VERSION ""

NS_ :

BS_:

BU_: PowertrainControlModule AtmosphericSensor SafetyRestraintSystem2 Aftertreatment_2_GasOutlet Aftertreatment_2_GasIntake DieselParticulateFilterControl Turbocharger SafetyRestraintSystem1 CabDisplay2 Aftertreatment_1_GasOutlet Aftertreatment_1_GasIntake OnBoardDataLogger OffBoardDiagnosticTool2 OffBoardDiagnosticTool1 FileServer ParkingBrakeController SeatController2 FanDriveController SteeringColumnUnit CommunicationUnitRadio CommunicationUnitSatellite CommunicationUnitCellular PropulsionBatteryCharger ChassisController2 ChassisController1 EngineValveControl AuxiliaryHeater2 AuxiliaryHeater1 ClutchUnit RampControl InformationSystem1 SuspensionSystemController2 OilSensor VehicleDynamicStability ExhaustEmissionController TransmissionDisplay2 TransmissionDisplay1 ClimateControl2 WaterPumpController RearAxleSteeringController LightingOperatorControl SeatController1 IgnitionController2 IgnitionController1 TirePressureController CabController2 CabController1 PneumaticSystemController SuspensionSystemController1 HydraulicPumpController EnduranceBrakingSystem RetarderExhaustEngine2 OnBoardDiagnosticUnit HeadwayController RetarderExhaustEngine1 CabDisplay1 ManagementComputer VirtualTerminal OffVehicleGateway PowerTakeOffFront HitchControl AuxiliaryValveControl BodyController TractorTrailerBridge1 StarterSystem ElectricalSystem VehicleSecurity VehicleNavigation AerodynamicControl ElectricalChargingSystem ClimateControl1 TripRecorder InstrumentCluster SuspensionDriveAxle2 SuspensionDriveAxle1 SuspensionSteerAxle SteeringController FuelSystem CruiseControl RetarderDriveline RetarderEngine BrakesDriveAxle2 BrakesDriveAxle1 BrakesSystemController BrakesSteerAxle AxleDrive2 AxleDrive1 AxleSteering PowerTakeOff ShiftConsoleSecondary ShiftConsolePrimary Transmission2 Transmission1 Engine2 Engine1
VAL_TABLE_ FMI 0 "Above normal (most severe)" 1 "Below normal (most severe)" 2 "Data erratic" 3 "Voltage above normal" 4 "Voltage below normal" 5 "Current below normal" 6 "Current above normal" 7 "Mechanical system not responding" 8 "Abnormal frequency" 9 "Abnormal update rate" 10 "Abnormal rate of change" 11 "Root cause not known" 12 "Bad intelligent device" 13 "Out of calibration" 14 "Special intstructions" 15 "Above normal (least severe)" 16 "Above normal (moderately severe)" 17 "Below normal (least severe)" 18 "Below normal (moderately severe)" 19 "Received network data in error" 31 "Not available" ;
VAL_TABLE_ TireLocation_MUX 51 "TirePress_33_MUX_51" 50 "TirePress_32_MUX_50" 49 "TirePress_31_MUX_49" 48 "TirePress_30_MUX_48" 35 "TirePress_23_MUX_35" 34 "TirePress_22_MUX_34" 33 "TirePress_21_MUX_33" 32 "TirePress_20_MUX_32" 19 "TirePress_13_MUX_19" 18 "TirePress_12_MUX_18" 17 "TirePress_11_MUX_17" 16 "TirePress_10_MUX_16" 1 "TirePress_01_MUX_1" 0 "TirePress_00_MUX_0" ;

BO_ 2147483936 The11BitCANIDMessage: 8 Vector__XXX
 SG_ ABSOffroadRequest : 0|2@1+ (1,0) [0|1] "" Vector__XXX

BO_ 2381315838 PropA2: 8 Vector__XXX
 SG_ ManufacturerSpecificInformation : 0|64@1+ (1,0) [0|0] "" Vector__XXX

BO_ 2365510142 DM09: 8 Vector__XXX

BO_ 2365475326 GBSD: 8 Vector__XXX
 SG_ GroundBasedDirection : 56|2@1+ (1,0) [0|0] "" Vector__XXX
 SG_ GroundBasedImplementDistance : 16|32@1+ (1,0) [0|0] "" Vector__XXX
 SG_ GroundBasedImplementSpeed : 0|16@1+ (1,0) [0|0] "" Vector__XXX

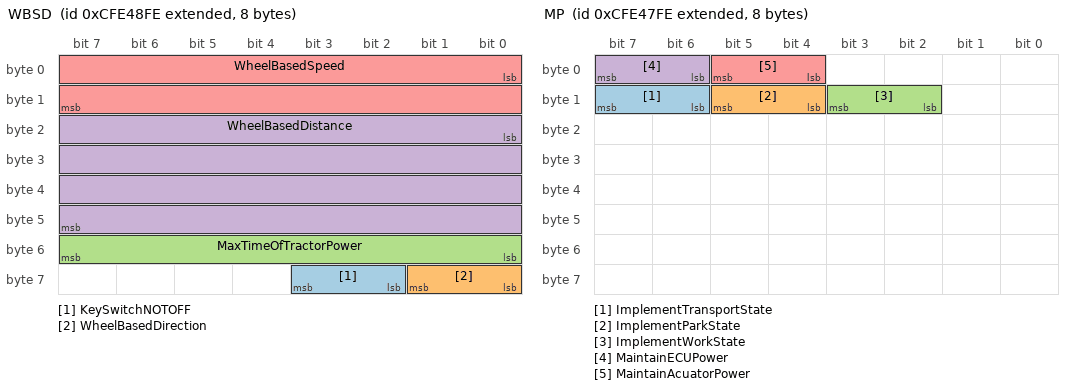
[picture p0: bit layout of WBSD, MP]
BO_ 2365475070 WBSD: 8 Vector__XXX
 SG_ KeySwitchNOTOFF : 58|2@1+ (1,0) [0|0] "" Vector__XXX
 SG_ WheelBasedDirection : 56|2@1+ (1,0) [0|0] "" Vector__XXX
 SG_ MaxTimeOfTractorPower : 48|8@1+ (1,0) [0|0] "" Vector__XXX
 SG_ WheelBasedDistance : 16|32@1+ (1,0) [0|0] "" Vector__XXX
 SG_ WheelBasedSpeed : 0|16@1+ (1,0) [0|0] "" Vector__XXX

BO_ 2365474814 MP: 8 Vector__XXX
 SG_ ImplementTransportState : 14|2@1+ (1,0) [0|0] "" Vector__XXX
 SG_ ImplementParkState : 12|2@1+ (1,0) [0|0] "" Vector__XXX
 SG_ ImplementWorkState : 10|2@1+ (1,0) [0|0] "" Vector__XXX
 SG_ MaintainECUPower : 6|2@1+ (1,0) [0|0] "" Vector__XXX
 SG_ MaintainAcuatorPower : 4|2@1+ (1,0) [0|0] "" Vector__XXX

BO_ 2365474558 FHS: 8 Vector__XXX
 SG_ FrontDraft : 24|16@1+ (1,0) [0|0] "" Vector__XXX
 SG_ FrontNominalLowerLinkForce : 16|8@1+ (1,0) [0|0] "" Vector__XXX
 SG_ FrontHitchInworkIndication : 14|2@1+ (1,0) [0|0] "" Vector__XXX
 SG_ FrontHitchPos : 0|8@1+ (1,0) [0|0] "" Vector__XXX

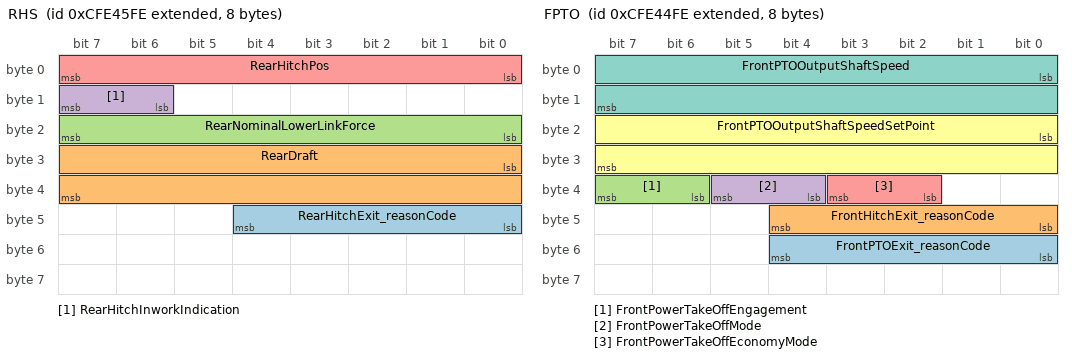
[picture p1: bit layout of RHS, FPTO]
BO_ 2365474302 RHS: 8 Vector__XXX
 SG_ RearHitchExit_reasonCode : 40|5@1+ (1,0) [0|0] "" Vector__XXX
 SG_ RearDraft : 24|16@1+ (1,0) [0|0] "" Vector__XXX
 SG_ RearNominalLowerLinkForce : 16|8@1+ (1,0) [0|0] "" Vector__XXX
 SG_ RearHitchInworkIndication : 14|2@1+ (1,0) [0|0] "" Vector__XXX
 SG_ RearHitchPos : 0|8@1+ (1,0) [0|0] "" Vector__XXX

BO_ 2365474046 FPTO: 8 Vector__XXX
 SG_ FrontPTOExit_reasonCode : 48|5@1+ (1,0) [0|0] "" Vector__XXX
 SG_ FrontHitchExit_reasonCode : 40|5@1+ (1,0) [0|0] "" Vector__XXX
 SG_ FrontPowerTakeOffEngagement : 38|2@1+ (1,0) [0|0] "" Vector__XXX
 SG_ FrontPowerTakeOffMode : 36|2@1+ (1,0) [0|0] "" Vector__XXX
 SG_ FrontPowerTakeOffEconomyMode : 34|2@1+ (1,0) [0|0] "" Vector__XXX
 SG_ FrontPTOOutputShaftSpeedSetPoint : 16|16@1+ (1,0) [0|0] "" Vector__XXX
 SG_ FrontPTOOutputShaftSpeed : 0|16@1+ (1,0) [0|0] "" Vector__XXX

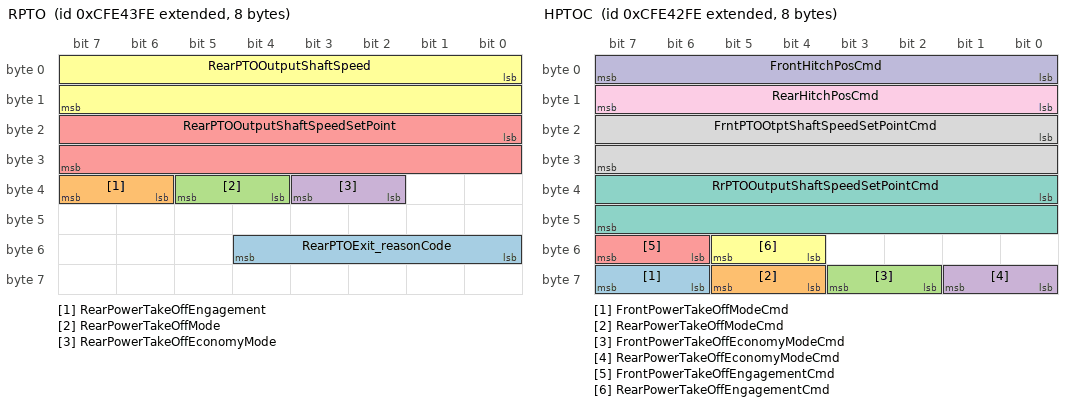
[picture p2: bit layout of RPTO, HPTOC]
BO_ 2365473790 RPTO: 8 Vector__XXX
 SG_ RearPTOExit_reasonCode : 48|5@1+ (1,0) [0|0] "" Vector__XXX
 SG_ RearPowerTakeOffEngagement : 38|2@1+ (1,0) [0|0] "" Vector__XXX
 SG_ RearPowerTakeOffMode : 36|2@1+ (1,0) [0|0] "" Vector__XXX
 SG_ RearPowerTakeOffEconomyMode : 34|2@1+ (1,0) [0|0] "" Vector__XXX
 SG_ RearPTOOutputShaftSpeedSetPoint : 16|16@1+ (1,0) [0|0] "" Vector__XXX
 SG_ RearPTOOutputShaftSpeed : 0|16@1+ (1,0) [0|0] "" Vector__XXX

BO_ 2365473534 HPTOC: 8 Vector__XXX
 SG_ FrontPowerTakeOffModeCmd : 62|2@1+ (1,0) [0|0] "" Vector__XXX
 SG_ RearPowerTakeOffModeCmd : 60|2@1+ (1,0) [0|0] "" Vector__XXX
 SG_ FrontPowerTakeOffEconomyModeCmd : 58|2@1+ (1,0) [0|0] "" Vector__XXX
 SG_ RearPowerTakeOffEconomyModeCmd : 56|2@1+ (1,0) [0|0] "" Vector__XXX
 SG_ FrontPowerTakeOffEngagementCmd : 54|2@1+ (1,0) [0|0] "" Vector__XXX
 SG_ RearPowerTakeOffEngagementCmd : 52|2@1+ (1,0) [0|0] "" Vector__XXX
 SG_ RrPTOOutputShaftSpeedSetPointCmd : 32|16@1+ (1,0) [0|0] "" Vector__XXX
 SG_ FrntPTOOtptShaftSpeedSetPointCmd : 16|16@1+ (1,0) [0|0] "" Vector__XXX
 SG_ RearHitchPosCmd : 8|8@1+ (1,0) [0|0] "" Vector__XXX
 SG_ FrontHitchPosCmd : 0|8@1+ (1,0) [0|0] "" Vector__XXX

BO_ 2365472766 AV15C: 8 Vector__XXX
 SG_ AuxValve15FailSafeModeCmd : 22|2@1+ (1,0) [0|0] "" Vector__XXX
 SG_ AuxValve15StateCmd : 16|4@1+ (1,0) [0|0] "" Vector__XXX
 SG_ AuxValve15PortFlowCmd : 0|8@1+ (1,0) [0|0] "" Vector__XXX

BO_ 2365472510 AV14C: 8 Vector__XXX
 SG_ AuxValve14FailSafeModeCmd : 22|2@1+ (1,0) [0|0] "" Vector__XXX
 SG_ AuxValve14StateCmd : 16|4@1+ (1,0) [0|0] "" Vector__XXX
 SG_ AuxValve14PortFlowCmd : 0|8@1+ (1,0) [0|0] "" Vector__XXX

BO_ 2365472254 AV13C: 8 Vector__XXX
 SG_ AuxValve13FailSafeModeCmd : 22|2@1+ (1,0) [0|0] "" Vector__XXX
 SG_ AuxValve13StateCmd : 16|4@1+ (1,0) [0|0] "" Vector__XXX
 SG_ AuxValve13PortFlowCmd : 0|8@1+ (1,0) [0|0] "" Vector__XXX

BO_ 2365471998 AV12C: 8 Vector__XXX
 SG_ AuxValve12FailSafeModeCmd : 22|2@1+ (1,0) [0|0] "" Vector__XXX
 SG_ AuxValve12StateCmd : 16|4@1+ (1,0) [0|0] "" Vector__XXX
 SG_ AuxValve12PortFlowCmd : 0|8@1+ (1,0) [0|0] "" Vector__XXX

BO_ 2365471742 AV11C: 8 Vector__XXX
 SG_ AuxValve11FailSafeModeCmd : 22|2@1+ (1,0) [0|0] "" Vector__XXX
 SG_ AuxValve11StateCmd : 16|4@1+ (1,0) [0|0] "" Vector__XXX
 SG_ AuxValve11PortFlowCmd : 0|8@1+ (1,0) [0|0] "" Vector__XXX

BO_ 2365471486 AV10C: 8 Vector__XXX
 SG_ AuxValve10FailSafeModeCmd : 22|2@1+ (1,0) [0|0] "" Vector__XXX
 SG_ AuxValve10StateCmd : 16|4@1+ (1,0) [0|0] "" Vector__XXX
 SG_ AuxValve10PortFlowCmd : 0|8@1+ (1,0) [0|0] "" Vector__XXX

BO_ 2365471230 AV09C: 8 Vector__XXX
 SG_ AuxValve9FailSafeModeCmd : 22|2@1+ (1,0) [0|0] "" Vector__XXX
 SG_ AuxValve9StateCmd : 16|4@1+ (1,0) [0|0] "" Vector__XXX
 SG_ AuxValve9PortFlowCmd : 0|8@1+ (1,0) [0|0] "" Vector__XXX

BO_ 2365470974 AV08C: 8 Vector__XXX
 SG_ AuxValve8FailSafeModeCmd : 22|2@1+ (1,0) [0|0] "" Vector__XXX
 SG_ AuxValve8StateCmd : 16|4@1+ (1,0) [0|0] "" Vector__XXX
 SG_ AuxValve8PortFlowCmd : 0|8@1+ (1,0) [0|0] "" Vector__XXX

BO_ 2365470718 AV07C: 8 Vector__XXX
 SG_ AuxValve7FailSafeModeCmd : 22|2@1+ (1,0) [0|0] "" Vector__XXX
 SG_ AuxValve7StateCmd : 16|4@1+ (1,0) [0|0] "" Vector__XXX
 SG_ AuxValve7PortFlowCmd : 0|8@1+ (1,0) [0|0] "" Vector__XXX

BO_ 2365470462 AV06C: 8 Vector__XXX
 SG_ AuxValve6FailSafeModeCmd : 22|2@1+ (1,0) [0|0] "" Vector__XXX
 SG_ AuxValve6StateCmd : 16|4@1+ (1,0) [0|0] "" Vector__XXX
 SG_ AuxValve6PortFlowCmd : 0|8@1+ (1,0) [0|0] "" Vector__XXX

BO_ 2365470206 AV05C: 8 Vector__XXX
 SG_ AuxValve5FailSafeModeCmd : 22|2@1+ (1,0) [0|0] "" Vector__XXX
 SG_ AuxValve5StateCmd : 16|4@1+ (1,0) [0|0] "" Vector__XXX
 SG_ AuxValve5PortFlowCmd : 0|8@1+ (1,0) [0|0] "" Vector__XXX

BO_ 2365469950 AV04C: 8 Vector__XXX
 SG_ AuxValve4FailSafeModeCmd : 22|2@1+ (1,0) [0|0] "" Vector__XXX
 SG_ AuxValve4StateCmd : 16|4@1+ (1,0) [0|0] "" Vector__XXX
 SG_ AuxValve4PortFlowCmd : 0|8@1+ (1,0) [0|0] "" Vector__XXX

BO_ 2365469694 AV03C: 8 Vector__XXX
 SG_ AuxValve3FailSafeModeCmd : 22|2@1+ (1,0) [0|0] "" Vector__XXX
 SG_ AuxValve3StateCmd : 16|4@1+ (1,0) [0|0] "" Vector__XXX
 SG_ AuxValve3PortFlowCmd : 0|8@1+ (1,0) [0|0] "" Vector__XXX

BO_ 2365469438 AV02C: 8 Vector__XXX
 SG_ AuxValve2FailSafeModeCmd : 22|2@1+ (1,0) [0|0] "" Vector__XXX
 SG_ AuxValve2StateCmd : 16|4@1+ (1,0) [0|0] "" Vector__XXX
 SG_ AuxValve2PortFlowCmd : 0|8@1+ (1,0) [0|0] "" Vector__XXX

BO_ 2365469182 AV01C: 8 Vector__XXX
 SG_ AuxValve1FailSafeModeCmd : 22|2@1+ (1,0) [0|0] "" Vector__XXX
 SG_ AuxValve1StateCmd : 16|4@1+ (1,0) [0|0] "" Vector__XXX
 SG_ AuxValve1PortFlowCmd : 0|8@1+ (1,0) [0|0] "" Vector__XXX

BO_ 2365468926 AV00C: 8 Vector__XXX
 SG_ AuxValve0FailSafeModeCmd : 22|2@1+ (1,0) [0|0] "" Vector__XXX
 SG_ AuxValve0StateCmd : 16|4@1+ (1,0) [0|0] "" Vector__XXX
 SG_ AuxValve0PortFlowCmd : 0|8@1+ (1,0) [0|0] "" Vector__XXX

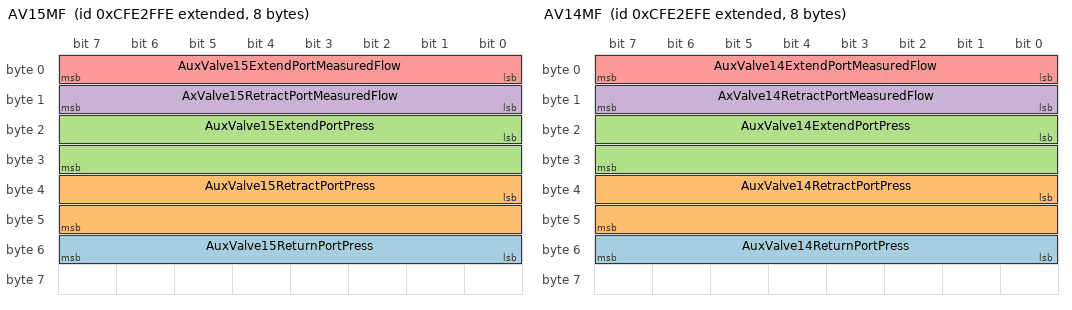
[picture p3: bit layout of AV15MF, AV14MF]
BO_ 2365468670 AV15MF: 8 Vector__XXX
 SG_ AuxValve15ReturnPortPress : 48|8@1+ (1,0) [0|0] "" Vector__XXX
 SG_ AuxValve15RetractPortPress : 32|16@1+ (1,0) [0|0] "" Vector__XXX
 SG_ AuxValve15ExtendPortPress : 16|16@1+ (1,0) [0|0] "" Vector__XXX
 SG_ AxValve15RetractPortMeasuredFlow : 8|8@1+ (1,0) [0|0] "" Vector__XXX
 SG_ AuxValve15ExtendPortMeasuredFlow : 0|8@1+ (1,0) [0|0] "" Vector__XXX

BO_ 2365468414 AV14MF: 8 Vector__XXX
 SG_ AuxValve14ReturnPortPress : 48|8@1+ (1,0) [0|0] "" Vector__XXX
 SG_ AuxValve14RetractPortPress : 32|16@1+ (1,0) [0|0] "" Vector__XXX
 SG_ AuxValve14ExtendPortPress : 16|16@1+ (1,0) [0|0] "" Vector__XXX
 SG_ AxValve14RetractPortMeasuredFlow : 8|8@1+ (1,0) [0|0] "" Vector__XXX
 SG_ AuxValve14ExtendPortMeasuredFlow : 0|8@1+ (1,0) [0|0] "" Vector__XXX

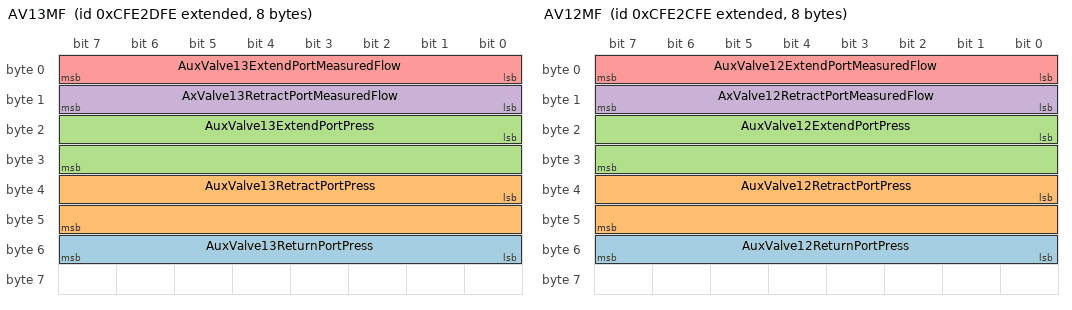
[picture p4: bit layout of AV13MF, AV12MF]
BO_ 2365468158 AV13MF: 8 Vector__XXX
 SG_ AuxValve13ReturnPortPress : 48|8@1+ (1,0) [0|0] "" Vector__XXX
 SG_ AuxValve13RetractPortPress : 32|16@1+ (1,0) [0|0] "" Vector__XXX
 SG_ AuxValve13ExtendPortPress : 16|16@1+ (1,0) [0|0] "" Vector__XXX
 SG_ AxValve13RetractPortMeasuredFlow : 8|8@1+ (1,0) [0|0] "" Vector__XXX
 SG_ AuxValve13ExtendPortMeasuredFlow : 0|8@1+ (1,0) [0|0] "" Vector__XXX

BO_ 2365467902 AV12MF: 8 Vector__XXX
 SG_ AuxValve12ReturnPortPress : 48|8@1+ (1,0) [0|0] "" Vector__XXX
 SG_ AuxValve12RetractPortPress : 32|16@1+ (1,0) [0|0] "" Vector__XXX
 SG_ AuxValve12ExtendPortPress : 16|16@1+ (1,0) [0|0] "" Vector__XXX
 SG_ AxValve12RetractPortMeasuredFlow : 8|8@1+ (1,0) [0|0] "" Vector__XXX
 SG_ AuxValve12ExtendPortMeasuredFlow : 0|8@1+ (1,0) [0|0] "" Vector__XXX

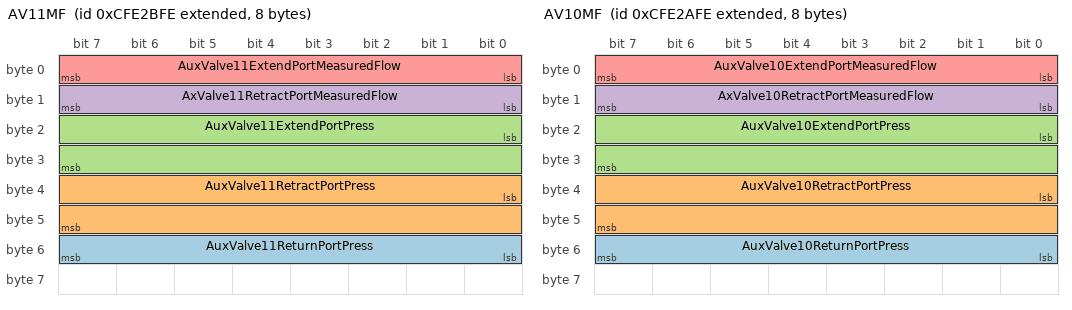
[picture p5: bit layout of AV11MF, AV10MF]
BO_ 2365467646 AV11MF: 8 Vector__XXX
 SG_ AuxValve11ReturnPortPress : 48|8@1+ (1,0) [0|0] "" Vector__XXX
 SG_ AuxValve11RetractPortPress : 32|16@1+ (1,0) [0|0] "" Vector__XXX
 SG_ AuxValve11ExtendPortPress : 16|16@1+ (1,0) [0|0] "" Vector__XXX
 SG_ AxValve11RetractPortMeasuredFlow : 8|8@1+ (1,0) [0|0] "" Vector__XXX
 SG_ AuxValve11ExtendPortMeasuredFlow : 0|8@1+ (1,0) [0|0] "" Vector__XXX

BO_ 2365467390 AV10MF: 8 Vector__XXX
 SG_ AuxValve10ReturnPortPress : 48|8@1+ (1,0) [0|0] "" Vector__XXX
 SG_ AuxValve10RetractPortPress : 32|16@1+ (1,0) [0|0] "" Vector__XXX
 SG_ AuxValve10ExtendPortPress : 16|16@1+ (1,0) [0|0] "" Vector__XXX
 SG_ AxValve10RetractPortMeasuredFlow : 8|8@1+ (1,0) [0|0] "" Vector__XXX
 SG_ AuxValve10ExtendPortMeasuredFlow : 0|8@1+ (1,0) [0|0] "" Vector__XXX

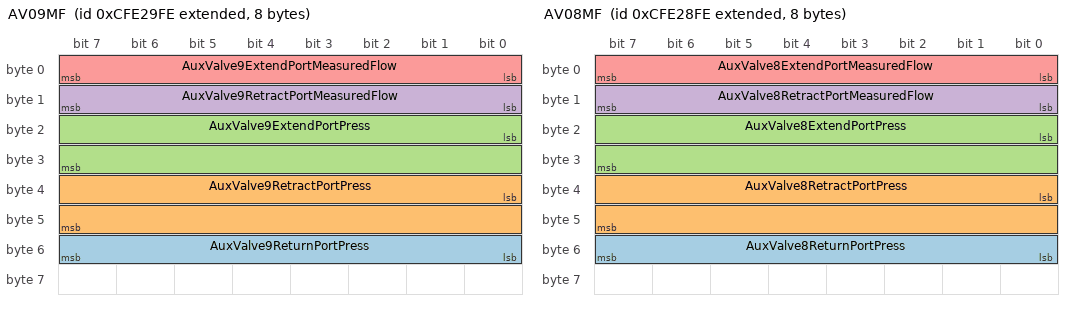
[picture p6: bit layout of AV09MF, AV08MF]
BO_ 2365467134 AV09MF: 8 Vector__XXX
 SG_ AuxValve9ReturnPortPress : 48|8@1+ (1,0) [0|0] "" Vector__XXX
 SG_ AuxValve9RetractPortPress : 32|16@1+ (1,0) [0|0] "" Vector__XXX
 SG_ AuxValve9ExtendPortPress : 16|16@1+ (1,0) [0|0] "" Vector__XXX
 SG_ AuxValve9RetractPortMeasuredFlow : 8|8@1+ (1,0) [0|0] "" Vector__XXX
 SG_ AuxValve9ExtendPortMeasuredFlow : 0|8@1+ (1,0) [0|0] "" Vector__XXX

BO_ 2365466878 AV08MF: 8 Vector__XXX
 SG_ AuxValve8ReturnPortPress : 48|8@1+ (1,0) [0|0] "" Vector__XXX
 SG_ AuxValve8RetractPortPress : 32|16@1+ (1,0) [0|0] "" Vector__XXX
 SG_ AuxValve8ExtendPortPress : 16|16@1+ (1,0) [0|0] "" Vector__XXX
 SG_ AuxValve8RetractPortMeasuredFlow : 8|8@1+ (1,0) [0|0] "" Vector__XXX
 SG_ AuxValve8ExtendPortMeasuredFlow : 0|8@1+ (1,0) [0|0] "" Vector__XXX

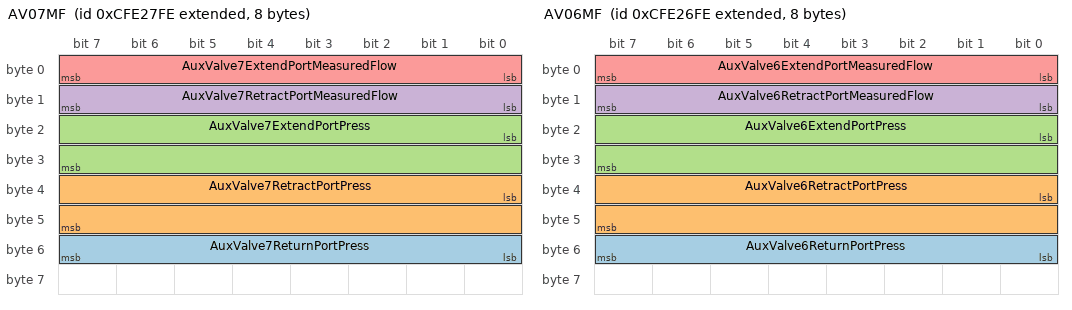
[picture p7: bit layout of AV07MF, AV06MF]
BO_ 2365466622 AV07MF: 8 Vector__XXX
 SG_ AuxValve7ReturnPortPress : 48|8@1+ (1,0) [0|0] "" Vector__XXX
 SG_ AuxValve7RetractPortPress : 32|16@1+ (1,0) [0|0] "" Vector__XXX
 SG_ AuxValve7ExtendPortPress : 16|16@1+ (1,0) [0|0] "" Vector__XXX
 SG_ AuxValve7RetractPortMeasuredFlow : 8|8@1+ (1,0) [0|0] "" Vector__XXX
 SG_ AuxValve7ExtendPortMeasuredFlow : 0|8@1+ (1,0) [0|0] "" Vector__XXX

BO_ 2365466366 AV06MF: 8 Vector__XXX
 SG_ AuxValve6ReturnPortPress : 48|8@1+ (1,0) [0|0] "" Vector__XXX
 SG_ AuxValve6RetractPortPress : 32|16@1+ (1,0) [0|0] "" Vector__XXX
 SG_ AuxValve6ExtendPortPress : 16|16@1+ (1,0) [0|0] "" Vector__XXX
 SG_ AuxValve6RetractPortMeasuredFlow : 8|8@1+ (1,0) [0|0] "" Vector__XXX
 SG_ AuxValve6ExtendPortMeasuredFlow : 0|8@1+ (1,0) [0|0] "" Vector__XXX

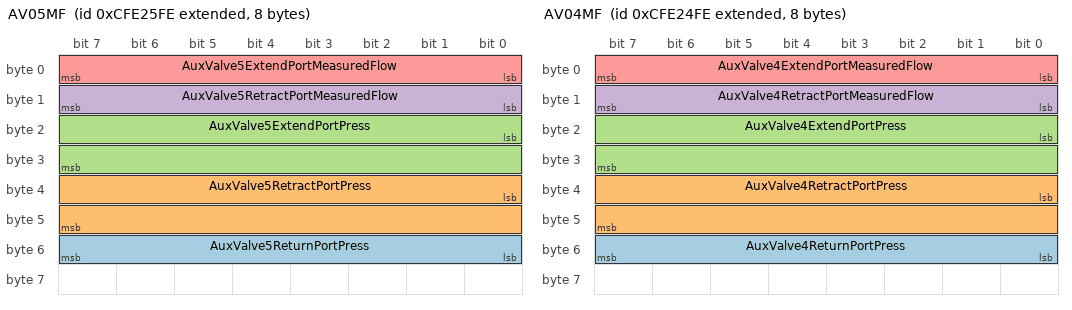
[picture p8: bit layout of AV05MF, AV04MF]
BO_ 2365466110 AV05MF: 8 Vector__XXX
 SG_ AuxValve5ReturnPortPress : 48|8@1+ (1,0) [0|0] "" Vector__XXX
 SG_ AuxValve5RetractPortPress : 32|16@1+ (1,0) [0|0] "" Vector__XXX
 SG_ AuxValve5ExtendPortPress : 16|16@1+ (1,0) [0|0] "" Vector__XXX
 SG_ AuxValve5RetractPortMeasuredFlow : 8|8@1+ (1,0) [0|0] "" Vector__XXX
 SG_ AuxValve5ExtendPortMeasuredFlow : 0|8@1+ (1,0) [0|0] "" Vector__XXX

BO_ 2365465854 AV04MF: 8 Vector__XXX
 SG_ AuxValve4ReturnPortPress : 48|8@1+ (1,0) [0|0] "" Vector__XXX
 SG_ AuxValve4RetractPortPress : 32|16@1+ (1,0) [0|0] "" Vector__XXX
 SG_ AuxValve4ExtendPortPress : 16|16@1+ (1,0) [0|0] "" Vector__XXX
 SG_ AuxValve4RetractPortMeasuredFlow : 8|8@1+ (1,0) [0|0] "" Vector__XXX
 SG_ AuxValve4ExtendPortMeasuredFlow : 0|8@1+ (1,0) [0|0] "" Vector__XXX

BO_ 2365465598 AV03MF: 8 Vector__XXX
 SG_ AuxValve3ReturnPortPress : 48|8@1+ (1,0) [0|0] "" Vector__XXX
 SG_ AuxValve3RetractPortPress : 32|16@1+ (1,0) [0|0] "" Vector__XXX
 SG_ AuxValve3ExtendPortPress : 16|16@1+ (1,0) [0|0] "" Vector__XXX
 SG_ AuxValve3RetractPortMeasuredFlow : 8|8@1+ (1,0) [0|0] "" Vector__XXX
 SG_ AuxValve3ExtendPortMeasuredFlow : 0|8@1+ (1,0) [0|0] "" Vector__XXX

BO_ 2365465342 AV02MF: 8 Vector__XXX
 SG_ AuxValve2ReturnPortPress : 48|8@1+ (1,0) [0|0] "" Vector__XXX
 SG_ AuxValve2RetractPortPress : 32|16@1+ (1,0) [0|0] "" Vector__XXX
 SG_ AuxValve2ExtendPortPress : 16|16@1+ (1,0) [0|0] "" Vector__XXX
 SG_ AuxValve2RetractPortMeasuredFlow : 8|8@1+ (1,0) [0|0] "" Vector__XXX
 SG_ AuxValve2ExtendPortMeasuredFlow : 0|8@1+ (1,0) [0|0] "" Vector__XXX

BO_ 2365465086 AV01MF: 8 Vector__XXX
 SG_ AuxValve1ReturnPortPress : 48|8@1+ (1,0) [0|0] "" Vector__XXX
 SG_ AuxValve1RetractPortPress : 32|16@1+ (1,0) [0|0] "" Vector__XXX
 SG_ AuxValve1ExtendPortPress : 16|16@1+ (1,0) [0|0] "" Vector__XXX
 SG_ AuxValve1RetractPortMeasuredFlow : 8|8@1+ (1,0) [0|0] "" Vector__XXX
 SG_ AuxValve1ExtendPortMeasuredFlow : 0|8@1+ (1,0) [0|0] "" Vector__XXX

BO_ 2365464830 AV00MF: 8 Vector__XXX
 SG_ AuxValve0ReturnPortPress : 48|8@1+ (1,0) [0|0] "" Vector__XXX
 SG_ AuxValve0RetractPortPress : 32|16@1+ (1,0) [0|0] "" Vector__XXX
 SG_ AuxValve0ExtendPortPress : 16|16@1+ (1,0) [0|0] "" Vector__XXX
 SG_ AuxValve0RetractPortMeasuredFlow : 8|8@1+ (1,0) [0|0] "" Vector__XXX
 SG_ AuxValve0ExtendPortMeasuredFlow : 0|8@1+ (1,0) [0|0] "" Vector__XXX

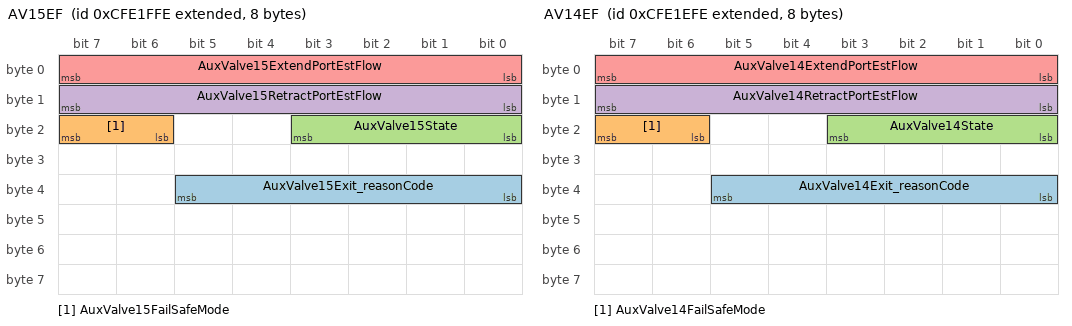
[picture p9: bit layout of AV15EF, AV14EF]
BO_ 2365464574 AV15EF: 8 Vector__XXX
 SG_ AuxValve15Exit_reasonCode : 32|6@1+ (1,0) [0|0] "" Vector__XXX
 SG_ AuxValve15FailSafeMode : 22|2@1+ (1,0) [0|0] "" Vector__XXX
 SG_ AuxValve15State : 16|4@1+ (1,0) [0|0] "" Vector__XXX
 SG_ AuxValve15RetractPortEstFlow : 8|8@1+ (1,0) [0|0] "" Vector__XXX
 SG_ AuxValve15ExtendPortEstFlow : 0|8@1+ (1,0) [0|0] "" Vector__XXX

BO_ 2365464318 AV14EF: 8 Vector__XXX
 SG_ AuxValve14Exit_reasonCode : 32|6@1+ (1,0) [0|0] "" Vector__XXX
 SG_ AuxValve14FailSafeMode : 22|2@1+ (1,0) [0|0] "" Vector__XXX
 SG_ AuxValve14State : 16|4@1+ (1,0) [0|0] "" Vector__XXX
 SG_ AuxValve14RetractPortEstFlow : 8|8@1+ (1,0) [0|0] "" Vector__XXX
 SG_ AuxValve14ExtendPortEstFlow : 0|8@1+ (1,0) [0|0] "" Vector__XXX

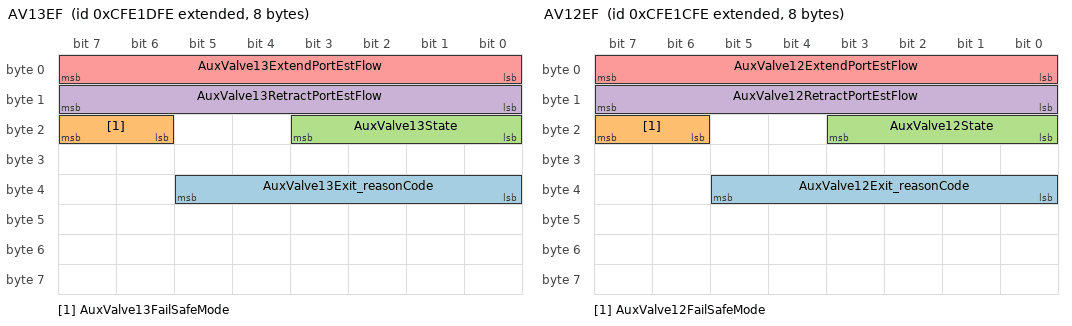
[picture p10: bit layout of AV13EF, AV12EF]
BO_ 2365464062 AV13EF: 8 Vector__XXX
 SG_ AuxValve13Exit_reasonCode : 32|6@1+ (1,0) [0|0] "" Vector__XXX
 SG_ AuxValve13FailSafeMode : 22|2@1+ (1,0) [0|0] "" Vector__XXX
 SG_ AuxValve13State : 16|4@1+ (1,0) [0|0] "" Vector__XXX
 SG_ AuxValve13RetractPortEstFlow : 8|8@1+ (1,0) [0|0] "" Vector__XXX
 SG_ AuxValve13ExtendPortEstFlow : 0|8@1+ (1,0) [0|0] "" Vector__XXX

BO_ 2365463806 AV12EF: 8 Vector__XXX
 SG_ AuxValve12Exit_reasonCode : 32|6@1+ (1,0) [0|0] "" Vector__XXX
 SG_ AuxValve12FailSafeMode : 22|2@1+ (1,0) [0|0] "" Vector__XXX
 SG_ AuxValve12State : 16|4@1+ (1,0) [0|0] "" Vector__XXX
 SG_ AuxValve12RetractPortEstFlow : 8|8@1+ (1,0) [0|0] "" Vector__XXX
 SG_ AuxValve12ExtendPortEstFlow : 0|8@1+ (1,0) [0|0] "" Vector__XXX

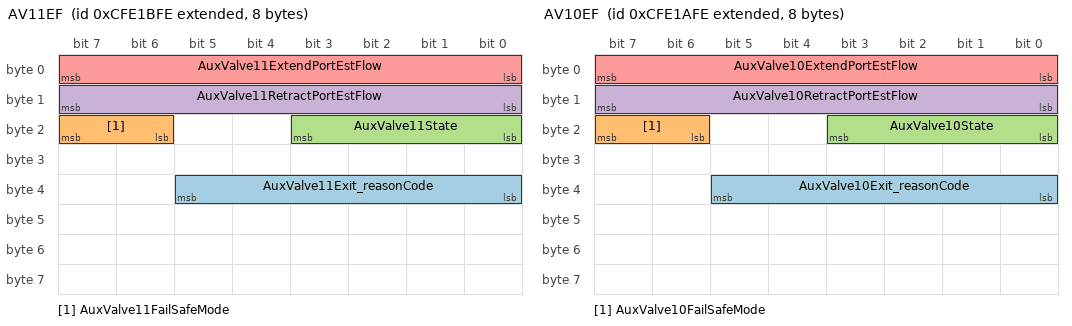
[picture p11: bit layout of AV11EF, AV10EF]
BO_ 2365463550 AV11EF: 8 Vector__XXX
 SG_ AuxValve11Exit_reasonCode : 32|6@1+ (1,0) [0|0] "" Vector__XXX
 SG_ AuxValve11FailSafeMode : 22|2@1+ (1,0) [0|0] "" Vector__XXX
 SG_ AuxValve11State : 16|4@1+ (1,0) [0|0] "" Vector__XXX
 SG_ AuxValve11RetractPortEstFlow : 8|8@1+ (1,0) [0|0] "" Vector__XXX
 SG_ AuxValve11ExtendPortEstFlow : 0|8@1+ (1,0) [0|0] "" Vector__XXX

BO_ 2365463294 AV10EF: 8 Vector__XXX
 SG_ AuxValve10Exit_reasonCode : 32|6@1+ (1,0) [0|0] "" Vector__XXX
 SG_ AuxValve10FailSafeMode : 22|2@1+ (1,0) [0|0] "" Vector__XXX
 SG_ AuxValve10State : 16|4@1+ (1,0) [0|0] "" Vector__XXX
 SG_ AuxValve10RetractPortEstFlow : 8|8@1+ (1,0) [0|0] "" Vector__XXX
 SG_ AuxValve10ExtendPortEstFlow : 0|8@1+ (1,0) [0|0] "" Vector__XXX

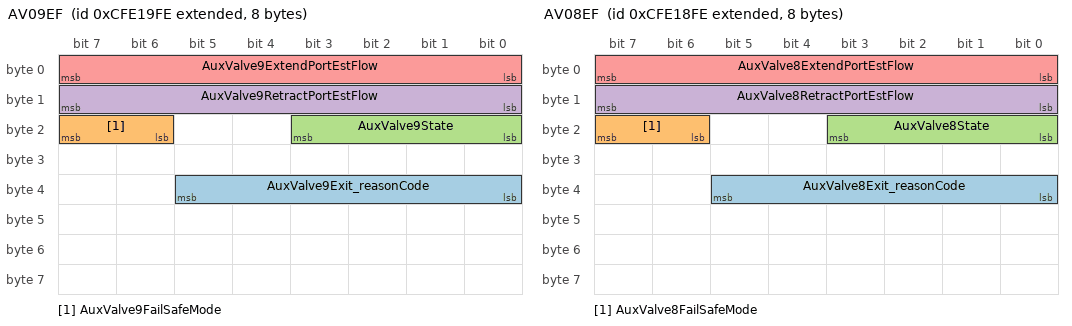
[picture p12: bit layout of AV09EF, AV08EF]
BO_ 2365463038 AV09EF: 8 Vector__XXX
 SG_ AuxValve9Exit_reasonCode : 32|6@1+ (1,0) [0|0] "" Vector__XXX
 SG_ AuxValve9FailSafeMode : 22|2@1+ (1,0) [0|0] "" Vector__XXX
 SG_ AuxValve9State : 16|4@1+ (1,0) [0|0] "" Vector__XXX
 SG_ AuxValve9RetractPortEstFlow : 8|8@1+ (1,0) [0|0] "" Vector__XXX
 SG_ AuxValve9ExtendPortEstFlow : 0|8@1+ (1,0) [0|0] "" Vector__XXX

BO_ 2365462782 AV08EF: 8 Vector__XXX
 SG_ AuxValve8Exit_reasonCode : 32|6@1+ (1,0) [0|0] "" Vector__XXX
 SG_ AuxValve8FailSafeMode : 22|2@1+ (1,0) [0|0] "" Vector__XXX
 SG_ AuxValve8State : 16|4@1+ (1,0) [0|0] "" Vector__XXX
 SG_ AuxValve8RetractPortEstFlow : 8|8@1+ (1,0) [0|0] "" Vector__XXX
 SG_ AuxValve8ExtendPortEstFlow : 0|8@1+ (1,0) [0|0] "" Vector__XXX

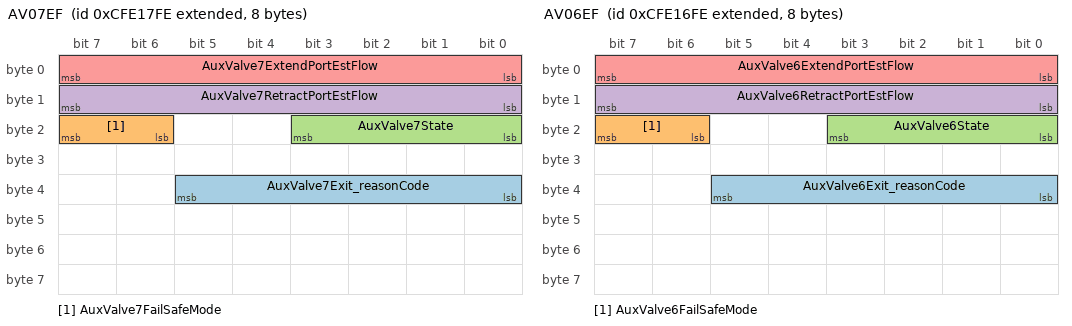
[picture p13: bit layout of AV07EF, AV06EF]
BO_ 2365462526 AV07EF: 8 Vector__XXX
 SG_ AuxValve7Exit_reasonCode : 32|6@1+ (1,0) [0|0] "" Vector__XXX
 SG_ AuxValve7FailSafeMode : 22|2@1+ (1,0) [0|0] "" Vector__XXX
 SG_ AuxValve7State : 16|4@1+ (1,0) [0|0] "" Vector__XXX
 SG_ AuxValve7RetractPortEstFlow : 8|8@1+ (1,0) [0|0] "" Vector__XXX
 SG_ AuxValve7ExtendPortEstFlow : 0|8@1+ (1,0) [0|0] "" Vector__XXX

BO_ 2365462270 AV06EF: 8 Vector__XXX
 SG_ AuxValve6Exit_reasonCode : 32|6@1+ (1,0) [0|0] "" Vector__XXX
 SG_ AuxValve6FailSafeMode : 22|2@1+ (1,0) [0|0] "" Vector__XXX
 SG_ AuxValve6State : 16|4@1+ (1,0) [0|0] "" Vector__XXX
 SG_ AuxValve6RetractPortEstFlow : 8|8@1+ (1,0) [0|0] "" Vector__XXX
 SG_ AuxValve6ExtendPortEstFlow : 0|8@1+ (1,0) [0|0] "" Vector__XXX

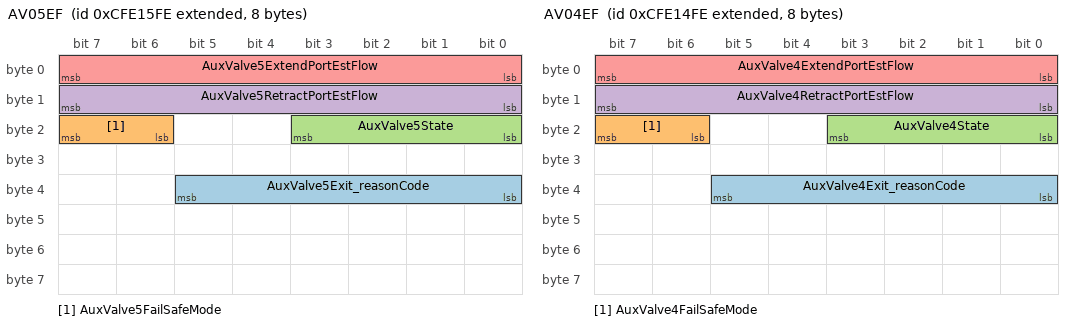
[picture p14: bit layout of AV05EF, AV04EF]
BO_ 2365462014 AV05EF: 8 Vector__XXX
 SG_ AuxValve5Exit_reasonCode : 32|6@1+ (1,0) [0|0] "" Vector__XXX
 SG_ AuxValve5FailSafeMode : 22|2@1+ (1,0) [0|0] "" Vector__XXX
 SG_ AuxValve5State : 16|4@1+ (1,0) [0|0] "" Vector__XXX
 SG_ AuxValve5RetractPortEstFlow : 8|8@1+ (1,0) [0|0] "" Vector__XXX
 SG_ AuxValve5ExtendPortEstFlow : 0|8@1+ (1,0) [0|0] "" Vector__XXX

BO_ 2365461758 AV04EF: 8 Vector__XXX
 SG_ AuxValve4Exit_reasonCode : 32|6@1+ (1,0) [0|0] "" Vector__XXX
 SG_ AuxValve4FailSafeMode : 22|2@1+ (1,0) [0|0] "" Vector__XXX
 SG_ AuxValve4State : 16|4@1+ (1,0) [0|0] "" Vector__XXX
 SG_ AuxValve4RetractPortEstFlow : 8|8@1+ (1,0) [0|0] "" Vector__XXX
 SG_ AuxValve4ExtendPortEstFlow : 0|8@1+ (1,0) [0|0] "" Vector__XXX

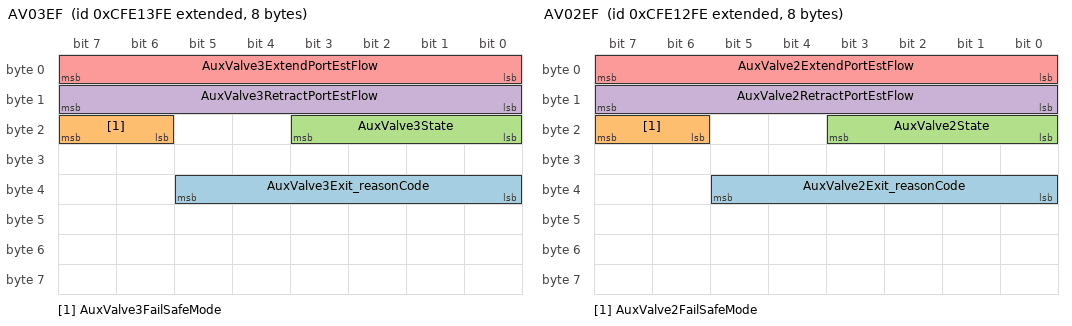
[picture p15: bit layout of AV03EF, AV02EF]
BO_ 2365461502 AV03EF: 8 Vector__XXX
 SG_ AuxValve3Exit_reasonCode : 32|6@1+ (1,0) [0|0] "" Vector__XXX
 SG_ AuxValve3FailSafeMode : 22|2@1+ (1,0) [0|0] "" Vector__XXX
 SG_ AuxValve3State : 16|4@1+ (1,0) [0|0] "" Vector__XXX
 SG_ AuxValve3RetractPortEstFlow : 8|8@1+ (1,0) [0|0] "" Vector__XXX
 SG_ AuxValve3ExtendPortEstFlow : 0|8@1+ (1,0) [0|0] "" Vector__XXX

BO_ 2365461246 AV02EF: 8 Vector__XXX
 SG_ AuxValve2Exit_reasonCode : 32|6@1+ (1,0) [0|0] "" Vector__XXX
 SG_ AuxValve2FailSafeMode : 22|2@1+ (1,0) [0|0] "" Vector__XXX
 SG_ AuxValve2State : 16|4@1+ (1,0) [0|0] "" Vector__XXX
 SG_ AuxValve2RetractPortEstFlow : 8|8@1+ (1,0) [0|0] "" Vector__XXX
 SG_ AuxValve2ExtendPortEstFlow : 0|8@1+ (1,0) [0|0] "" Vector__XXX

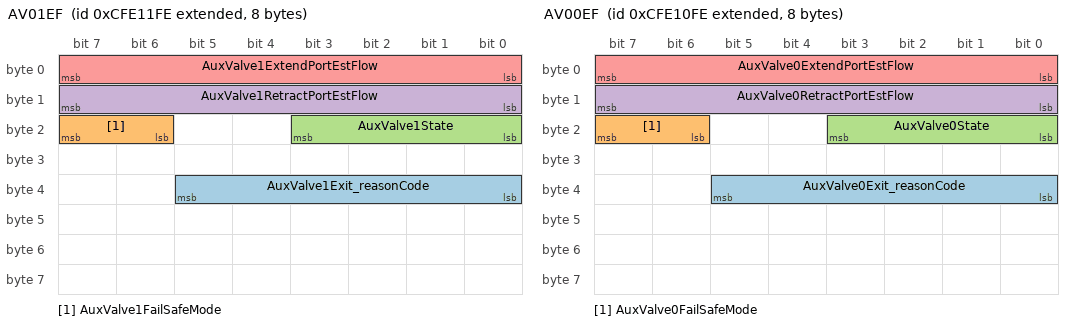
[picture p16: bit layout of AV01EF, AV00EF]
BO_ 2365460990 AV01EF: 8 Vector__XXX
 SG_ AuxValve1Exit_reasonCode : 32|6@1+ (1,0) [0|0] "" Vector__XXX
 SG_ AuxValve1FailSafeMode : 22|2@1+ (1,0) [0|0] "" Vector__XXX
 SG_ AuxValve1State : 16|4@1+ (1,0) [0|0] "" Vector__XXX
 SG_ AuxValve1RetractPortEstFlow : 8|8@1+ (1,0) [0|0] "" Vector__XXX
 SG_ AuxValve1ExtendPortEstFlow : 0|8@1+ (1,0) [0|0] "" Vector__XXX

BO_ 2365460734 AV00EF: 8 Vector__XXX
 SG_ AuxValve0Exit_reasonCode : 32|6@1+ (1,0) [0|0] "" Vector__XXX
 SG_ AuxValve0FailSafeMode : 22|2@1+ (1,0) [0|0] "" Vector__XXX
 SG_ AuxValve0State : 16|4@1+ (1,0) [0|0] "" Vector__XXX
 SG_ AuxValve0RetractPortEstFlow : 8|8@1+ (1,0) [0|0] "" Vector__XXX
 SG_ AuxValve0ExtendPortEstFlow : 0|8@1+ (1,0) [0|0] "" Vector__XXX

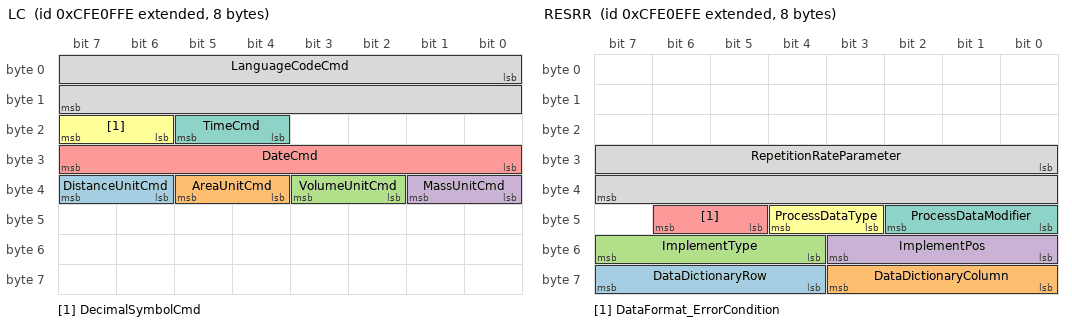
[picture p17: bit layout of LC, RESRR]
BO_ 2365460478 LC: 8 Vector__XXX
 SG_ DistanceUnitCmd : 38|2@1+ (1,0) [0|0] "" Vector__XXX
 SG_ AreaUnitCmd : 36|2@1+ (1,0) [0|0] "" Vector__XXX
 SG_ VolumeUnitCmd : 34|2@1+ (1,0) [0|0] "" Vector__XXX
 SG_ MassUnitCmd : 32|2@1+ (1,0) [0|0] "" Vector__XXX
 SG_ DateCmd : 24|8@1+ (1,0) [0|0] "" Vector__XXX
 SG_ DecimalSymbolCmd : 22|2@1+ (1,0) [0|0] "" Vector__XXX
 SG_ TimeCmd : 20|2@1+ (1,0) [0|0] "" Vector__XXX
 SG_ LanguageCodeCmd : 0|16@1+ (1,0) [0|0] "" Vector__XXX

BO_ 2365460222 RESRR: 8 Vector__XXX
 SG_ DataDictionaryRow : 60|4@1+ (1,0) [0|0] "" Vector__XXX
 SG_ DataDictionaryColumn : 56|4@1+ (1,0) [0|0] "" Vector__XXX
 SG_ ImplementType : 52|4@1+ (1,0) [0|0] "" Vector__XXX
 SG_ ImplementPos : 48|4@1+ (1,0) [0|0] "" Vector__XXX
 SG_ DataFormat_ErrorCondition : 45|2@1+ (1,0) [0|0] "" Vector__XXX
 SG_ ProcessDataType : 43|2@1+ (1,0) [0|0] "" Vector__XXX
 SG_ ProcessDataModifier : 40|3@1+ (1,0) [0|0] "" Vector__XXX
 SG_ RepetitionRateParameter : 24|16@1+ (1,0) [0|0] "" Vector__XXX

BO_ 2365459454 IRC: 8 Vector__XXX

BO_ 2365459198 IRCR: 8 Vector__XXX

BO_ 2365458942 TFR: 8 Vector__XXX

BO_ 2365458686 RTF: 8 Vector__XXX

BO_ 2365447934 MAM21: 8 Vector__XXX

BO_ 2365447678 MAM11: 8 Vector__XXX

BO_ 2365444094 WSM: 8 Vector__XXX
 SG_ NumberOfMembers : 0|8@1+ (1,0) [0|0] "" Vector__XXX

BO_ 2365443838 WSMM: 8 Vector__XXX
 SG_ NAMEOfWorkingSetMember : 0|64@1+ (1,0) [0|0] "" Vector__XXX

BO_ 2365434878 RCMS: 8 Vector__XXX
 SG_ PGNOfConfigurableMessageDesired : 8|24@1+ (1,0) [0|16777215] "" Vector__XXX
 SG_ MessageSelectionCtrl : 0|8@1+ (1,0) [0|250] "" Vector__XXX

BO_ 2566754814 ACS: 8 Vector__XXX
 SG_ AutomaticTransferSwitchStatus : 8|3@1+ (1,0) [0|7] "" Vector__XXX
 SG_ UtilityCircuitBreakerStatus : 3|3@1+ (1,0) [0|7] "" Vector__XXX
 SG_ GeneratorCircuitBreakerStatus : 0|3@1+ (1,0) [0|7] "" Vector__XXX

BO_ 2566754302 GTACPP: 8 Vector__XXX
 SG_ GeneratorTotalPercentKVAr : 32|16@1+ (0.0078125,-251) [-251|250.99] "%" Vector__XXX
 SG_ GeneratorTotalPercentKVA : 16|16@1+ (0.0078125,-251) [-251|250.99] "%" Vector__XXX
 SG_ GeneratorTotalPercentKW : 0|16@1+ (0.0078125,-251) [-251|250.99] "%" Vector__XXX

BO_ 2566754046 GTACER: 8 Vector__XXX
 SG_ GeneratorTotalKVArHoursImport : 32|32@1+ (1,0) [0|4211081215] "kVArh" Vector__XXX
 SG_ GeneratorTotalKVArHoursExport : 0|32@1+ (1,0) [0|4211081215] "kVArh" Vector__XXX

BO_ 2566753790 UTACER: 8 Vector__XXX
 SG_ UtilityTotalKVArHoursImport : 32|32@1+ (1,0) [0|4211081215] "kVArh" Vector__XXX
 SG_ UtilityTotalKVArHoursExport : 0|32@1+ (1,0) [0|4211081215] "kVArh" Vector__XXX

BO_ 2365411582 GPM19: 8 Vector__XXX

BO_ 2365411326 GPM26: 8 Vector__XXX

BO_ 2365411070 GPM27: 8 Vector__XXX

BO_ 2365410814 GPM28: 8 Vector__XXX

BO_ 2365410558 GPM29: 8 Vector__XXX

BO_ 2365410302 GPM210: 8 Vector__XXX

BO_ 2365410046 GPM211: 8 Vector__XXX

BO_ 2365408254 MSSC: 8 Vector__XXX
 SG_ MachineSelectedDirectionCmd : 56|2@1+ (1,0) [0|0] "" Vector__XXX
 SG_ MchnSelectedSpeedExit_reasonCode : 48|5@1+ (1,0) [0|0] "" Vector__XXX
 SG_ MchineSelectedSpeedSetpointLimit : 16|16@1+ (1,0) [0|0] "" Vector__XXX
 SG_ MachineSelectedSpeedSetpointCmd : 0|16@1+ (1,0) [0|0] "" Vector__XXX

BO_ 2365407998 ICC: 8 Vector__XXX
 SG_ ISOBUSCmplncCrtfctnRfrenceNumber : 48|16@1+ (1,0) [0|0] "" Vector__XXX
 SG_ ISOBUSCmplncCrtfctonTypeTaskCtrl : 39|1@1+ (1,0) [0|0] "" Vector__XXX
 SG_ ISOBUSCmplncCrtfctnTypTCWrkn4326 : 38|1@1+ (1,0) [0|0] "" Vector__XXX
 SG_ ISOBUSCmplncCrtfctnTypTCWrkngStM : 37|1@1+ (1,0) [0|0] "" Vector__XXX
 SG_ ISOBUSCmplncCrtfctnTypFileServer : 36|1@1+ (1,0) [0|0] "" Vector__XXX
 SG_ ISOBUSCmplncCrtfctnTypGPSRceiver : 35|1@1+ (1,0) [0|0] "" Vector__XXX
 SG_ ISOBUSCmplncCrtfcationTypeMinECU : 31|1@1+ (1,0) [0|0] "" Vector__XXX
 SG_ ISOBUSCmplncCrtfctnTypTECUClass1 : 30|1@1+ (1,0) [0|0] "" Vector__XXX
 SG_ ISOBUSCmplncCrtfctnTypTECUClass2 : 29|1@1+ (1,0) [0|0] "" Vector__XXX
 SG_ ISOBUSCmplncCrtfctnTypTECUClass3 : 28|1@1+ (1,0) [0|0] "" Vector__XXX
 SG_ ISOBUSCmplncCrtfctnTypeClass3ECU : 27|1@1+ (1,0) [0|0] "" Vector__XXX
 SG_ ISOBUSCmplncCrtfctnTypVrtlTrmnal : 26|1@1+ (1,0) [0|0] "" Vector__XXX
 SG_ ISOBUSCmplncCrtfctnTypVTWrkn4323 : 25|1@1+ (1,0) [0|0] "" Vector__XXX
 SG_ ISOBUSCmplncCrtfctnTypVTWrkngStM : 24|1@1+ (1,0) [0|0] "" Vector__XXX
 SG_ ISOBUSCmplncCrtfctonLaboratoryID : 13|11@1+ (1,0) [0|0] "" Vector__XXX
 SG_ ISOBUSCmplncCrtfctLaboratoryType : 9|3@1+ (1,0) [0|0] "" Vector__XXX
 SG_ ISOBUSCmplnceCertificateRevision : 6|3@1+ (1,0) [0|0] "" Vector__XXX
 SG_ ISOBUSCmplianceCertificationYear : 0|6@1+ (1,0) [0|0] "" Vector__XXX

BO_ 2365403902 TBD: 8 Vector__XXX

BO_ 2365391870 IOS: 8 Vector__XXX
 SG_ ImplementOperatingStateCmd : 56|2@1+ (1,0) [0|0] "" Vector__XXX

BO_ 2365391614 AISO: 8 Vector__XXX
 SG_ AllImplmntStpOprtngOprtnsSwtchSt : 56|2@1+ (1,0) [0|0] "" Vector__XXX

BO_ 2365379838 XCP_ID: 8 Vector__XXX

BO_ 2365378302 DSC: 8 Vector__XXX

BO_ 2365378046 DSS: 8 Vector__XXX

BO_ 2566701566 TRF3: 8 Vector__XXX
 SG_ TransOilTransCoolerOutletTemp : 8|8@1+ (1,-40) [-40|210] "°C" Vector__XXX
 SG_ TransClutch2Press : 0|8@1+ (16,0) [0|4000] "kPa" Vector__XXX

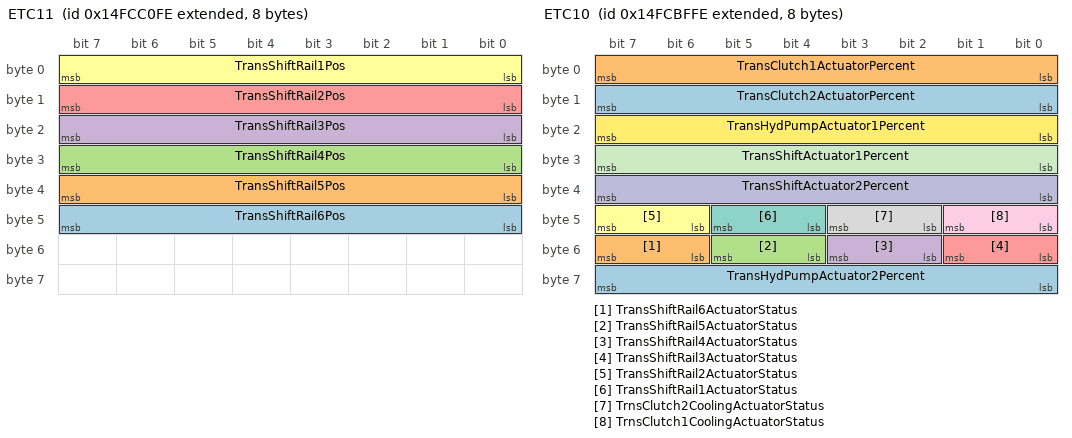
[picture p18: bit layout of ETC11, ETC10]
BO_ 2499592446 ETC11: 8 Vector__XXX
 SG_ TransShiftRail6Pos : 40|8@1+ (0.4,0) [0|100] "%" Vector__XXX
 SG_ TransShiftRail5Pos : 32|8@1+ (0.4,0) [0|100] "%" Vector__XXX
 SG_ TransShiftRail4Pos : 24|8@1+ (0.4,0) [0|100] "%" Vector__XXX
 SG_ TransShiftRail3Pos : 16|8@1+ (0.4,0) [0|100] "%" Vector__XXX
 SG_ TransShiftRail2Pos : 8|8@1+ (0.4,0) [0|100] "%" Vector__XXX
 SG_ TransShiftRail1Pos : 0|8@1+ (0.4,0) [0|100] "%" Vector__XXX

BO_ 2499592190 ETC10: 8 Vector__XXX
 SG_ TransHydPumpActuator2Percent : 56|8@1+ (0.4,0) [0|100] "%" Vector__XXX
 SG_ TransShiftRail6ActuatorStatus : 54|2@1+ (1,0) [0|3] "" Vector__XXX
 SG_ TransShiftRail5ActuatorStatus : 52|2@1+ (1,0) [0|3] "" Vector__XXX
 SG_ TransShiftRail4ActuatorStatus : 50|2@1+ (1,0) [0|3] "" Vector__XXX
 SG_ TransShiftRail3ActuatorStatus : 48|2@1+ (1,0) [0|3] "" Vector__XXX
 SG_ TransShiftRail2ActuatorStatus : 46|2@1+ (1,0) [0|3] "" Vector__XXX
 SG_ TransShiftRail1ActuatorStatus : 44|2@1+ (1,0) [0|3] "" Vector__XXX
 SG_ TrnsClutch2CoolingActuatorStatus : 42|2@1+ (1,0) [0|3] "" Vector__XXX
 SG_ TrnsClutch1CoolingActuatorStatus : 40|2@1+ (1,0) [0|3] "" Vector__XXX
 SG_ TransShiftActuator2Percent : 32|8@1+ (0.4,0) [0|100] "%" Vector__XXX
 SG_ TransShiftActuator1Percent : 24|8@1+ (0.4,0) [0|100] "%" Vector__XXX
 SG_ TransHydPumpActuator1Percent : 16|8@1+ (0.4,0) [0|100] "%" Vector__XXX
 SG_ TransClutch2ActuatorPercent : 8|8@1+ (0.4,0) [0|100] "%" Vector__XXX
 SG_ TransClutch1ActuatorPercent : 0|8@1+ (0.4,0) [0|100] "%" Vector__XXX

BO_ 2365374206 ETC9: 8 Vector__XXX
 SG_ DlCltchTrnsCrrntPreselectionGear : 40|8@1+ (1,-125) [-125|125] "" Vector__XXX
 SG_ DlCltchTrnsSlctdPreselectionGear : 32|8@1+ (1,-125) [-125|125] "" Vector__XXX
 SG_ DualClutchTransInputShaft2Speed : 16|16@1+ (0.125,0) [0|8031.875] "rpm" Vector__XXX
 SG_ DualClutchTransInputShaft1Speed : 0|16@1+ (0.125,0) [0|8031.875] "rpm" Vector__XXX

BO_ 2566700542 A1SCRSI2: 8 Vector__XXX
 SG_ AftrtrtmntTripDieselExhaustFluid : 32|32@1+ (0.05,0) [0|210554060.75] "L" Vector__XXX
 SG_ Aftrtrtmnt1TtlDslExhustFluidUsed : 0|32@1+ (0.5,0) [0|2105540607.5] "L" Vector__XXX

BO_ 2566700286 A2SCRSI2: 8 Vector__XXX
 SG_ Aftrtrtmnt2TtlDslExhustFluidUsed : 0|32@1+ (0.5,0) [0|2105540607.5] "L" Vector__XXX

BO_ 2566700030 A1ECMI: 8 Vector__XXX
 SG_ Aftrtrtmnt1DslExhstFldCtrlMd6309 : 4|2@1+ (1,0) [0|3] "" Vector__XXX
 SG_ Aftrtrtmnt1DslExhstFldCtrlMdlPwr : 2|2@1+ (1,0) [0|3] "" Vector__XXX
 SG_ Aftrtrtmnt1DslExhstFldCtrlMdlRly : 0|2@1+ (1,0) [0|3] "" Vector__XXX

BO_ 2566699774 A2ECMI: 8 Vector__XXX
 SG_ Aftrtrtmnt2DslExhstFldCtrlMd6310 : 4|2@1+ (1,0) [0|3] "" Vector__XXX
 SG_ Aftrtrtmnt2DslExhstFldCtrlMdlPwr : 2|2@1+ (1,0) [0|3] "" Vector__XXX
 SG_ Aftrtrtmnt2DslExhstFldCtrlMdlRly : 0|2@1+ (1,0) [0|3] "" Vector__XXX

BO_ 2566699518 AT1S2: 8 Vector__XXX
 SG_ Aftrtrtmnt1DslPrtcltFltrTmTNxtAc : 0|32@1+ (1,0) [0|4211081215] "s" Vector__XXX

BO_ 2566699262 AT2S2: 8 Vector__XXX
 SG_ Aftrtrtmnt2DslPrtcltFltrTmTNxtAc : 0|32@1+ (1,0) [0|4211081215] "s" Vector__XXX

BO_ 2566698750 VEP5: 8 Vector__XXX
 SG_ SLIBatteryPackHealth : 32|8@1+ (0.5,0) [0|100] "%" Vector__XXX
 SG_ SLIBatteryPackCapacity : 16|16@1+ (1,0) [0|64255] "Ah" Vector__XXX
 SG_ SLIBatteryPackStateOfCharge : 0|16@1+ (0.0025,0) [0|160.6375] "%" Vector__XXX

BO_ 2566698494 FPOS: 8 Vector__XXX
 SG_ FusedOutput29 : 62|2@1+ (1,0) [0|3] "" Vector__XXX
 SG_ FusedOutput30 : 60|2@1+ (1,0) [0|3] "" Vector__XXX
 SG_ FusedOutput31 : 58|2@1+ (1,0) [0|3] "" Vector__XXX
 SG_ FusedOutput32 : 56|2@1+ (1,0) [0|3] "" Vector__XXX
 SG_ FusedOutput25 : 54|2@1+ (1,0) [0|3] "" Vector__XXX
 SG_ FusedOutput26 : 52|2@1+ (1,0) [0|3] "" Vector__XXX
 SG_ FusedOutput27 : 50|2@1+ (1,0) [0|3] "" Vector__XXX
 SG_ FusedOutput28 : 48|2@1+ (1,0) [0|3] "" Vector__XXX
 SG_ FusedOutput21 : 46|2@1+ (1,0) [0|3] "" Vector__XXX
 SG_ FusedOutput22 : 44|2@1+ (1,0) [0|3] "" Vector__XXX
 SG_ FusedOutput23 : 42|2@1+ (1,0) [0|3] "" Vector__XXX
 SG_ FusedOutput24 : 40|2@1+ (1,0) [0|3] "" Vector__XXX
 SG_ FusedOutput17 : 38|2@1+ (1,0) [0|3] "" Vector__XXX
 SG_ FusedOutput18 : 36|2@1+ (1,0) [0|3] "" Vector__XXX
 SG_ FusedOutput19 : 34|2@1+ (1,0) [0|3] "" Vector__XXX
 SG_ FusedOutput20 : 32|2@1+ (1,0) [0|3] "" Vector__XXX
 SG_ FusedOutput13 : 30|2@1+ (1,0) [0|3] "" Vector__XXX
 SG_ FusedOutput14 : 27|2@1+ (1,0) [0|3] "" Vector__XXX
 SG_ FusedOutput15 : 26|2@1+ (1,0) [0|3] "" Vector__XXX
 SG_ FusedOutput16 : 24|2@1+ (1,0) [0|3] "" Vector__XXX
 SG_ FusedOutput9 : 22|2@1+ (1,0) [0|3] "" Vector__XXX
 SG_ FusedOutput10 : 20|2@1+ (1,0) [0|3] "" Vector__XXX
 SG_ FusedOutput11 : 18|2@1+ (1,0) [0|3] "" Vector__XXX
 SG_ FusedOutput12 : 16|2@1+ (1,0) [0|3] "" Vector__XXX
 SG_ FusedOutput5 : 14|2@1+ (1,0) [0|3] "" Vector__XXX
 SG_ FusedOutput6 : 12|2@1+ (1,0) [0|3] "" Vector__XXX
 SG_ FusedOutput7 : 10|2@1+ (1,0) [0|3] "" Vector__XXX
 SG_ FusedOutput8 : 8|2@1+ (1,0) [0|3] "" Vector__XXX
 SG_ FusedOutput1 : 6|2@1+ (1,0) [0|3] "" Vector__XXX
 SG_ FusedOutput2 : 4|2@1+ (1,0) [0|3] "" Vector__XXX
 SG_ FusedOutput3 : 2|2@1+ (1,0) [0|3] "" Vector__XXX
 SG_ FusedOutput4 : 0|2@1+ (1,0) [0|3] "" Vector__XXX

BO_ 2559115006 RBR: 8 Vector__XXX
 SG_ WirelessSignalStrength2 : 48|8@1+ (0.5,-125) [-125|0] "dBm" Vector__XXX
 SG_ TransmitterID2 : 24|24@1+ (1,0) [0|16449635] "" Vector__XXX
 SG_ RadioBeaconDirection : 22|2@1+ (1,0) [0|3] "" Vector__XXX
 SG_ UnqBeaconMessageIdentifierNumber : 0|16@1+ (1,0) [0|64255] "" Vector__XXX

BO_ 2566707454 AT1DPF2S3: 8 Vector__XXX
 SG_ Aftrtrtmnt1DslPrtcltFltr2StS5647 : 48|16@1+ (0.1,0) [0|6425.5] "MHz" Vector__XXX
 SG_ Aftrtrtmnt1DslPrtcltFltr2StS5646 : 32|16@1+ (0.1,0) [0|6425.5] "MHz" Vector__XXX
 SG_ Aftrtrtmnt1DslPrtcltFltr2StS5645 : 16|16@1+ (0.1,0) [0|6425.5] "MHz" Vector__XXX
 SG_ Aftrtrtmnt1DslPrtcltFltr2StSnsrA : 0|16@1+ (0.1,0) [0|6425.5] "MHz" Vector__XXX

BO_ 2566707198 AT1DPF2S4: 8 Vector__XXX
 SG_ Aftrtrtmnt1DslPrtcltFltr2StS5651 : 48|16@1+ (0.0025,0) [0|160.6375] "%" Vector__XXX
 SG_ Aftrtrtmnt1DslPrtcltFltr2StS5650 : 32|16@1+ (0.1,0) [0|6425.5] "MHz" Vector__XXX
 SG_ Aftrtrtmnt1DslPrtcltFltr2StSnsrF : 16|16@1+ (0.0025,0) [0|160.6375] "%" Vector__XXX
 SG_ Aftrtrtmnt1DslPrtcltFltr2StSnsrA : 0|16@1+ (0.1,0) [0|6425.5] "MHz" Vector__XXX

BO_ 2566706942 AT1DPF2S5: 8 Vector__XXX
 SG_ Aftrtrtmnt1DslPrtcltFltr2StS5655 : 48|16@1+ (0.0025,0) [0|160.6375] "%" Vector__XXX
 SG_ Aftrtrtmnt1DslPrtcltFltr2StS5654 : 32|16@1+ (0.1,0) [0|6425.5] "MHz" Vector__XXX
 SG_ Aftrtrtmnt1DslPrtcltFltr2StSnsrF : 16|16@1+ (0.0025,0) [0|160.6375] "%" Vector__XXX
 SG_ Aftrtrtmnt1DslPrtcltFltr2StSnsrA : 0|16@1+ (0.1,0) [0|6425.5] "MHz" Vector__XXX

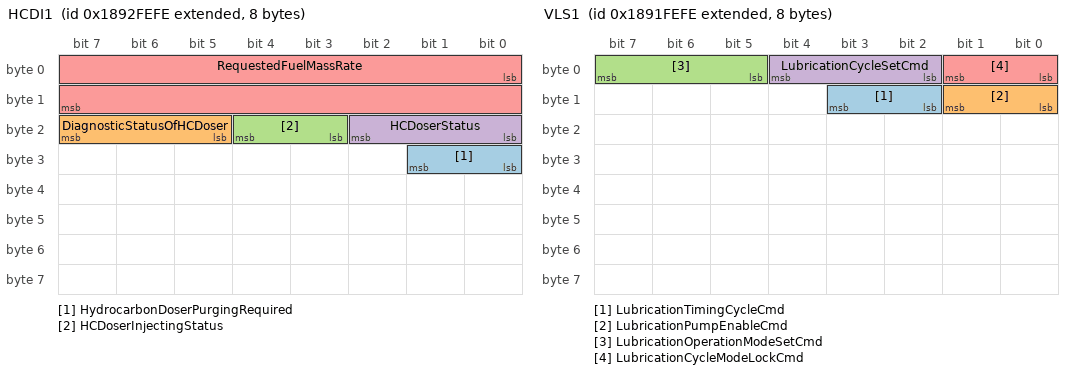
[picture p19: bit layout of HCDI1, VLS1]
BO_ 2559770366 HCDI1: 8 Vector__XXX
 SG_ HydrocarbonDoserPurgingRequired : 24|2@1+ (1,0) [0|3] "" Vector__XXX
 SG_ DiagnosticStatusOfHCDoser : 21|3@1+ (1,0) [0|7] "" Vector__XXX
 SG_ HCDoserInjectingStatus : 19|2@1+ (1,0) [0|3] "" Vector__XXX
 SG_ HCDoserStatus : 16|3@1+ (1,0) [0|7] "" Vector__XXX
 SG_ RequestedFuelMassRate : 0|16@1+ (0.05,0) [0|3212.75] "g/min" Vector__XXX

BO_ 2559704830 VLS1: 8 Vector__XXX
 SG_ LubricationTimingCycleCmd : 10|2@1+ (1,0) [0|3] "" Vector__XXX
 SG_ LubricationPumpEnableCmd : 8|2@1+ (1,0) [0|3] "" Vector__XXX
 SG_ LubricationOperationModeSetCmd : 5|3@1+ (1,0) [0|7] "" Vector__XXX
 SG_ LubricationCycleSetCmd : 2|3@1+ (1,0) [0|7] "" Vector__XXX
 SG_ LubricationCycleModeLockCmd : 0|2@1+ (1,0) [0|3] "" Vector__XXX

BO_ 2559639294 SFC: 8 Vector__XXX
 SG_ SupplementalFanPowerHold : 24|2@1+ (1,0) [0|3] "" Vector__XXX
 SG_ SupplementalFanSpeedCmd : 8|16@1+ (0.5,0) [0|32127.5] "rpm" Vector__XXX
 SG_ SupplementalFanDirectionCmd : 2|2@1+ (1,0) [0|3] "" Vector__XXX
 SG_ SupplementalFanEnableCmd : 0|2@1+ (1,0) [0|3] "" Vector__XXX

BO_ 2559573758 ECC: 8 Vector__XXX
 SG_ ClntLvlEngPrtctnShtdwnOvrrideCmd : 0|2@1+ (1,0) [0|3] "" Vector__XXX

BO_ 2349530878 CCVS2: 8 Vector__XXX
 SG_ CruiseCtrlPauseCmd : 4|2@1+ (1,0) [0|3] "" Vector__XXX
 SG_ CruiseCtrlResumeCmd : 2|2@1+ (1,0) [0|3] "" Vector__XXX
 SG_ CruiseCtrlDisableCmd : 0|2@1+ (1,0) [0|3] "" Vector__XXX

BO_ 2566698238 SPOS: 8 Vector__XXX
 SG_ SwitchedOutput29 : 62|2@1+ (1,0) [0|3] "" Vector__XXX
 SG_ SwitchedOutput30 : 60|2@1+ (1,0) [0|3] "" Vector__XXX
 SG_ SwitchedOutput31 : 58|2@1+ (1,0) [0|3] "" Vector__XXX
 SG_ SwitchedOutput32 : 56|2@1+ (1,0) [0|3] "" Vector__XXX
 SG_ SwitchedOutput25 : 54|2@1+ (1,0) [0|3] "" Vector__XXX
 SG_ SwitchedOutput26 : 52|2@1+ (1,0) [0|3] "" Vector__XXX
 SG_ SwitchedOutput27 : 50|2@1+ (1,0) [0|3] "" Vector__XXX
 SG_ SwitchedOutput28 : 48|2@1+ (1,0) [0|3] "" Vector__XXX
 SG_ SwitchedOutput21 : 46|2@1+ (1,0) [0|3] "" Vector__XXX
 SG_ SwitchedOutput22 : 44|2@1+ (1,0) [0|3] "" Vector__XXX
 SG_ SwitchedOutput23 : 42|2@1+ (1,0) [0|3] "" Vector__XXX
 SG_ SwitchedOutput24 : 40|2@1+ (1,0) [0|3] "" Vector__XXX
 SG_ SwitchedOutput17 : 38|2@1+ (1,0) [0|3] "" Vector__XXX
 SG_ SwitchedOutput18 : 36|2@1+ (1,0) [0|3] "" Vector__XXX
 SG_ SwitchedOutput19 : 34|2@1+ (1,0) [0|3] "" Vector__XXX
 SG_ SwitchedOutput20 : 32|2@1+ (1,0) [0|3] "" Vector__XXX
 SG_ SwitchedOutput13 : 30|2@1+ (1,0) [0|3] "" Vector__XXX
 SG_ SwitchedOutput14 : 27|2@1+ (1,0) [0|3] "" Vector__XXX
 SG_ SwitchedOutput15 : 26|2@1+ (1,0) [0|3] "" Vector__XXX
 SG_ SwitchedOutput16 : 24|2@1+ (1,0) [0|3] "" Vector__XXX
 SG_ SwitchedOutput9 : 22|2@1+ (1,0) [0|3] "" Vector__XXX
 SG_ SwitchedOutput10 : 20|2@1+ (1,0) [0|3] "" Vector__XXX
 SG_ SwitchedOutput11 : 18|2@1+ (1,0) [0|3] "" Vector__XXX
 SG_ SwitchedOutput12 : 16|2@1+ (1,0) [0|3] "" Vector__XXX
 SG_ SwitchedOutput5 : 14|2@1+ (1,0) [0|3] "" Vector__XXX
 SG_ SwitchedOutput6 : 12|2@1+ (1,0) [0|3] "" Vector__XXX
 SG_ SwitchedOutput7 : 10|2@1+ (1,0) [0|3] "" Vector__XXX
 SG_ SwitchedOutput8 : 8|2@1+ (1,0) [0|3] "" Vector__XXX
 SG_ SwitchedOutput1 : 6|2@1+ (1,0) [0|3] "" Vector__XXX
 SG_ SwitchedOutput2 : 4|2@1+ (1,0) [0|3] "" Vector__XXX
 SG_ SwitchedOutput3 : 2|2@1+ (1,0) [0|3] "" Vector__XXX
 SG_ SwitchedOutput4 : 0|2@1+ (1,0) [0|3] "" Vector__XXX

BO_ 2566697982 FPOC: 64 Vector__XXX
 SG_ FusedOutput32Current : 496|16@1+ (0.005,0) [0|321.275] "A" Vector__XXX
 SG_ FusedOutput31Current : 480|16@1+ (0.005,0) [0|321.275] "A" Vector__XXX
 SG_ FusedOutput30Current : 464|16@1+ (0.005,0) [0|321.275] "A" Vector__XXX
 SG_ FusedOutput29Current : 448|16@1+ (0.005,0) [0|321.275] "A" Vector__XXX
 SG_ FusedOutput28Current : 432|16@1+ (0.005,0) [0|321.275] "A" Vector__XXX
 SG_ FusedOutput27Current : 416|16@1+ (0.005,0) [0|321.275] "A" Vector__XXX
 SG_ FusedOutput26Current : 400|16@1+ (0.005,0) [0|321.275] "A" Vector__XXX
 SG_ FusedOutput25Current : 384|16@1+ (0.005,0) [0|321.275] "A" Vector__XXX
 SG_ FusedOutput24Current : 368|16@1+ (0.005,0) [0|321.275] "A" Vector__XXX
 SG_ FusedOutput23Current : 352|16@1+ (0.005,0) [0|321.275] "A" Vector__XXX
 SG_ FusedOutput22Current : 336|16@1+ (0.005,0) [0|321.275] "A" Vector__XXX
 SG_ FusedOutput21Current : 320|16@1+ (0.005,0) [0|321.275] "A" Vector__XXX
 SG_ FusedOutput20Current : 304|16@1+ (0.005,0) [0|321.275] "A" Vector__XXX
 SG_ FusedOutput19Current : 288|16@1+ (0.005,0) [0|321.275] "A" Vector__XXX
 SG_ FusedOutput18Current : 272|16@1+ (0.005,0) [0|321.275] "A" Vector__XXX
 SG_ FusedOutput17Current : 256|16@1+ (0.005,0) [0|321.275] "A" Vector__XXX
 SG_ FusedOutput16Current : 240|16@1+ (0.005,0) [0|321.275] "A" Vector__XXX
 SG_ FusedOutput15Current : 224|16@1+ (0.005,0) [0|321.275] "A" Vector__XXX
 SG_ FusedOutput14Current : 208|16@1+ (0.005,0) [0|321.275] "A" Vector__XXX
 SG_ FusedOutput13Current : 192|16@1+ (0.005,0) [0|321.275] "A" Vector__XXX
 SG_ FusedOutput12Current : 176|16@1+ (0.005,0) [0|321.275] "A" Vector__XXX
 SG_ FusedOutput11Current : 160|16@1+ (0.005,0) [0|321.275] "A" Vector__XXX
 SG_ FusedOutput10Current : 144|16@1+ (0.005,0) [0|321.275] "A" Vector__XXX
 SG_ FusedOutput9Current : 128|16@1+ (0.005,0) [0|321.275] "A" Vector__XXX
 SG_ FusedOutput8Current : 112|16@1+ (0.005,0) [0|321.275] "A" Vector__XXX
 SG_ FusedOutput7Current : 96|16@1+ (0.005,0) [0|321.275] "A" Vector__XXX
 SG_ FusedOutput6Current : 80|16@1+ (0.005,0) [0|321.275] "A" Vector__XXX
 SG_ FusedOutput5Current : 64|16@1+ (0.005,0) [0|321.275] "A" Vector__XXX
 SG_ FusedOutput4Current : 48|16@1+ (0.005,0) [0|321.275] "A" Vector__XXX
 SG_ FusedOutput3Current : 32|16@1+ (0.005,0) [0|321.275] "A" Vector__XXX
 SG_ FusedOutput2Current : 16|16@1+ (0.005,0) [0|321.275] "A" Vector__XXX
 SG_ FusedOutput1Current : 0|16@1+ (0.005,0) [0|321.275] "A" Vector__XXX

CM_ BU_ PowertrainControlModule "Electronic control module in charge of controlling and coordinating the operation of a hybrid propulsion system.";
CM_ BU_ HitchControl "Straight truck hitch (NOT Agricultural hitch – it is in IG 2) ";
CM_ SG_ 2147483936 ABSOffroadRequest "Request to activate the ABS off-road function. The switch signal is independent of an actual ABS control situation.";
CM_ BO_ 2381315838 "This proprietary PG uses the Destination Specific PDU Format allowing manufacturers to direct their proprietary communications to a specific destination node.";
CM_ BO_ 2365510142 "SAE J1939 will not specify an implementation for this DM.  Oxygen sensor test and results should be communicated using DM7 and DM8";
CM_ BO_ 2365475326 "This message is normally sent by the Tractor ECU on the implement bus on construction and agricultural implements and provides to connected systems, the current measured ground speed.";
CM_ SG_ 2365475326 GroundBasedDirection "A measured signal indicating either forward or reverse as the direction of travel.  When speed is zero, indicate the last travel direction until a different direction is detected.";
CM_ SG_ 2365475326 GroundBasedImplementDistance "Actual distance travelled by a machine based on measurements from a sensor such as RADAR";
CM_ SG_ 2365475326 GroundBasedImplementSpeed "Actual ground speed of a machine, measured by a sensor such as RADAR.";
CM_ BO_ 2365475070 "This message is sent by the Tractor ECU on the implement bus on construction and agricultural implements and provides to connected systems, the current measured wheel-based speed.";
CM_ SG_ 2365475070 KeySwitchNOTOFF "Indicates the Key Switch of the tractor or power unit is NOT in the Off position.";
CM_ SG_ 2365475070 WheelBasedDirection "A measured signal indicating either forward or reverse as the direction of travel.";
CM_ SG_ 2365475070 MaxTimeOfTractorPower "The maximum time of remaining tractor or power unit supplied electrical power at the current load.";
CM_ SG_ 2365475070 WheelBasedDistance "The distance travelled by a machine as calculated from wheel or tail shaft speed.";
CM_ SG_ 2365475070 WheelBasedSpeed "A value of the speed of a machine as calculated from the measured wheel or tail shaft speed.";
CM_ BO_ 2365474814 "This message is sent by any ECU connected to the implement bus requesting that the Tractor ECU not switch off the power for the next 2 seconds.";
CM_ SG_ 2365474814 ImplementTransportState "Indicates the transport state of an implement connected to a tractor or power unit.";
CM_ SG_ 2365474814 ImplementParkState "Indicates the state of an implement where it may be disconnected from a tractor or power unit.";
CM_ SG_ 2365474814 ImplementWorkState "Indicates that an implement is connected to a tractor or power unit and is ready for work";
CM_ SG_ 2365474814 MaintainECUPower "Request to the Tractor ECU to maintain ECU_PWR power for the next 2 seconds.";
CM_ SG_ 2365474814 MaintainAcuatorPower "Request to the Tractor ECU to maintain PWR power for the next 2 seconds.";
CM_ BO_ 2365474558 "This message provides the measurement of the current front hitch parameters.";
CM_ SG_ 2365474558 FrontDraft "The apparent horizontal force applied to the front hitch by an implement.";
CM_ SG_ 2365474558 FrontNominalLowerLinkForce "This measurement provides an indication of draft at the lower links of the front three point hitch.";
CM_ SG_ 2365474558 FrontHitchInworkIndication "A measured signal indicating that the front hitch is positioned below (in-work) or above (out-of-work) an adjustable switching threshold.";
CM_ SG_ 2365474558 FrontHitchPos "The measured position of the front three-point-hitch.";
CM_ BO_ 2365474302 "This message provides the measurement of the current rear hitch parameters.";
CM_ SG_ 2365474302 RearHitchExit_reasonCode "This parameter indicates why the Rear Hitch cannot accept remote commands or has most recently stopped accepting remote commands.";
CM_ SG_ 2365474302 RearDraft "The apparent horizontal force applied to the rear hitch by an implement.";
CM_ SG_ 2365474302 RearNominalLowerLinkForce "This measurement provides an indication of draft at the lower links of the front three point hitch.";
CM_ SG_ 2365474302 RearHitchInworkIndication "A measured signal indicating that the rear hitch is positioned below (in-work) or above (out-of-work) an adjustable switching threshold.";
CM_ SG_ 2365474302 RearHitchPos "The measured position of the rear three-point-hitch.";
CM_ BO_ 2365474046 "This message provides the measurement of the current secondary or front PTO output shaft parameters.";
CM_ SG_ 2365474046 FrontPTOExit_reasonCode "This parameter indicates why the Front PTO cannot accept remote commands or has most recently stopped accepting remote commands.";
CM_ SG_ 2365474046 FrontHitchExit_reasonCode "This parameter indicates why the Front Hitch cannot accept remote commands or has most recently stopped accepting remote commands.";
CM_ SG_ 2365474046 FrontPowerTakeOffEngagement "A measured signal indicating that the front power take off is engaged or disengage.";
CM_ SG_ 2365474046 FrontPowerTakeOffMode "A measured signal indicating that the front power take off mode is either 540 or 1000 rpm.";
CM_ SG_ 2365474046 FrontPowerTakeOffEconomyMode "A measured signal indicating that the front power take off economy mode is engaged or disengaged.";
CM_ SG_ 2365474046 FrontPTOOutputShaftSpeedSetPoint "The measured value of the set point of the rotational speed of the front power take off (PTO) output shaft.";
CM_ SG_ 2365474046 FrontPTOOutputShaftSpeed "The measured rotational speed of the front power take off (PTO) output shaft.";
CM_ BO_ 2365473790 "This message provides the measurement of the current primary or rear PTO output shaft parameters.";
CM_ SG_ 2365473790 RearPTOExit_reasonCode "This parameter indicates why the Rear PTO cannot accept remote commands or has most recently stopped accepting remote commands.";
CM_ SG_ 2365473790 RearPowerTakeOffEngagement "A measured signal indicating that the rear power take off is engaged or disengage.";
CM_ SG_ 2365473790 RearPowerTakeOffMode "A measured signal indicating that the rear power take off mode is either 540 or 1000 rpm.";
CM_ SG_ 2365473790 RearPowerTakeOffEconomyMode "A measured signal indicating that the rear power take off economy mode is engaged or disengaged.";
CM_ SG_ 2365473790 RearPTOOutputShaftSpeedSetPoint "The measured value of the set point of the rotational speed of the rear power take off (PTO) output shaft.";
CM_ SG_ 2365473790 RearPTOOutputShaftSpeed "The measured rotational speed of the rear power take off (PTO) output shaft.";
CM_ BO_ 2365473534 "This message provides control of the hitch position, PTO shaft set point speed and PTO engagement.";
CM_ SG_ 2365473534 FrontPowerTakeOffModeCmd "The command to select the mode of the front power take off .";
CM_ SG_ 2365473534 RearPowerTakeOffModeCmd "The command to select the mode of the rear power take off .";
CM_ SG_ 2365473534 FrontPowerTakeOffEconomyModeCmd "The command to engage or disengage the front power take off‘s economy mode.";
CM_ SG_ 2365473534 RearPowerTakeOffEconomyModeCmd "The command to engage or disengage the rear power take off‘s economy mode.";
CM_ SG_ 2365473534 FrontPowerTakeOffEngagementCmd "The command to engage or disengage the front power take off .";
CM_ SG_ 2365473534 RearPowerTakeOffEngagementCmd "The command to engage or disengage the rear power take off .";
CM_ SG_ 2365473534 RrPTOOutputShaftSpeedSetPointCmd "The command to set the rotational speed of the rear power take off (PTO) output shaft.";
CM_ SG_ 2365473534 FrntPTOOtptShaftSpeedSetPointCmd "The command to set the rotational speed of the front power take off (PTO) output shaft.";
CM_ SG_ 2365473534 RearHitchPosCmd "Command to allow the position of the rear three-point-hitch to be set.";
CM_ SG_ 2365473534 FrontHitchPosCmd "Command to allow the position of the front three-point-hitch to be set.";
CM_ BO_ 2365472766 "This message provides control of the flow through the auxiliary valves.";
CM_ SG_ 2365472766 AuxValve15FailSafeModeCmd "Command for setting the fail safe mode of an auxiliary valve.";
CM_ SG_ 2365472766 AuxValve15StateCmd "Command for setting the auxiliary valve state.";
CM_ SG_ 2365472766 AuxValve15PortFlowCmd "The command to set the flow through the  extend or retract port of an auxiliary valve of a tractor, expressed as a percentage of full flow.";
CM_ BO_ 2365472510 "This message provides control of the flow through the auxiliary valves.";
CM_ SG_ 2365472510 AuxValve14FailSafeModeCmd "Command for setting the fail safe mode of an auxiliary valve.";
CM_ SG_ 2365472510 AuxValve14StateCmd "Command for setting the auxiliary valve state.";
CM_ SG_ 2365472510 AuxValve14PortFlowCmd "The command to set the flow through the  extend or retract port of an auxiliary valve of a tractor, expressed as a percentage of full flow.";
CM_ BO_ 2365472254 "This message provides control of the flow through the auxiliary valves.";
CM_ SG_ 2365472254 AuxValve13FailSafeModeCmd "Command for setting the fail safe mode of an auxiliary valve.";
CM_ SG_ 2365472254 AuxValve13StateCmd "Command for setting the auxiliary valve state.";
CM_ SG_ 2365472254 AuxValve13PortFlowCmd "The command to set the flow through the  extend or retract port of an auxiliary valve of a tractor, expressed as a percentage of full flow.";
CM_ BO_ 2365471998 "This message provides control of the flow through the auxiliary valves.";
CM_ SG_ 2365471998 AuxValve12FailSafeModeCmd "Command for setting the fail safe mode of an auxiliary valve.";
CM_ SG_ 2365471998 AuxValve12StateCmd "Command for setting the auxiliary valve state.";
CM_ SG_ 2365471998 AuxValve12PortFlowCmd "The command to set the flow through the  extend or retract port of an auxiliary valve of a tractor, expressed as a percentage of full flow.";
CM_ BO_ 2365471742 "This message provides control of the flow through the auxiliary valves.";
CM_ SG_ 2365471742 AuxValve11FailSafeModeCmd "Command for setting the fail safe mode of an auxiliary valve.";
CM_ SG_ 2365471742 AuxValve11StateCmd "Command for setting the auxiliary valve state.";
CM_ SG_ 2365471742 AuxValve11PortFlowCmd "The command to set the flow through the  extend or retract port of an auxiliary valve of a tractor, expressed as a percentage of full flow.";
CM_ BO_ 2365471486 "This message provides control of the flow through the auxiliary valves.";
CM_ SG_ 2365471486 AuxValve10FailSafeModeCmd "Command for setting the fail safe mode of an auxiliary valve.";
CM_ SG_ 2365471486 AuxValve10StateCmd "Command for setting the auxiliary valve state.";
CM_ SG_ 2365471486 AuxValve10PortFlowCmd "The command to set the flow through the  extend or retract port of an auxiliary valve of a tractor, expressed as a percentage of full flow.";
CM_ BO_ 2365471230 "This message provides control of the flow through the auxiliary valves.";
CM_ SG_ 2365471230 AuxValve9FailSafeModeCmd "Command for setting the fail safe mode of an auxiliary valve.";
CM_ SG_ 2365471230 AuxValve9StateCmd "Command for setting the auxiliary valve state.";
CM_ SG_ 2365471230 AuxValve9PortFlowCmd "The command to set the flow through the  extend or retract port of an auxiliary valve of a tractor, expressed as a percentage of full flow.";
CM_ BO_ 2365470974 "This message provides control of the flow through the auxiliary valves.";
CM_ SG_ 2365470974 AuxValve8FailSafeModeCmd "Command for setting the fail safe mode of an auxiliary valve.";
CM_ SG_ 2365470974 AuxValve8StateCmd "Command for setting the auxiliary valve state.";
CM_ SG_ 2365470974 AuxValve8PortFlowCmd "The command to set the flow through the  extend or retract port of an auxiliary valve of a tractor, expressed as a percentage of full flow.";
CM_ BO_ 2365470718 "This message provides control of the flow through the auxiliary valves.";
CM_ SG_ 2365470718 AuxValve7FailSafeModeCmd "Command for setting the fail safe mode of an auxiliary valve.";
CM_ SG_ 2365470718 AuxValve7StateCmd "Command for setting the auxiliary valve state.";
CM_ SG_ 2365470718 AuxValve7PortFlowCmd "The command to set the flow through the  extend or retract port of an auxiliary valve of a tractor, expressed as a percentage of full flow.";
CM_ BO_ 2365470462 "This message provides control of the flow through the auxiliary valves.";
CM_ SG_ 2365470462 AuxValve6FailSafeModeCmd "Command for setting the fail safe mode of an auxiliary valve.";
CM_ SG_ 2365470462 AuxValve6StateCmd "Command for setting the auxiliary valve state.";
CM_ SG_ 2365470462 AuxValve6PortFlowCmd "The command to set the flow through the  extend or retract port of an auxiliary valve of a tractor, expressed as a percentage of full flow.";
CM_ BO_ 2365470206 "This message provides control of the flow through the auxiliary valves.";
CM_ SG_ 2365470206 AuxValve5FailSafeModeCmd "Command for setting the fail safe mode of an auxiliary valve.";
CM_ SG_ 2365470206 AuxValve5StateCmd "Command for setting the auxiliary valve state.";
CM_ SG_ 2365470206 AuxValve5PortFlowCmd "The command to set the flow through the  extend or retract port of an auxiliary valve of a tractor, expressed as a percentage of full flow.";
CM_ BO_ 2365469950 "This message provides control of the flow through the auxiliary valves.";
CM_ SG_ 2365469950 AuxValve4FailSafeModeCmd "Command for setting the fail safe mode of an auxiliary valve.";
CM_ SG_ 2365469950 AuxValve4StateCmd "Command for setting the auxiliary valve state.";
CM_ SG_ 2365469950 AuxValve4PortFlowCmd "The command to set the flow through the  extend or retract port of an auxiliary valve of a tractor, expressed as a percentage of full flow.";
CM_ BO_ 2365469694 "This message provides control of the flow through the auxiliary valves.";
CM_ SG_ 2365469694 AuxValve3FailSafeModeCmd "Command for setting the fail safe mode of an auxiliary valve.";
CM_ SG_ 2365469694 AuxValve3StateCmd "Command for setting the auxiliary valve state.";
CM_ SG_ 2365469694 AuxValve3PortFlowCmd "The command to set the flow through the  extend or retract port of an auxiliary valve of a tractor, expressed as a percentage of full flow.";
CM_ BO_ 2365469438 "This message provides control of the flow through the auxiliary valves.";
CM_ SG_ 2365469438 AuxValve2FailSafeModeCmd "Command for setting the fail safe mode of an auxiliary valve.";
CM_ SG_ 2365469438 AuxValve2StateCmd "Command for setting the auxiliary valve state.";
CM_ SG_ 2365469438 AuxValve2PortFlowCmd "The command to set the flow through the  extend or retract port of an auxiliary valve of a tractor, expressed as a percentage of full flow.";
CM_ BO_ 2365469182 "This message provides control of the flow through the auxiliary valves.";
CM_ SG_ 2365469182 AuxValve1FailSafeModeCmd "Command for setting the fail safe mode of an auxiliary valve.";
CM_ SG_ 2365469182 AuxValve1StateCmd "Command for setting the auxiliary valve state.";
CM_ SG_ 2365469182 AuxValve1PortFlowCmd "The command to set the flow through the  extend or retract port of an auxiliary valve of a tractor, expressed as a percentage of full flow.";
CM_ BO_ 2365468926 "This message provides control of the flow through the auxiliary valves.";
CM_ SG_ 2365468926 AuxValve0FailSafeModeCmd "Command for setting the fail safe mode of an auxiliary valve.";
CM_ SG_ 2365468926 AuxValve0StateCmd "Command for setting the auxiliary valve state.";
CM_ SG_ 2365468926 AuxValve0PortFlowCmd "The command to set the flow through the  extend or retract port of an auxiliary valve of a tractor, expressed as a percentage of full flow.";
CM_ BO_ 2365468670 "This message provides the measurement of specified auxiliary valve.";
CM_ SG_ 2365468670 AuxValve15ReturnPortPress "The measured nominal pressure at the return port of an auxiliary valve of a tractor.";
CM_ SG_ 2365468670 AuxValve15RetractPortPress "The measured nominal pressure at the retract port of an auxiliary valve of a tractor.";
CM_ SG_ 2365468670 AuxValve15ExtendPortPress "The measured nominal pressure at the extend port of an auxiliary valve of a tractor.";
CM_ SG_ 2365468670 AxValve15RetractPortMeasuredFlow "The measured flow through the retract port of an auxiliary valve of a tractor, expressed as a percentage of full flow.";
CM_ SG_ 2365468670 AuxValve15ExtendPortMeasuredFlow "The measured flow through the extend port of an auxiliary valve of a tractor, expressed as a percentage of full flow.";
CM_ BO_ 2365468414 "This message provides the measurement of specified auxiliary valve.";
CM_ SG_ 2365468414 AuxValve14ReturnPortPress "The measured nominal pressure at the return port of an auxiliary valve of a tractor.";
CM_ SG_ 2365468414 AuxValve14RetractPortPress "The measured nominal pressure at the retract port of an auxiliary valve of a tractor.";
CM_ SG_ 2365468414 AuxValve14ExtendPortPress "The measured nominal pressure at the extend port of an auxiliary valve of a tractor.";
CM_ SG_ 2365468414 AxValve14RetractPortMeasuredFlow "The measured flow through the retract port of an auxiliary valve of a tractor, expressed as a percentage of full flow.";
CM_ SG_ 2365468414 AuxValve14ExtendPortMeasuredFlow "The measured flow through the extend port of an auxiliary valve of a tractor, expressed as a percentage of full flow.";
CM_ BO_ 2365468158 "This message provides the measurement of specified auxiliary valve.";
CM_ SG_ 2365468158 AuxValve13ReturnPortPress "The measured nominal pressure at the return port of an auxiliary valve of a tractor.";
CM_ SG_ 2365468158 AuxValve13RetractPortPress "The measured nominal pressure at the retract port of an auxiliary valve of a tractor.";
CM_ SG_ 2365468158 AuxValve13ExtendPortPress "The measured nominal pressure at the extend port of an auxiliary valve of a tractor.";
CM_ SG_ 2365468158 AxValve13RetractPortMeasuredFlow "The measured flow through the retract port of an auxiliary valve of a tractor, expressed as a percentage of full flow.";
CM_ SG_ 2365468158 AuxValve13ExtendPortMeasuredFlow "The measured flow through the extend port of an auxiliary valve of a tractor, expressed as a percentage of full flow.";
CM_ BO_ 2365467902 "This message provides the measurement of specified auxiliary valve.";
CM_ SG_ 2365467902 AuxValve12ReturnPortPress "The measured nominal pressure at the return port of an auxiliary valve of a tractor.";
CM_ SG_ 2365467902 AuxValve12RetractPortPress "The measured nominal pressure at the retract port of an auxiliary valve of a tractor.";
CM_ SG_ 2365467902 AuxValve12ExtendPortPress "The measured nominal pressure at the extend port of an auxiliary valve of a tractor.";
CM_ SG_ 2365467902 AxValve12RetractPortMeasuredFlow "The measured flow through the retract port of an auxiliary valve of a tractor, expressed as a percentage of full flow.";
CM_ SG_ 2365467902 AuxValve12ExtendPortMeasuredFlow "The measured flow through the extend port of an auxiliary valve of a tractor, expressed as a percentage of full flow.";
CM_ BO_ 2365467646 "This message provides the measurement of specified auxiliary valve.";
CM_ SG_ 2365467646 AuxValve11ReturnPortPress "The measured nominal pressure at the return port of an auxiliary valve of a tractor.";
CM_ SG_ 2365467646 AuxValve11RetractPortPress "The measured nominal pressure at the retract port of an auxiliary valve of a tractor.";
CM_ SG_ 2365467646 AuxValve11ExtendPortPress "The measured nominal pressure at the extend port of an auxiliary valve of a tractor.";
CM_ SG_ 2365467646 AxValve11RetractPortMeasuredFlow "The measured flow through the retract port of an auxiliary valve of a tractor, expressed as a percentage of full flow.";
CM_ SG_ 2365467646 AuxValve11ExtendPortMeasuredFlow "The measured flow through the extend port of an auxiliary valve of a tractor, expressed as a percentage of full flow.";
CM_ BO_ 2365467390 "This message provides the measurement of specified auxiliary valve.";
CM_ SG_ 2365467390 AuxValve10ReturnPortPress "The measured nominal pressure at the return port of an auxiliary valve of a tractor.";
CM_ SG_ 2365467390 AuxValve10RetractPortPress "The measured nominal pressure at the retract port of an auxiliary valve of a tractor.";
CM_ SG_ 2365467390 AuxValve10ExtendPortPress "The measured nominal pressure at the extend port of an auxiliary valve of a tractor.";
CM_ SG_ 2365467390 AxValve10RetractPortMeasuredFlow "The measured flow through the retract port of an auxiliary valve of a tractor, expressed as a percentage of full flow.";
CM_ SG_ 2365467390 AuxValve10ExtendPortMeasuredFlow "The measured flow through the extend port of an auxiliary valve of a tractor, expressed as a percentage of full flow.";
CM_ BO_ 2365467134 "This message provides the measurement of specified auxiliary valve.";
CM_ SG_ 2365467134 AuxValve9ReturnPortPress "The measured nominal pressure at the return port of an auxiliary valve of a tractor.";
CM_ SG_ 2365467134 AuxValve9RetractPortPress "The measured nominal pressure at the retract port of an auxiliary valve of a tractor.";
CM_ SG_ 2365467134 AuxValve9ExtendPortPress "The measured nominal pressure at the extend port of an auxiliary valve of a tractor.";
CM_ SG_ 2365467134 AuxValve9RetractPortMeasuredFlow "The measured flow through the retract port of an auxiliary valve of a tractor, expressed as a percentage of full flow.";
CM_ SG_ 2365467134 AuxValve9ExtendPortMeasuredFlow "The measured flow through the extend port of an auxiliary valve of a tractor, expressed as a percentage of full flow.";
CM_ BO_ 2365466878 "This message provides the measurement of specified auxiliary valve.";
CM_ SG_ 2365466878 AuxValve8ReturnPortPress "The measured nominal pressure at the return port of an auxiliary valve of a tractor.";
CM_ SG_ 2365466878 AuxValve8RetractPortPress "The measured nominal pressure at the retract port of an auxiliary valve of a tractor.";
CM_ SG_ 2365466878 AuxValve8ExtendPortPress "The measured nominal pressure at the extend port of an auxiliary valve of a tractor.";
CM_ SG_ 2365466878 AuxValve8RetractPortMeasuredFlow "The measured flow through the retract port of an auxiliary valve of a tractor, expressed as a percentage of full flow.";
CM_ SG_ 2365466878 AuxValve8ExtendPortMeasuredFlow "The measured flow through the extend port of an auxiliary valve of a tractor, expressed as a percentage of full flow.";
CM_ BO_ 2365466622 "This message provides the measurement of specified auxiliary valve.";
CM_ SG_ 2365466622 AuxValve7ReturnPortPress "The measured nominal pressure at the return port of an auxiliary valve of a tractor.";
CM_ SG_ 2365466622 AuxValve7RetractPortPress "The measured nominal pressure at the retract port of an auxiliary valve of a tractor.";
CM_ SG_ 2365466622 AuxValve7ExtendPortPress "The measured nominal pressure at the extend port of an auxiliary valve of a tractor.";
CM_ SG_ 2365466622 AuxValve7RetractPortMeasuredFlow "The measured flow through the retract port of an auxiliary valve of a tractor, expressed as a percentage of full flow.";
CM_ SG_ 2365466622 AuxValve7ExtendPortMeasuredFlow "The measured flow through the extend port of an auxiliary valve of a tractor, expressed as a percentage of full flow.";
CM_ BO_ 2365466366 "This message provides the measurement of specified auxiliary valve.";
CM_ SG_ 2365466366 AuxValve6ReturnPortPress "The measured nominal pressure at the return port of an auxiliary valve of a tractor.";
CM_ SG_ 2365466366 AuxValve6RetractPortPress "The measured nominal pressure at the retract port of an auxiliary valve of a tractor.";
CM_ SG_ 2365466366 AuxValve6ExtendPortPress "The measured nominal pressure at the extend port of an auxiliary valve of a tractor.";
CM_ SG_ 2365466366 AuxValve6RetractPortMeasuredFlow "The measured flow through the retract port of an auxiliary valve of a tractor, expressed as a percentage of full flow.";
CM_ SG_ 2365466366 AuxValve6ExtendPortMeasuredFlow "The measured flow through the extend port of an auxiliary valve of a tractor, expressed as a percentage of full flow.";
CM_ BO_ 2365466110 "This message provides the measurement of specified auxiliary valve.";
CM_ SG_ 2365466110 AuxValve5ReturnPortPress "The measured nominal pressure at the return port of an auxiliary valve of a tractor.";
CM_ SG_ 2365466110 AuxValve5RetractPortPress "The measured nominal pressure at the retract port of an auxiliary valve of a tractor.";
CM_ SG_ 2365466110 AuxValve5ExtendPortPress "The measured nominal pressure at the extend port of an auxiliary valve of a tractor.";
CM_ SG_ 2365466110 AuxValve5RetractPortMeasuredFlow "The measured flow through the retract port of an auxiliary valve of a tractor, expressed as a percentage of full flow.";
CM_ SG_ 2365466110 AuxValve5ExtendPortMeasuredFlow "The measured flow through the extend port of an auxiliary valve of a tractor, expressed as a percentage of full flow.";
CM_ BO_ 2365465854 "This message provides the measurement of specified auxiliary valve.";
CM_ SG_ 2365465854 AuxValve4ReturnPortPress "The measured nominal pressure at the return port of an auxiliary valve of a tractor.";
CM_ SG_ 2365465854 AuxValve4RetractPortPress "The measured nominal pressure at the retract port of an auxiliary valve of a tractor.";
CM_ SG_ 2365465854 AuxValve4ExtendPortPress "The measured nominal pressure at the extend port of an auxiliary valve of a tractor.";
CM_ SG_ 2365465854 AuxValve4RetractPortMeasuredFlow "The measured flow through the retract port of an auxiliary valve of a tractor, expressed as a percentage of full flow.";
CM_ SG_ 2365465854 AuxValve4ExtendPortMeasuredFlow "The measured flow through the extend port of an auxiliary valve of a tractor, expressed as a percentage of full flow.";
CM_ BO_ 2365465598 "This message provides the measurement of specified auxiliary valve.";
CM_ SG_ 2365465598 AuxValve3ReturnPortPress "The measured nominal pressure at the return port of an auxiliary valve of a tractor.";
CM_ SG_ 2365465598 AuxValve3RetractPortPress "The measured nominal pressure at the retract port of an auxiliary valve of a tractor.";
CM_ SG_ 2365465598 AuxValve3ExtendPortPress "The measured nominal pressure at the extend port of an auxiliary valve of a tractor.";
CM_ SG_ 2365465598 AuxValve3RetractPortMeasuredFlow "The measured flow through the retract port of an auxiliary valve of a tractor, expressed as a percentage of full flow.";
CM_ SG_ 2365465598 AuxValve3ExtendPortMeasuredFlow "The measured flow through the extend port of an auxiliary valve of a tractor, expressed as a percentage of full flow.";
CM_ BO_ 2365465342 "This message provides the measurement of specified auxiliary valve.";
CM_ SG_ 2365465342 AuxValve2ReturnPortPress "The measured nominal pressure at the return port of an auxiliary valve of a tractor.";
CM_ SG_ 2365465342 AuxValve2RetractPortPress "The measured nominal pressure at the retract port of an auxiliary valve of a tractor.";
CM_ SG_ 2365465342 AuxValve2ExtendPortPress "The measured nominal pressure at the extend port of an auxiliary valve of a tractor.";
CM_ SG_ 2365465342 AuxValve2RetractPortMeasuredFlow "The measured flow through the retract port of an auxiliary valve of a tractor, expressed as a percentage of full flow.";
CM_ SG_ 2365465342 AuxValve2ExtendPortMeasuredFlow "The measured flow through the extend port of an auxiliary valve of a tractor, expressed as a percentage of full flow.";
CM_ BO_ 2365465086 "This message provides the measurement of specified auxiliary valve.";
CM_ SG_ 2365465086 AuxValve1ReturnPortPress "The measured nominal pressure at the return port of an auxiliary valve of a tractor.";
CM_ SG_ 2365465086 AuxValve1RetractPortPress "The measured nominal pressure at the retract port of an auxiliary valve of a tractor.";
CM_ SG_ 2365465086 AuxValve1ExtendPortPress "The measured nominal pressure at the extend port of an auxiliary valve of a tractor.";
CM_ SG_ 2365465086 AuxValve1RetractPortMeasuredFlow "The measured flow through the retract port of an auxiliary valve of a tractor, expressed as a percentage of full flow.";
CM_ SG_ 2365465086 AuxValve1ExtendPortMeasuredFlow "The measured flow through the extend port of an auxiliary valve of a tractor, expressed as a percentage of full flow.";
CM_ BO_ 2365464830 "This message provides the measurement of specified auxiliary valve.";
CM_ SG_ 2365464830 AuxValve0ReturnPortPress "The measured nominal pressure at the return port of an auxiliary valve of a tractor.";
CM_ SG_ 2365464830 AuxValve0RetractPortPress "The measured nominal pressure at the retract port of an auxiliary valve of a tractor.";
CM_ SG_ 2365464830 AuxValve0ExtendPortPress "The measured nominal pressure at the extend port of an auxiliary valve of a tractor.";
CM_ SG_ 2365464830 AuxValve0RetractPortMeasuredFlow "The measured flow through the retract port of an auxiliary valve of a tractor, expressed as a percentage of full flow.";
CM_ SG_ 2365464830 AuxValve0ExtendPortMeasuredFlow "The measured flow through the extend port of an auxiliary valve of a tractor, expressed as a percentage of full flow.";
CM_ BO_ 2365464574 "This message provides the estimated flow of specified auxiliary valve.";
CM_ SG_ 2365464574 AuxValve15Exit_reasonCode "This parameter indicates why the Auxiliary Valve 15 cannot accept remote commands or has most recently stopped accepting remote commands.";
CM_ SG_ 2365464574 AuxValve15FailSafeMode "The measured state the fail safe mode of an auxiliary valve.";
CM_ SG_ 2365464574 AuxValve15State "The measured state of the auxiliary valve.   With float enabled, hydraulic fluid may flow to or from the tractor as driven by the implement.";
CM_ SG_ 2365464574 AuxValve15RetractPortEstFlow "The value reported by the controller of flow through the retract port of an auxiliary valve of a tractor which could be based on the commanded position of the valve.";
CM_ SG_ 2365464574 AuxValve15ExtendPortEstFlow "The value reported by the controller of flow through the extend port of an auxiliary valve of a tractor which could be based on the commanded position of the valve.";
CM_ BO_ 2365464318 "This message provides the estimated flow of specified auxiliary valve.";
CM_ SG_ 2365464318 AuxValve14Exit_reasonCode "This parameter indicates why the Auxiliary Valve 14 cannot accept remote commands or has most recently stopped accepting remote commands.";
CM_ SG_ 2365464318 AuxValve14FailSafeMode "The measured state the fail safe mode of an auxiliary valve.";
CM_ SG_ 2365464318 AuxValve14State "The measured state of the auxiliary valve.   With float enabled, hydraulic fluid may flow to or from the tractor as driven by the implement.";
CM_ SG_ 2365464318 AuxValve14RetractPortEstFlow "The value reported by the controller of flow through the retract port of an auxiliary valve of a tractor which could be based on the commanded position of the valve.";
CM_ SG_ 2365464318 AuxValve14ExtendPortEstFlow "The value reported by the controller of flow through the extend port of an auxiliary valve of a tractor which could be based on the commanded position of the valve.";
CM_ BO_ 2365464062 "This message provides the estimated flow of specified auxiliary valve.";
CM_ SG_ 2365464062 AuxValve13Exit_reasonCode "This parameter indicates why the Auxiliary Valve 13 cannot accept remote commands or has most recently stopped accepting remote commands.";
CM_ SG_ 2365464062 AuxValve13FailSafeMode "The measured state the fail safe mode of an auxiliary valve.";
CM_ SG_ 2365464062 AuxValve13State "The measured state of the auxiliary valve.   With float enabled, hydraulic fluid may flow to or from the tractor as driven by the implement.";
CM_ SG_ 2365464062 AuxValve13RetractPortEstFlow "The value reported by the controller of flow through the retract port of an auxiliary valve of a tractor which could be based on the commanded position of the valve.";
CM_ SG_ 2365464062 AuxValve13ExtendPortEstFlow "The value reported by the controller of flow through the extend port of an auxiliary valve of a tractor which could be based on the commanded position of the valve.";
CM_ BO_ 2365463806 "This message provides the estimated flow of specified auxiliary valve.";
CM_ SG_ 2365463806 AuxValve12Exit_reasonCode "This parameter indicates why the Auxiliary Valve 12 cannot accept remote commands or has most recently stopped accepting remote commands.";
CM_ SG_ 2365463806 AuxValve12FailSafeMode "The measured state the fail safe mode of an auxiliary valve.";
CM_ SG_ 2365463806 AuxValve12State "The measured state of the auxiliary valve.   With float enabled, hydraulic fluid may flow to or from the tractor as driven by the implement.";
CM_ SG_ 2365463806 AuxValve12RetractPortEstFlow "The value reported by the controller of flow through the retract port of an auxiliary valve of a tractor which could be based on the commanded position of the valve.";
CM_ SG_ 2365463806 AuxValve12ExtendPortEstFlow "The value reported by the controller of flow through the extend port of an auxiliary valve of a tractor which could be based on the commanded position of the valve.";
CM_ BO_ 2365463550 "This message provides the estimated flow of specified auxiliary valve.";
CM_ SG_ 2365463550 AuxValve11Exit_reasonCode "This parameter indicates why the Auxiliary Valve 11 cannot accept remote commands or has most recently stopped accepting remote commands.";
CM_ SG_ 2365463550 AuxValve11FailSafeMode "The measured state the fail safe mode of an auxiliary valve.";
CM_ SG_ 2365463550 AuxValve11State "The measured state of the auxiliary valve.   With float enabled, hydraulic fluid may flow to or from the tractor as driven by the implement.";
CM_ SG_ 2365463550 AuxValve11RetractPortEstFlow "The value reported by the controller of flow through the retract port of an auxiliary valve of a tractor which could be based on the commanded position of the valve.";
CM_ SG_ 2365463550 AuxValve11ExtendPortEstFlow "The value reported by the controller of flow through the extend port of an auxiliary valve of a tractor which could be based on the commanded position of the valve.";
CM_ BO_ 2365463294 "This message provides the estimated flow of specified auxiliary valve.";
CM_ SG_ 2365463294 AuxValve10Exit_reasonCode "This parameter indicates why the Auxiliary Valve 10 cannot accept remote commands or has most recently stopped accepting remote commands.";
CM_ SG_ 2365463294 AuxValve10FailSafeMode "The measured state the fail safe mode of an auxiliary valve.";
CM_ SG_ 2365463294 AuxValve10State "The measured state of the auxiliary valve.   With float enabled, hydraulic fluid may flow to or from the tractor as driven by the implement.";
CM_ SG_ 2365463294 AuxValve10RetractPortEstFlow "The value reported by the controller of flow through the retract port of an auxiliary valve of a tractor which could be based on the commanded position of the valve.";
CM_ SG_ 2365463294 AuxValve10ExtendPortEstFlow "The value reported by the controller of flow through the extend port of an auxiliary valve of a tractor which could be based on the commanded position of the valve.";
CM_ BO_ 2365463038 "This message provides the estimated flow of specified auxiliary valve.";
CM_ SG_ 2365463038 AuxValve9Exit_reasonCode "This parameter indicates why the Auxiliary Valve 9 cannot accept remote commands or has most recently stopped accepting remote commands.";
CM_ SG_ 2365463038 AuxValve9FailSafeMode "The measured state the fail safe mode of an auxiliary valve.";
CM_ SG_ 2365463038 AuxValve9State "The measured state of the auxiliary valve.   With float enabled, hydraulic fluid may flow to or from the tractor as driven by the implement.";
CM_ SG_ 2365463038 AuxValve9RetractPortEstFlow "The value reported by the controller of flow through the retract port of an auxiliary valve of a tractor which could be based on the commanded position of the valve.";
CM_ SG_ 2365463038 AuxValve9ExtendPortEstFlow "The value reported by the controller of flow through the extend port of an auxiliary valve of a tractor which could be based on the commanded position of the valve.";
CM_ BO_ 2365462782 "This message provides the estimated flow of specified auxiliary valve.";
CM_ SG_ 2365462782 AuxValve8Exit_reasonCode "This parameter indicates why the Auxiliary Valve 8 cannot accept remote commands or has most recently stopped accepting remote commands.";
CM_ SG_ 2365462782 AuxValve8FailSafeMode "The measured state the fail safe mode of an auxiliary valve.";
CM_ SG_ 2365462782 AuxValve8State "The measured state of the auxiliary valve.   With float enabled, hydraulic fluid may flow to or from the tractor as driven by the implement.";
CM_ SG_ 2365462782 AuxValve8RetractPortEstFlow "The value reported by the controller of flow through the retract port of an auxiliary valve of a tractor which could be based on the commanded position of the valve.";
CM_ SG_ 2365462782 AuxValve8ExtendPortEstFlow "The value reported by the controller of flow through the extend port of an auxiliary valve of a tractor which could be based on the commanded position of the valve.";
CM_ BO_ 2365462526 "This message provides the estimated flow of specified auxiliary valve.";
CM_ SG_ 2365462526 AuxValve7Exit_reasonCode "This parameter indicates why the Auxiliary Valve 7 cannot accept remote commands or has most recently stopped accepting remote commands.";
CM_ SG_ 2365462526 AuxValve7FailSafeMode "The measured state the fail safe mode of an auxiliary valve.";
CM_ SG_ 2365462526 AuxValve7State "The measured state of the auxiliary valve.   With float enabled, hydraulic fluid may flow to or from the tractor as driven by the implement.";
CM_ SG_ 2365462526 AuxValve7RetractPortEstFlow "The value reported by the controller of flow through the retract port of an auxiliary valve of a tractor which could be based on the commanded position of the valve.";
CM_ SG_ 2365462526 AuxValve7ExtendPortEstFlow "The value reported by the controller of flow through the extend port of an auxiliary valve of a tractor which could be based on the commanded position of the valve.";
CM_ BO_ 2365462270 "This message provides the estimated flow of specified auxiliary valve.";
CM_ SG_ 2365462270 AuxValve6Exit_reasonCode "This parameter indicates why the Auxiliary Valve 6 cannot accept remote commands or has most recently stopped accepting remote commands.";
CM_ SG_ 2365462270 AuxValve6FailSafeMode "The measured state the fail safe mode of an auxiliary valve.";
CM_ SG_ 2365462270 AuxValve6State "The measured state of the auxiliary valve.   With float enabled, hydraulic fluid may flow to or from the tractor as driven by the implement.";
CM_ SG_ 2365462270 AuxValve6RetractPortEstFlow "The value reported by the controller of flow through the retract port of an auxiliary valve of a tractor which could be based on the commanded position of the valve.";
CM_ SG_ 2365462270 AuxValve6ExtendPortEstFlow "The value reported by the controller of flow through the extend port of an auxiliary valve of a tractor which could be based on the commanded position of the valve.";
CM_ BO_ 2365462014 "This message provides the estimated flow of specified auxiliary valve.";
CM_ SG_ 2365462014 AuxValve5Exit_reasonCode "This parameter indicates why the Auxiliary Valve 5 cannot accept remote commands or has most recently stopped accepting remote commands.";
CM_ SG_ 2365462014 AuxValve5FailSafeMode "The measured state the fail safe mode of an auxiliary valve.";
CM_ SG_ 2365462014 AuxValve5State "The measured state of the auxiliary valve.   With float enabled, hydraulic fluid may flow to or from the tractor as driven by the implement.";
CM_ SG_ 2365462014 AuxValve5RetractPortEstFlow "The value reported by the controller of flow through the retract port of an auxiliary valve of a tractor which could be based on the commanded position of the valve.";
CM_ SG_ 2365462014 AuxValve5ExtendPortEstFlow "The value reported by the controller of flow through the extend port of an auxiliary valve of a tractor which could be based on the commanded position of the valve.";
CM_ BO_ 2365461758 "This message provides the estimated flow of specified auxiliary valve.";
CM_ SG_ 2365461758 AuxValve4Exit_reasonCode "This parameter indicates why the Auxiliary Valve 4 cannot accept remote commands or has most recently stopped accepting remote commands.";
CM_ SG_ 2365461758 AuxValve4FailSafeMode "The measured state the fail safe mode of an auxiliary valve.";
CM_ SG_ 2365461758 AuxValve4State "The measured state of the auxiliary valve.   With float enabled, hydraulic fluid may flow to or from the tractor as driven by the implement.";
CM_ SG_ 2365461758 AuxValve4RetractPortEstFlow "The value reported by the controller of flow through the retract port of an auxiliary valve of a tractor which could be based on the commanded position of the valve.";
CM_ SG_ 2365461758 AuxValve4ExtendPortEstFlow "The value reported by the controller of flow through the extend port of an auxiliary valve of a tractor which could be based on the commanded position of the valve.";
CM_ BO_ 2365461502 "This message provides the estimated flow of specified auxiliary valve.";
CM_ SG_ 2365461502 AuxValve3Exit_reasonCode "This parameter indicates why the Auxiliary Valve 3 cannot accept remote commands or has most recently stopped accepting remote commands.";
CM_ SG_ 2365461502 AuxValve3FailSafeMode "The measured state the fail safe mode of an auxiliary valve.";
CM_ SG_ 2365461502 AuxValve3State "The measured state of the auxiliary valve.   With float enabled, hydraulic fluid may flow to or from the tractor as driven by the implement.";
CM_ SG_ 2365461502 AuxValve3RetractPortEstFlow "The value reported by the controller of flow through the retract port of an auxiliary valve of a tractor which could be based on the commanded position of the valve.";
CM_ SG_ 2365461502 AuxValve3ExtendPortEstFlow "The value reported by the controller of flow through the extend port of an auxiliary valve of a tractor which could be based on the commanded position of the valve.";
CM_ BO_ 2365461246 "This message provides the estimated flow of specified auxiliary valve.";
CM_ SG_ 2365461246 AuxValve2Exit_reasonCode "This parameter indicates why the Auxiliary Valve 2 cannot accept remote commands or has most recently stopped accepting remote commands.";
CM_ SG_ 2365461246 AuxValve2FailSafeMode "The measured state the fail safe mode of an auxiliary valve.";
CM_ SG_ 2365461246 AuxValve2State "The measured state of the auxiliary valve.   With float enabled, hydraulic fluid may flow to or from the tractor as driven by the implement.";
CM_ SG_ 2365461246 AuxValve2RetractPortEstFlow "The value reported by the controller of flow through the retract port of an auxiliary valve of a tractor which could be based on the commanded position of the valve.";
CM_ SG_ 2365461246 AuxValve2ExtendPortEstFlow "The value reported by the controller of flow through the extend port of an auxiliary valve of a tractor which could be based on the commanded position of the valve.";
CM_ BO_ 2365460990 "This message provides the estimated flow of specified auxiliary valve.";
CM_ SG_ 2365460990 AuxValve1Exit_reasonCode "This parameter indicates why the Auxiliary Valve 1 cannot accept remote commands or has most recently stopped accepting remote commands.";
CM_ SG_ 2365460990 AuxValve1FailSafeMode "The measured state the fail safe mode of an auxiliary valve.";
CM_ SG_ 2365460990 AuxValve1State "The measured state of the auxiliary valve.   With float enabled, hydraulic fluid may flow to or from the tractor as driven by the implement.";
CM_ SG_ 2365460990 AuxValve1RetractPortEstFlow "The value reported by the controller of flow through the retract port of an auxiliary valve of a tractor which could be based on the commanded position of the valve.";
CM_ SG_ 2365460990 AuxValve1ExtendPortEstFlow "The value reported by the controller of flow through the extend port of an auxiliary valve of a tractor which could be based on the commanded position of the valve.";
CM_ BO_ 2365460734 "This message provides the estimated flow of specified auxiliary valve.";
CM_ SG_ 2365460734 AuxValve0Exit_reasonCode "This parameter indicates why the Auxiliary Valve 0 cannot accept remote commands or has most recently stopped accepting remote commands.";
CM_ SG_ 2365460734 AuxValve0FailSafeMode "The measured state the fail safe mode of an auxiliary valve.";
CM_ SG_ 2365460734 AuxValve0State "The measured state of the auxiliary valve.   With float enabled, hydraulic fluid may flow to or from the tractor as driven by the implement.";
CM_ SG_ 2365460734 AuxValve0RetractPortEstFlow "The value reported by the controller of flow through the retract port of an auxiliary valve of a tractor which could be based on the commanded position of the valve.";
CM_ SG_ 2365460734 AuxValve0ExtendPortEstFlow "The value reported by the controller of flow through the extend port of an auxiliary valve of a tractor which could be based on the commanded position of the valve.";
CM_ BO_ 2365460478 "The language message has been defined as a global message to inform all ECUs on the 11783 bus the language that the operator wants to use, the date and time format and the units of measure with which the connected system should work.";
CM_ SG_ 2365460478 DistanceUnitCmd "Command to specify the distance units";
CM_ SG_ 2365460478 AreaUnitCmd "Command to specify the area units";
CM_ SG_ 2365460478 VolumeUnitCmd "Command to specify the volume units";
CM_ SG_ 2365460478 MassUnitCmd "Command to specify the mass units";
CM_ SG_ 2365460478 DateCmd "Command sent to all ECUs which specifies the displayed order of the date.";
CM_ SG_ 2365460478 DecimalSymbolCmd "Command sent to all ECUs which specifies that a decimal point or Comma should be displayed.";
CM_ SG_ 2365460478 TimeCmd "Command sent to all ECUs which specifies the displayed format of the time";
CM_ SG_ 2365460478 LanguageCodeCmd "Command sent to all ECUs which specifies the operator’s desired language of information.  ISO 11783 shall use the 2-character string country codes in ISO 639.";
CM_ BO_ 2365460222 "This global message is the response of the request of a specific user to change the repetition rate.";
CM_ SG_ 2365460222 DataDictionaryRow "This 4 bit parameter indicates the Row that is to be used within the specific Data Dictionary Table identified by the Implement Type. This is the Group (GRUP) in LBS documents.";
CM_ SG_ 2365460222 DataDictionaryColumn "This 4 bit parameter indicates the Column that is to be used within the specific Data Dictionary Table identified by the Implement Type. This is the Instance (INST) in LBS documents.";
CM_ SG_ 2365460222 ImplementType "This 4 bit parameter indicates which data dictionary page is to be used to locate the identity of the following data.";
CM_ SG_ 2365460222 ImplementPos "This 4 bit parameter of this message will indicate which Implement is referenced within a set of identical Implements.";
CM_ SG_ 2365460222 DataFormat_ErrorCondition "This 2 bit parameter that indicates the format or availability of the data in the following Process Data Parameter.";
CM_ SG_ 2365460222 ProcessDataType "This 2 bit parameter indicates what the data in the following Process Data Parameters is to be used for.";
CM_ SG_ 2365460222 ProcessDataModifier "This 3 bit parameter that indicates how the data in the following Process Data Parameters is to be used when combined with the Process Data Type parameter.";
CM_ SG_ 2365460222 RepetitionRateParameter "This parameter defines the repetition rate of the specified PGN.";
CM_ BO_ 2365459454 "This command is a task controller or an implement ECU to tractor ECU message.";
CM_ BO_ 2365459198 "This command is a task controller or an implement ECU to tractor ECU message.";
CM_ BO_ 2365458942 "Tractor response to an implement ECU or task controller tractor classification and facilities request";
CM_ BO_ 2365458686 "Implement response to task controller or Tractor ECU desired tractor classification and facilities";
CM_ BO_ 2365447934 "Message to transmit data of the towed vehicle to the towing vehicle. See ISO 11992-3.";
CM_ BO_ 2365447678 "Message to transmit data of the towing vehicle to the towed vehicle. See ISO 11992-3.";
CM_ BO_ 2365444094 "Message sent by the Master of a Working Set to identify how many members  there are  in said set.";
CM_ BO_ 2365443838 "Message sent by the Master of a Working Set to identify an individual member of a specific Working Set.";
CM_ SG_ 2365443838 NAMEOfWorkingSetMember "The identifier of the particular CA that is a member of the Working Set identified by the source address of this message.";
CM_ BO_ 2365434878 "This message is designed to cause all CAs to respond with the complete sequence of configuration identification messages for a particular one or all of the configurable messages that they send.";
CM_ SG_ 2365434878 PGNOfConfigurableMessageDesired "To identify the configurable message whose configuration is being requested. If the request is for all configurable PGNs then this SPN is set to all ones.";
CM_ SG_ 2365434878 MessageSelectionCtrl "Used to identify all configurable messages.";
CM_ BO_ 2566754814 "This contains parameters indicating the status of various breakers throughout a power generation system.  These include: Generator Circuit Breaker Status, Utility Circuit Breaker Status, and Automatic Transfer Switch status.";
CM_ SG_ 2566754814 AutomaticTransferSwitchStatus "This parameter indicates the measured state of the automatic transfer switch.
Bit state 000 = Normal position
Bit state 001 = Emergency position
Bit states 010-101 = available for SAE assignment
Bit state 110 = error
Bit state 111 = not ...";
CM_ SG_ 2566754814 UtilityCircuitBreakerStatus "This parameter indicates the measured state of the utility circuit breaker.
Bit state 000 = Open
Bit state 001 = Closed
Bit state 010 = Locked Out
Bit states 011-101 = available for SAE assignment
Bit state 110 = error
Bit state 111 = not ...";
CM_ SG_ 2566754814 GeneratorCircuitBreakerStatus "This parameter indicates the measured state of the generator circuit breaker.
Bit state 000 = Open
Bit state 001 = Closed
Bit state 010 = Locked Out
Bit states 011-101 = available for SAE assignment
Bit state 110 = error
Bit state 111 = not ...";
CM_ BO_ 2566754302 "This PGN contains quantities for the instantaneous AC power from the generator, as percentages of rated power";
CM_ SG_ 2566754302 GeneratorTotalPercentKVAr "This parameter reports the generator total AC reactive power, as a percentage of rated power.";
CM_ SG_ 2566754302 GeneratorTotalPercentKVA "This parameter reports the generator total AC apparent power, as a percentage of rated power.";
CM_ SG_ 2566754302 GeneratorTotalPercentKW "This parameter reports the generator total AC power, as a percentage of rated power.";
CM_ BO_ 2566754046 "This PGN contains quantities for the cumulative AC reactive energy from the generator.";
CM_ SG_ 2566754046 GeneratorTotalKVArHoursImport "This parameter reports the cumulative total AC reactive energy imported to the generator.";
CM_ SG_ 2566754046 GeneratorTotalKVArHoursExport "This parameter reports the cumulative total AC reactive energy exported from the generator.";
CM_ BO_ 2566753790 "This PGN contains quantities for the cumulative AC reactive energy from the utility.";
CM_ SG_ 2566753790 UtilityTotalKVArHoursImport "This parameter reports the cumulative total AC reactive energy imported to the utility.";
CM_ SG_ 2566753790 UtilityTotalKVArHoursExport "This parameter reports the cumulative total AC reactive energy exported from the utility.";
CM_ BO_ 2365411582 "Message to transmit data of the towing vehicle to the towed vehicle. See ISO 11992-3.";
CM_ BO_ 2365411326 "Message to transmit data of the towed vehicle to the towing vehicle. See ISO 11992-3.";
CM_ BO_ 2365411070 "Message to transmit data of the towed vehicle to the towing vehicle. See ISO 11992-3.";
CM_ BO_ 2365410814 "Message to transmit data of the towed vehicle to the towing vehicle. See ISO 11992-3.";
CM_ BO_ 2365410558 "Message to transmit data of the towed vehicle to the towing vehicle. See ISO 11992-3.";
CM_ BO_ 2365410302 "Message to transmit data of the towed vehicle to the towing vehicle. See ISO 11992-3.";
CM_ BO_ 2365410046 "Message to transmit data of the towed vehicle to the towing vehicle. See ISO 11992-3.";
CM_ BO_ 2365408254 "Message that provides the control of the machine speed and direction.";
CM_ SG_ 2365408254 MachineSelectedDirectionCmd "Commanded direction of travel of the machine.";
CM_ SG_ 2365408254 MchnSelectedSpeedExit_reasonCode "This parameter indicates why the Vehicle Speed control unit cannot currently accept remote commands or has most recently stopped accepting remote commands.";
CM_ SG_ 2365408254 MchineSelectedSpeedSetpointLimit "The machine's maximum allowed speed communicated to the tractor.";
CM_ SG_ 2365408254 MachineSelectedSpeedSetpointCmd "Commanded set point value of the machine speed as measured by the selected source.";
CM_ BO_ 2365407998 "This message reports the compliance certification status of a specific electronic control unit.";
CM_ SG_ 2365407998 ISOBUSCmplncCrtfctnRfrenceNumber "Certificate reference number assigned by Certification laboratory.  Uniquely identifies the test file from the Certification laboratory when use with the Certification laboratory ID and the ECU manufacturer ID.";
CM_ SG_ 2365407998 ISOBUSCmplncCrtfctonTypeTaskCtrl "Parameter used to indicate the type of compliance test performed.";
CM_ SG_ 2365407998 ISOBUSCmplncCrtfctnTypTCWrkn4326 "Parameter used to indicate the type of compliance test performed.";
CM_ SG_ 2365407998 ISOBUSCmplncCrtfctnTypTCWrkngStM "Parameter used to indicate the type of compliance test performed.";
CM_ SG_ 2365407998 ISOBUSCmplncCrtfctnTypFileServer "Parameter used to indicate the type of compliance test performed.";
CM_ SG_ 2365407998 ISOBUSCmplncCrtfctnTypGPSRceiver "Parameter used to indicate the type of compliance test performed.";
CM_ SG_ 2365407998 ISOBUSCmplncCrtfcationTypeMinECU "Parameter used to indicate the type of compliance test performed.";
CM_ SG_ 2365407998 ISOBUSCmplncCrtfctnTypTECUClass1 "Parameter used to indicate the type of compliance test performed.";
CM_ SG_ 2365407998 ISOBUSCmplncCrtfctnTypTECUClass2 "Parameter used to indicate the type of compliance test performed.";
CM_ SG_ 2365407998 ISOBUSCmplncCrtfctnTypTECUClass3 "Parameter used to indicate the type of compliance test performed.";
CM_ SG_ 2365407998 ISOBUSCmplncCrtfctnTypeClass3ECU "Parameter used to indicate the type of compliance test performed.";
CM_ SG_ 2365407998 ISOBUSCmplncCrtfctnTypVrtlTrmnal "Parameter used to indicate the type of compliance test performed.";
CM_ SG_ 2365407998 ISOBUSCmplncCrtfctnTypVTWrkn4323 "Parameter used to indicate the type of compliance test performed.";
CM_ SG_ 2365407998 ISOBUSCmplncCrtfctnTypVTWrkngStM "Parameter used to indicate the type of compliance test performed.";
CM_ SG_ 2365407998 ISOBUSCmplncCrtfctonLaboratoryID "Manufacturer code of the laboratory that performed the compliance test.  In the case of a self-certified ECU, this matches the manufacturer code contained in the address claim PGN.  See ISO 11783 Part 1 Annex B Table B6.";
CM_ SG_ 2365407998 ISOBUSCmplncCrtfctLaboratoryType "Approving body for the certification laboratory.";
CM_ SG_ 2365407998 ISOBUSCmplnceCertificateRevision "Revision of the ISOBUS compliance test performed.  In years where there are multiple revisions of the test protocol, an alphabetic suffix is used in addition to the certification year.";
CM_ SG_ 2365407998 ISOBUSCmplianceCertificationYear "Year of the compliance test protocol to which the certification test was performed.";
CM_ BO_ 2365403902 "The ECU level 1 diagnostic protocol message identifies the diagnostic protocol required by a service tool to troubleshoot a fault.";
CM_ BO_ 2365391870 "Message sent by the tractor ECU on the implement bus on forestry or agriculture implements providing to connected systems the current commanded implement operating state.";
CM_ SG_ 2365391870 ImplementOperatingStateCmd "Command for setting the operating state of a connected implement system.";
CM_ BO_ 2365391614 "Message sent by the tractor ECU Message sent by an ECU on the implement bus on forestry or agriculture implements providing to connected systems the current state of the all implement stop operations switch.";
CM_ SG_ 2365391614 AllImplmntStpOprtngOprtnsSwtchSt "State of a switch or other operator input for stopping the operation of a connected system.";
CM_ BO_ 2365379838 "Used by the XCP master (tool) to identify all XCP slaves on the network.";
CM_ BO_ 2365378302 "Message from to the tractor used to alter the powertrain DriveStrategy priority structure, which determines the balance between fuel economy/consumption and the torque reserve of the engine.";
CM_ BO_ 2365378046 "Message from the tractor to the implement showing the current status of the Drive Strategy priority structure, which indicates the priority of the multiple powertrain functions.";
CM_ SG_ 2566701566 TransOilTransCoolerOutletTemp "Temperature of transmission lubricant after it exits from the transmission cooler.";
CM_ SG_ 2566701566 TransClutch2Press "Gage pressure of hydraulic actuation fluid of transmission second clutch in a dual clutch application.";
CM_ BO_ 2499592446 "Electronic Transmission Controller #11";
CM_ SG_ 2499592446 TransShiftRail6Pos "The current position of transmission shift rail identified as rail #6.";
CM_ SG_ 2499592446 TransShiftRail5Pos "The current position of transmission shift rail identified as rail #5.";
CM_ SG_ 2499592446 TransShiftRail4Pos "The current position of transmission shift rail identified as rail #4.";
CM_ SG_ 2499592446 TransShiftRail3Pos "The current position of transmission shift rail identified as rail #3.";
CM_ SG_ 2499592446 TransShiftRail2Pos "The current position of transmission shift rail identified as rail #2.";
CM_ SG_ 2499592446 TransShiftRail1Pos "The current position of transmission shift rail identified as rail #1.";
CM_ BO_ 2499592190 "Electronic Transmission Controller #10";
CM_ SG_ 2499592190 TransHydPumpActuator2Percent "The current modulated value for actuator 2 that controls the transmission hydraulic pump, where 0% = no hydraulic pressure and 100% = full hydraulic pressure.";
CM_ SG_ 2499592190 TransShiftRail6ActuatorStatus "Identifies the status of the actuator that moves the transmission shift rail identified as rail #6.

00 = off
01 = on
10 = error
11 = not available";
CM_ SG_ 2499592190 TransShiftRail5ActuatorStatus "Identifies the status of the actuator that moves the transmission shift rail identified as rail #5.

00 = off
01 = on
10 = error
11 = not available";
CM_ SG_ 2499592190 TransShiftRail4ActuatorStatus "Identifies the status of the actuator that moves the transmission shift rail identified as rail #4.

00 = off
01 = on
10 = error
11 = not available";
CM_ SG_ 2499592190 TransShiftRail3ActuatorStatus "Identifies the status of the actuator that moves the transmission shift rail identified as rail #3.

00 = off
01 = on
10 = error
11 = not available";
CM_ SG_ 2499592190 TransShiftRail2ActuatorStatus "Identifies the status of the actuator that moves the transmission shift rail identified as rail #2.

00 = off
01 = on
10 = error
11 = not available";
CM_ SG_ 2499592190 TransShiftRail1ActuatorStatus "Identifies the status of the actuator that moves the transmission shift rail identified as rail #1.

00 = off
01 = on
10 = error
11 = not available";
CM_ SG_ 2499592190 TrnsClutch2CoolingActuatorStatus "Identifies the status of the actuator that cools transmission clutch 2.

00 = off
01 = on
10 = error
11 = not available";
CM_ SG_ 2499592190 TrnsClutch1CoolingActuatorStatus "Identifies the status of the actuator that cools transmission clutch 1.

00 = off
01 = on
10 = error
11 = not available";
CM_ SG_ 2499592190 TransShiftActuator2Percent "The current modulated value for the transmission shift 2 actuator, where 0% = no hydraulic pressure and 100% = full hydraulic pressure.";
CM_ SG_ 2499592190 TransShiftActuator1Percent "The current modulated value for the transmission shift 1 actuator, where 0% = no hydraulic pressure and 100% = full hydraulic pressure.";
CM_ SG_ 2499592190 TransHydPumpActuator1Percent "The current modulated value for the actuator that controls the transmission hydraulic pump, where 0% = no hydraulic pressure and 100% = full hydraulic pressure.";
CM_ SG_ 2499592190 TransClutch2ActuatorPercent "The current modulated value for the transmission clutch 2 actuator, where 0% = no hydraulic pressure and 100% = full hydraulic pressure.";
CM_ SG_ 2499592190 TransClutch1ActuatorPercent "The current modulated value for the transmission clutch 1 actuator, where 0% = no hydraulic pressure and 100% = full hydraulic pressure.";
CM_ BO_ 2365374206 "Electronic Transmission Controller #9
Note:
Single input shaft transmissions should use SPN 161 (Transmission Input Shaft Speed).
Multiple input shaft transmissions should use SPN 5960 and 5961 (DCT Input Shaft 1 and 2 Speeds).
For maximum ...";
CM_ SG_ 2365374206 DlCltchTrnsCrrntPreselectionGear "The gear currently engaged on the non-engaged clutch of a dual clutch transmission (DCT) or the last gear engaged on the non-engaged clutch while the transmission is in the process of pre-selecting to the new or selected pre-selection gear on the ...";
CM_ SG_ 2365374206 DlCltchTrnsSlctdPreselectionGear "The gear that the transmission will attempt to achieve during the current pre-selection event (shifting to a new gear on the non-engaged clutch of a dual clutch transmission (DCT)).";
CM_ SG_ 2365374206 DualClutchTransInputShaft2Speed "Rotational velocity of the primary shaft transferring power through clutch 2 into the dual clutch transmission (DCT).";
CM_ SG_ 2365374206 DualClutchTransInputShaft1Speed "Rotational velocity of the primary shaft transferring power through clutch 1 into the dual clutch transmission (DCT).";
CM_ BO_ 2566700542 "This message contains SCR service information for aftertreatment system 1 (or bank 1).";
CM_ SG_ 2566700542 AftrtrtmntTripDieselExhaustFluid "DEF consumed during all or part of a journey.";
CM_ SG_ 2566700542 Aftrtrtmnt1TtlDslExhustFluidUsed "Total amount of DEF used by aftertreatment device 1 over the lifetime of the device.";
CM_ BO_ 2566700286 "This message contains SCR service information for aftertreatment system 2 (or bank 2).";
CM_ SG_ 2566700286 Aftrtrtmnt2TtlDslExhustFluidUsed "Total amount of DEF used by aftertreatment device 2 over the lifetime of the device.";
CM_ BO_ 2566700030 "Information relating to SCR electronic control module of aftertreatment 1 (bank 1).";
CM_ SG_ 2566700030 Aftrtrtmnt1DslExhstFldCtrlMd6309 "State signal which indicates when the DEF control module power supply 2 of aftertreatment 1 is being driven. On means the ECU is powering the aftertreatment 1 DEF control module power supply. Note that the control module is external to the ECU.
00 ...";
CM_ SG_ 2566700030 Aftrtrtmnt1DslExhstFldCtrlMdlPwr "State signal which indicates when the DEF control module power supply of aftertreatment 1 is being driven. On means the ECU is powering the aftertreatment 1 DEF control module power supply. Note that the control module is external to the ECU.
00 – ...";
CM_ SG_ 2566700030 Aftrtrtmnt1DslExhstFldCtrlMdlRly "State signal which indicates when the DEF control module relay of aftertreatment 1 is being energized. On means the ECU is powering the Aftertreatment 1 DEF dosing unit relay. Note that the ECU is external to the relay.
00 – Off
01 – On: The ECU ...";
CM_ BO_ 2566699774 "Information relating to SCR electronic control module of aftertreatment 2 (bank 2).";
CM_ SG_ 2566699774 Aftrtrtmnt2DslExhstFldCtrlMd6310 "State signal which indicates when the DEF control module power supply 2 of aftertreatment 2 is being driven. On means the ECU is powering the aftertreatment 2 DEF control module power supply. Note that the control module is external to the ECU.
00 ...";
CM_ SG_ 2566699774 Aftrtrtmnt2DslExhstFldCtrlMdlPwr "State signal which indicates when the DEF control module power supply of aftertreatment 2 is being driven. On means the ECU is powering the aftertreatment 2 DEF control module power supply. Note that the control module is external to the ECU.
00 – ...";
CM_ SG_ 2566699774 Aftrtrtmnt2DslExhstFldCtrlMdlRly "State signal which indicates when the DEF control module relay of aftertreatment 2 is being energized. On means the ECU is powering the Aftertreatment 2 DEF dosing unit relay. Note that the ECU is external to the relay.
00 – Off
01 – On: The ECU ...";
CM_ BO_ 2566699518 "This PGN contains information about the aftertreatment 1.";
CM_ SG_ 2566699518 Aftrtrtmnt1DslPrtcltFltrTmTNxtAc "Indicates the time to the next active regeneration event of diesel particulate filter 1.";
CM_ BO_ 2566699262 "This PGN contains information about the aftertreatment 2.";
CM_ SG_ 2566699262 Aftrtrtmnt2DslPrtcltFltrTmTNxtAc "Indicates the time to the next active regeneration event of diesel particulate filter 2.";
CM_ BO_ 2566698750 "PGN containing vehicle electrical power information for the battery pack used for starting, lighting, and ignition.";
CM_ SG_ 2566698750 SLIBatteryPackHealth "Capacity of the battery pack relative to its original specification for the battery pack used for starting the engine, for lighting, and for ignition (SLI). 0% means battery pack is not capable of holding any charge, 100% means battery pack is ...";
CM_ SG_ 2566698750 SLIBatteryPackCapacity "Original or rated total reserve capacity of the battery pack used for starting the engine, for lighting, and for ignition (SLI).";
CM_ SG_ 2566698750 SLIBatteryPackStateOfCharge "Indicates the remaining charge of the battery pack used for starting the engine, for lighting, and for ignition (SLI). 0% means no charge remaining, 100% means full capacity at the battery pack's current state of health.   See SPN 5464 for hybrid ...";
CM_ BO_ 2566698494 "Fused power output status is sent by the Power Distribution Module (PDM) to indicate the state of the PDM's fused outputs.
This message is sent once every second (1000ms) and on change of any fused power output status, but
no faster than once ...";
CM_ SG_ 2566698494 FusedOutput29 "State of Fused Output #29. Used to indicate the output state.

00 - Output not powered
01 - Output powered
10 - Reserved
11 - Take no action";
CM_ SG_ 2566698494 FusedOutput30 "State of Fused Output #30. Used to indicate the output state.

00 - Output not powered
01 - Output powered
10 - Reserved
11 - Take no action";
CM_ SG_ 2566698494 FusedOutput31 "State of Fused Output #31. Used to indicate the output state.

00 - Output not powered
01 - Output powered
10 - Reserved
11 - Take no action";
CM_ SG_ 2566698494 FusedOutput32 "State of Fused Output #32. Used to indicate the output state.

00 - Output not powered
01 - Output powered
10 - Reserved
11 - Take no action";
CM_ SG_ 2566698494 FusedOutput25 "State of Fused Output #25. Used to indicate the output state.

00 - Output not powered
01 - Output powered
10 - Reserved
11 - Take no action";
CM_ SG_ 2566698494 FusedOutput26 "State of Fused Output #26. Used to indicate the output state.

00 - Output not powered
01 - Output powered
10 - Reserved
11 - Take no action";
CM_ SG_ 2566698494 FusedOutput27 "State of Fused Output #27. Used to indicate the output state.

00 - Output not powered
01 - Output powered
10 - Reserved
11 - Take no action";
CM_ SG_ 2566698494 FusedOutput28 "State of Fused Output #28. Used to indicate the output state.

00 - Output not powered
01 - Output powered
10 - Reserved
11 - Take no action";
CM_ SG_ 2566698494 FusedOutput21 "State of Fused Output #21. Used to indicate the output state.

00 - Output not powered
01 - Output powered
10 - Reserved
11 - Take no action";
CM_ SG_ 2566698494 FusedOutput22 "State of Fused Output #22. Used to indicate the output state.

00 - Output not powered
01 - Output powered
10 - Reserved
11 - Take no action";
CM_ SG_ 2566698494 FusedOutput23 "State of Fused Output #23. Used to indicate the output state.

00 - Output not powered
01 - Output powered
10 - Reserved
11 - Take no action";
CM_ SG_ 2566698494 FusedOutput24 "State of Fused Output #24. Used to indicate the output state.

00 - Output not powered
01 - Output powered
10 - Reserved
11 - Take no action";
CM_ SG_ 2566698494 FusedOutput17 "State of Fused Output #17. Used to indicate the output state.

00 - Output not powered
01 - Output powered
10 - Reserved
11 - Take no action";
CM_ SG_ 2566698494 FusedOutput18 "State of Fused Output #18. Used to indicate the output state.

00 - Output not powered
01 - Output powered
10 - Reserved
11 - Take no action";
CM_ SG_ 2566698494 FusedOutput19 "State of Fused Output #19. Used to indicate the output state.

00 - Output not powered
01 - Output powered
10 - Reserved
11 - Take no action";
CM_ SG_ 2566698494 FusedOutput20 "State of Fused Output #20. Used to indicate the output state.

00 - Output not powered
01 - Output powered
10 - Reserved
11 - Take no action";
CM_ SG_ 2566698494 FusedOutput13 "State of Fused Output #13. Used to indicate the output state.

00 - Output not powered
01 - Output powered
10 - Reserved
11 - Take no action";
CM_ SG_ 2566698494 FusedOutput14 "State of Fused Output #14. Used to indicate the output state.

00 - Output not powered
01 - Output powered
10 - Reserved
11 - Take no action";
CM_ SG_ 2566698494 FusedOutput15 "State of Fused Output #15. Used to indicate the output state.

00 - Output not powered
01 - Output powered
10 - Reserved
11 - Take no action";
CM_ SG_ 2566698494 FusedOutput16 "State of Fused Output #16. Used to indicate the output state.

00 - Output not powered
01 - Output powered
10 - Reserved
11 - Take no action";
CM_ SG_ 2566698494 FusedOutput9 "State of Fused Output #9. Used to indicate the output state.

00 - Output not powered
01 - Output powered
10 - Reserved
11 - Take no action";
CM_ SG_ 2566698494 FusedOutput10 "State of Fused Output #10. Used to indicate the output state.

00 - Output not powered
01 - Output powered
10 - Reserved
11 - Take no action";
CM_ SG_ 2566698494 FusedOutput11 "State of Fused Output #11. Used to indicate the output state.

00 - Output not powered
01 - Output powered
10 - Reserved
11 - Take no action";
CM_ SG_ 2566698494 FusedOutput12 "State of Fused Output #12. Used to indicate the output state.

00 - Output not powered
01 - Output powered
10 - Reserved
11 - Take no action";
CM_ SG_ 2566698494 FusedOutput5 "State of Fused Output #5. Used to indicate the output state.

00 - Output not powered
01 - Output powered
10 - Reserved
11 - Take no action";
CM_ SG_ 2566698494 FusedOutput6 "State of Fused Output #6. Used to indicate the output state.

00 - Output not powered
01 - Output powered
10 - Reserved
11 - Take no action";
CM_ SG_ 2566698494 FusedOutput7 "State of Fused Output #7. Used to indicate the output state.

00 - Output not powered
01 - Output powered
10 - Reserved
11 - Take no action";
CM_ SG_ 2566698494 FusedOutput8 "State of Fused Output #8. Used to indicate the output state.

00 - Output not powered
01 - Output powered
10 - Reserved
11 - Take no action";
CM_ SG_ 2566698494 FusedOutput1 "State of Fused Output #1. Used to indicate the output state.

00 - Output not powered
01 - Output powered
10 - Reserved
11 - Take no action";
CM_ SG_ 2566698494 FusedOutput2 "State of Fused Output #2. Used to indicate the output state.

00 - Output not powered
01 - Output powered
10 - Reserved
11 - Take no action";
CM_ SG_ 2566698494 FusedOutput3 "State of Fused Output #3. Used to indicate the output state.

00 - Output not powered
01 - Output powered
10 - Reserved
11 - Take no action";
CM_ SG_ 2566698494 FusedOutput4 "State of Fused Output #4. Used to indicate the output state.

00 - Output not powered
01 - Output powered
10 - Reserved
11 - Take no action";
CM_ BO_ 2559115006 "Message used to request the wireless transceiver to transmit a special beacon signal and to report
the reception of a special beacon signal by a wireless transceiver. A unique number is included in
each beacon signal to differentiate beacon ...";
CM_ SG_ 2559115006 WirelessSignalStrength2 "The absolute received signal strength of the special beacon signal received from the off-board transmitter. The signal strength is reported as a Received Signal Strength Indicator (RSSI) value in dBm. This measurement method is identical to SPN 5753 ...";
CM_ SG_ 2559115006 TransmitterID2 "The ID of the off-board transmitter that sent the incoming special beacon message received by the wireless transceiver.";
CM_ SG_ 2559115006 RadioBeaconDirection "Indicates the function of a particular instance of the Radio Beacon Request message. The 'Beacon Request' state indicates the message is sent to a wireless transceiver to request a transmit of the special beacon message. The 'Beacon Received ...";
CM_ SG_ 2559115006 UnqBeaconMessageIdentifierNumber "The number is used to identify a wireless message originating from a device on a particular machine. Within a beacon request message (see SPN 5755 [Radio Beacon Direction]), this number is included in the transmitted beacon signal. Within a beacon ...";
CM_ BO_ 2566707454 "This message is used to specify up to 4 soot sensor analysis frequencies to request the soot sensor signal data associated with those analysis frequencies for aftertreatment 1 diesel particulate filter 2.";
CM_ SG_ 2566707454 Aftrtrtmnt1DslPrtcltFltr2StS5647 "Fourth requested analysis frequency for the diesel particulate filter 2 soot sensor.";
CM_ SG_ 2566707454 Aftrtrtmnt1DslPrtcltFltr2StS5646 "Third requested analysis frequency for the diesel particulate filter 2 soot sensor.";
CM_ SG_ 2566707454 Aftrtrtmnt1DslPrtcltFltr2StS5645 "Second requested analysis frequency for the diesel particulate filter 2 soot sensor.";
CM_ SG_ 2566707454 Aftrtrtmnt1DslPrtcltFltr2StSnsrA "First requested analysis frequency for the diesel particulate filter 2 soot sensor.";
CM_ BO_ 2566707198 "This message is used report the analysis frequency and associated soot sensor signal data for two of the requested analysis frequencies for aftertreatment 1 diesel particulate filter 2.";
CM_ SG_ 2566707198 Aftrtrtmnt1DslPrtcltFltr2StS5651 "The soot signal attenuation measurement for analysis frequency 2 for the diesel particulate filter 2 soot sensor.  See SPN 5645.";
CM_ SG_ 2566707198 Aftrtrtmnt1DslPrtcltFltr2StS5650 "The analysis frequency associated with the frequency 2 soot signal for the diesel particulate filter 2 soot sensor.  See SPN 5645.";
CM_ SG_ 2566707198 Aftrtrtmnt1DslPrtcltFltr2StSnsrF "The soot signal attenuation measurement for analysis frequency 1 for the diesel particulate filter 2 soot sensor.  See SPN 5644.";
CM_ SG_ 2566707198 Aftrtrtmnt1DslPrtcltFltr2StSnsrA "The analysis frequency associated with the frequency 1 soot signal for the diesel particulate filter 2 soot sensor.  See SPN 5644.";
CM_ BO_ 2566706942 "Diesel particulate filter soot parameters for the aftertreatment 1 diesel particulate filter 2.";
CM_ SG_ 2566706942 Aftrtrtmnt1DslPrtcltFltr2StS5655 "The soot signal attenuation measurement for analysis frequency 4 for the diesel particulate filter 2 soot sensor.  See SPN 5647.";
CM_ SG_ 2566706942 Aftrtrtmnt1DslPrtcltFltr2StS5654 "The analysis frequency associated with the frequency 4 soot signal for the diesel particulate filter 2 soot sensor.  See SPN 5647.";
CM_ SG_ 2566706942 Aftrtrtmnt1DslPrtcltFltr2StSnsrF "The soot signal attenuation measurement for analysis frequency 3 for the diesel particulate filter 2 soot sensor.  See SPN 5646.";
CM_ SG_ 2566706942 Aftrtrtmnt1DslPrtcltFltr2StSnsrA "The analysis frequency associated with the frequency 3 soot signal for the diesel particulate filter 2 soot sensor.  See SPN 5646.";
CM_ BO_ 2559770366 "This PGN contains information about the HC Doser and the Diesel Particulate Filter";
CM_ SG_ 2559770366 HydrocarbonDoserPurgingRequired "Purging of the Hydrocarbon Doser (HCD) is required.  Request could come from the HCD system.

00   Purging not required
01   Purging required - less urgent
10   Purging required - urgent
11   Not available";
CM_ SG_ 2559770366 DiagnosticStatusOfHCDoser "Indicates whether an error is active in the Hydrocarbon Doser (HCD) or whether the internal cyclic system test of the HCD is presently active.
This is not intended to replace the DM8/DM30 - Test results requirement for OBD.
000 System test has ...";
CM_ SG_ 2559770366 HCDoserInjectingStatus "Indicates whether the Hydrocarbon Doser (HCD) is presently injecting diesel fuel into the exhaust pipe.

00 Injecting not active
01 Injecting active
10 Error
11 Not available";
CM_ SG_ 2559770366 HCDoserStatus "Indicates whether the HC Doser/ HC Dosing system is enabled or is waiting for regeneration.
000 HC doser disabled
001 HC doser active
010 SAE reserved
011 HC doser enabled, waiting for regeneration
100 SAE reserved
101 SAE reserved
110 Error
 ...";
CM_ SG_ 2559770366 RequestedFuelMassRate "Requested fuel dosing quantity from hydrocarbon doser.";
CM_ BO_ 2559704830 "Used to command a vehicle/chassis lubrication system";
CM_ SG_ 2559704830 LubricationTimingCycleCmd "Command signal to enable or pause the lubrication activation clock
00 - Pause
01 - Enable
10 - Reserved
11 - Take no action
Note:  In some vehicles or machines the lubrication is only required when the vehicle or machine is in certain state ...";
CM_ SG_ 2559704830 LubricationPumpEnableCmd "Command signal to reset the lubrication pump.  It allows the operator and/or technician to reset the paused lubrication pump and clear lubrication system faults. This shall enable the lubrication system to resume its normal operation.
00 - No ...";
CM_ SG_ 2559704830 LubricationOperationModeSetCmd "Command signal to change lubrication system operational mode. The mode set command gives the operator and/or technician the ability to change the operational mode when diagnosing and servicing of the system is required.
Automatic is the normal ...";
CM_ SG_ 2559704830 LubricationCycleSetCmd "Command signal to change the lubrication cycle. It gives the operator or technician the ability to the change the frequency of lubrication.
000 - Cycle mode # 1 (Lowest Lubrication Frequency)
001 - Cycle mode # 2
010 - Cycle mode # 3 (Highest ...";
CM_ SG_ 2559704830 LubricationCycleModeLockCmd "Command signal to lock or unlock the ability to change the lubrication cycle mode.  Locking the lubrication mode would prevent the changing of the lubrication cycle mode, perhaps by an operator.
00 - Not Locked
01 - Locked
10 - Reserved
11 - No ...";
CM_ BO_ 2559639294 "Command message to control the speed and direction of Supplemental Fan for additional cooling beyond that of the primary cooling fan. For Example, this fan could be used to provide additional cooling to an aftertreatment system";
CM_ SG_ 2559639294 SupplementalFanPowerHold "Command to allow the supplemental fan controller to remain alive independently of the electrical enable input to the fan. This allows the fan controller to remain alive after the keyswitch has disabled the electrical enable pin on the fan ...";
CM_ SG_ 2559639294 SupplementalFanSpeedCmd "Speed command to Supplemental Fan.";
CM_ SG_ 2559639294 SupplementalFanDirectionCmd "Direction command to the Supplemental Fan. Fan can be commanded to run forward or reverse.

00   Forward
01   Reverse
10   Reserved
11   Don't care/take no action (leave function as is)";
CM_ SG_ 2559639294 SupplementalFanEnableCmd "Enable/Disable command to Supplemental Fan.

00  Disable 
01  Enable
10  Reserved 
11  Don't Care/Take no action";
CM_ BO_ 2559573758 "This PGN contains parameters that are used to configure engine operation.";
CM_ SG_ 2559573758 ClntLvlEngPrtctnShtdwnOvrrideCmd "Overrides the engine protection shutdown functionality due to low coolant level.
00 - Disable engine protection shutdown override due to low coolant level
01 - Enable engine protection shutdown override due to low coolant level
10 - Reserved
11 ...";
CM_ BO_ 2349530878 "Cruise Control / Vehicle Speed 2";
CM_ SG_ 2349530878 CruiseCtrlPauseCmd "This parameter is used to temporarily disable cruise control from a source other than the driver controlled switch if cruise control is active.  If this parameter is used to disable cruise control, then cruise control will not need to be ...";
CM_ SG_ 2349530878 CruiseCtrlResumeCmd "This parameter is used to request the cruise control to resume operation from a source other than the driver controlled switch.  Implementers may wish to restrict the conditions in which cruise control will be resumed due to this parameter ...";
CM_ SG_ 2349530878 CruiseCtrlDisableCmd "This parameter is used to disable cruise control from a source other than the driver controlled switch if cruise control is active.  It is also used to inhibit cruise control from becoming active if it is not currently active.  If this parameter is ...";
CM_ BO_ 2566698238 "Switched power output status is sent by the Power Distribution Module (PDM) to indicate the status of the PDM's switched power outputs.
This message is sent once every second (1000ms) and on change of any switched power output status, but no faster ...";
CM_ SG_ 2566698238 SwitchedOutput29 "State of Switched Output #29. Used to indicate the output state.

00 - Output off
01 - Output on
10 - Reserved
11 - Take no action";
CM_ SG_ 2566698238 SwitchedOutput30 "State of Switched Output #30. Used to indicate the output state.

00 - Output off
01 - Output on
10 - Reserved
11 - Take no action";
CM_ SG_ 2566698238 SwitchedOutput31 "State of Switched Output #31. Used to indicate the output state.

00 - Output off
01 - Output on
10 - Reserved
11 - Take no action";
CM_ SG_ 2566698238 SwitchedOutput32 "State of Switched Output #32. Used to indicate the output state.

00 - Output off
01 - Output on
10 - Reserved
11 - Take no action";
CM_ SG_ 2566698238 SwitchedOutput25 "State of Switched Output #25. Used to indicate the output state.

00 - Output off
01 - Output on
10 - Reserved
11 - Take no action";
CM_ SG_ 2566698238 SwitchedOutput26 "State of Switched Output #26. Used to indicate the output state.

00 - Output off
01 - Output on
10 - Reserved
11 - Take no action";
CM_ SG_ 2566698238 SwitchedOutput27 "State of Switched Output #27. Used to indicate the output state.

00 - Output off
01 - Output on
10 - Reserved
11 - Take no action";
CM_ SG_ 2566698238 SwitchedOutput28 "State of Switched Output #28. Used to indicate the output state.

00 - Output off
01 - Output on
10 - Reserved
11 - Take no action";
CM_ SG_ 2566698238 SwitchedOutput21 "State of Switched Output #21. Used to indicate the output state.

00 - Output off
01 - Output on
10 - Reserved
11 - Take no action";
CM_ SG_ 2566698238 SwitchedOutput22 "State of Switched Output #22. Used to indicate the output state.

00 - Output off
01 - Output on
10 - Reserved
11 - Take no action";
CM_ SG_ 2566698238 SwitchedOutput23 "State of Switched Output #23. Used to indicate the output state.

00 - Output off
01 - Output on
10 - Reserved
11 - Take no action";
CM_ SG_ 2566698238 SwitchedOutput24 "State of Switched Output #24. Used to indicate the output state.

00 - Output off
01 - Output on
10 - Reserved
11 - Take no action";
CM_ SG_ 2566698238 SwitchedOutput17 "State of Switched Output #17. Used to indicate the output state.

00 - Output off
01 - Output on
10 - Reserved
11 - Take no action";
CM_ SG_ 2566698238 SwitchedOutput18 "State of Switched Output #18. Used to indicate the output state.

00 - Output off
01 - Output on
10 - Reserved
11 - Take no action";
CM_ SG_ 2566698238 SwitchedOutput19 "State of Switched Output #19. Used to indicate the output state.

00 - Output off
01 - Output on
10 - Reserved
11 - Take no action";
CM_ SG_ 2566698238 SwitchedOutput20 "State of Switched Output #20. Used to indicate the output state.

00 - Output off
01 - Output on
10 - Reserved
11 - Take no action";
CM_ SG_ 2566698238 SwitchedOutput13 "State of Switched Output #13. Used to indicate the output state.

00 - Output off
01 - Output on
10 - Reserved
11 - Take no action";
CM_ SG_ 2566698238 SwitchedOutput14 "State of Switched Output #14. Used to indicate the output state.

00 - Output off
01 - Output on
10 - Reserved
11 - Take no action";
CM_ SG_ 2566698238 SwitchedOutput15 "State of Switched Output #15. Used to indicate the output state.

00 - Output off
01 - Output on
10 - Reserved
11 - Take no action";
CM_ SG_ 2566698238 SwitchedOutput16 "State of Switched Output #16. Used to indicate the output state.

00 - Output off
01 - Output on
10 - Reserved
11 - Take no action";
CM_ SG_ 2566698238 SwitchedOutput9 "State of Switched Output #9. Used to indicate the output state.

00 - Output off
01 - Output on
10 - Reserved
11 - Take no action";
CM_ SG_ 2566698238 SwitchedOutput10 "State of Switched Output #10. Used to indicate the output state.

00 - Output off
01 - Output on
10 - Reserved
11 - Take no action";
CM_ SG_ 2566698238 SwitchedOutput11 "State of Switched Output #11. Used to indicate the output state.

00 - Output off
01 - Output on
10 - Reserved
11 - Take no action";
CM_ SG_ 2566698238 SwitchedOutput12 "State of Switched Output #12. Used to indicate the output state.

00 - Output off
01 - Output on
10 - Reserved
11 - Take no action";
CM_ SG_ 2566698238 SwitchedOutput5 "State of Switched Output #5. Used to indicate the output state.

00 - Output off
01 - Output on
10 - Reserved
11 - Take no action";
CM_ SG_ 2566698238 SwitchedOutput6 "State of Switched Output #6. Used to indicate the output state.

00 - Output off
01 - Output on
10 - Reserved
11 - Take no action";
CM_ SG_ 2566698238 SwitchedOutput7 "State of Switched Output #7. Used to indicate the output state.

00 - Output off
01 - Output on
10 - Reserved
11 - Take no action";
CM_ SG_ 2566698238 SwitchedOutput8 "State of Switched Output #8. Used to indicate the output state.

00 - Output off
01 - Output on
10 - Reserved
11 - Take no action";
CM_ SG_ 2566698238 SwitchedOutput1 "State of Switched Output #1. Used to indicate the output state.

00 - Output off
01 - Output on
10 - Reserved
11 - Take no action";
CM_ SG_ 2566698238 SwitchedOutput2 "State of Switched Output #2. Used to indicate the output state.

00 - Output off
01 - Output on
10 - Reserved
11 - Take no action";
CM_ SG_ 2566698238 SwitchedOutput3 "State of Switched Output #3. Used to indicate the output state.

00 - Output off
01 - Output on
10 - Reserved
11 - Take no action";
CM_ SG_ 2566698238 SwitchedOutput4 "State of Switched Output #4. Used to indicate the output state.

00 - Output off
01 - Output on
10 - Reserved
11 - Take no action";
CM_ BO_ 2566697982 "Fused power output current reports the measured electrical current flowing out of all fused outputs on the Power Distribution Module (PDM).";
CM_ SG_ 2566697982 FusedOutput32Current "Measured electrical current flowing out of Power Distribution Module (PDM) Fused Output #32.";
CM_ SG_ 2566697982 FusedOutput31Current "Measured electrical current flowing out of Power Distribution Module (PDM) Fused Output #31.";
CM_ SG_ 2566697982 FusedOutput30Current "Measured electrical current flowing out of Power Distribution Module (PDM) Fused Output #30.";
CM_ SG_ 2566697982 FusedOutput29Current "Measured electrical current flowing out of Power Distribution Module (PDM) Fused Output #29.";
CM_ SG_ 2566697982 FusedOutput28Current "Measured electrical current flowing out of Power Distribution Module (PDM) Fused Output #28.";
CM_ SG_ 2566697982 FusedOutput27Current "Measured electrical current flowing out of Power Distribution Module (PDM) Fused Output #27.";
CM_ SG_ 2566697982 FusedOutput26Current "Measured electrical current flowing out of Power Distribution Module (PDM) Fused Output #26.";
CM_ SG_ 2566697982 FusedOutput25Current "Measured electrical current flowing out of Power Distribution Module (PDM) Fused Output #25.";
CM_ SG_ 2566697982 FusedOutput24Current "Measured electrical current flowing out of Power Distribution Module (PDM) Fused Output #24.";
CM_ SG_ 2566697982 FusedOutput23Current "Measured electrical current flowing out of Power Distribution Module (PDM) Fused Output #23.";
CM_ SG_ 2566697982 FusedOutput22Current "Measured electrical current flowing out of Power Distribution Module (PDM) Fused Output #22.";
CM_ SG_ 2566697982 FusedOutput21Current "Measured electrical current flowing out of Power Distribution Module (PDM) Fused Output #21.";
CM_ SG_ 2566697982 FusedOutput20Current "Measured electrical current flowing out of Power Distribution Module (PDM) Fused Output #20.";
CM_ SG_ 2566697982 FusedOutput19Current "Measured electrical current flowing out of Power Distribution Module (PDM) Fused Output #19.";
CM_ SG_ 2566697982 FusedOutput18Current "Measured electrical current flowing out of Power Distribution Module (PDM) Fused Output #18.";
CM_ SG_ 2566697982 FusedOutput17Current "Measured electrical current flowing out of Power Distribution Module (PDM) Fused Output #17.";
CM_ SG_ 2566697982 FusedOutput16Current "Measured electrical current flowing out of Power Distribution Module (PDM) Fused Output #16.";
CM_ SG_ 2566697982 FusedOutput15Current "Measured electrical current flowing out of Power Distribution Module (PDM) Fused Output #15.";
CM_ SG_ 2566697982 FusedOutput14Current "Measured electrical current flowing out of Power Distribution Module (PDM) Fused Output #14.";
CM_ SG_ 2566697982 FusedOutput13Current "Measured electrical current flowing out of Power Distribution Module (PDM) Fused Output #13.";
CM_ SG_ 2566697982 FusedOutput12Current "Measured electrical current flowing out of Power Distribution Module (PDM) Fused Output #12.";
CM_ SG_ 2566697982 FusedOutput11Current "Measured electrical current flowing out of Power Distribution Module (PDM) Fused Output #11.";
CM_ SG_ 2566697982 FusedOutput10Current "Measured electrical current flowing out of Power Distribution Module (PDM) Fused Output #10.";
CM_ SG_ 2566697982 FusedOutput9Current "Measured electrical current flowing out of Power Distribution Module (PDM) Fused Output #9.";
CM_ SG_ 2566697982 FusedOutput8Current "Measured electrical current flowing out of Power Distribution Module (PDM) Fused Output #8.";
CM_ SG_ 2566697982 FusedOutput7Current "Measured electrical current flowing out of Power Distribution Module (PDM) Fused Output #7.";
CM_ SG_ 2566697982 FusedOutput6Current "Measured electrical current flowing out of Power Distribution Module (PDM) Fused Output #6.";
CM_ SG_ 2566697982 FusedOutput5Current "Measured electrical current flowing out of Power Distribution Module (PDM) Fused Output #5.";
CM_ SG_ 2566697982 FusedOutput4Current "Measured electrical current flowing out of Power Distribution Module (PDM) Fused Output #4.";
CM_ SG_ 2566697982 FusedOutput3Current "Measured electrical current flowing out of Power Distribution Module (PDM) Fused Output #3.";
CM_ SG_ 2566697982 FusedOutput2Current "Measured electrical current flowing out of Power Distribution Module (PDM) Fused Output #2.";
CM_ SG_ 2566697982 FusedOutput1Current "Measured electrical current flowing out of Power Distribution Module (PDM) Fused Output #1.";
BA_DEF_ SG_  "SigType" ENUM  "Default","Range","RangeSigned","ASCII","Discrete","Control","ReferencePGN","DTC","StringDelimiter","StringLength","StringLengthControl","MessageCounter","MessageChecksum";
BA_DEF_ SG_  "GenSigStartValue" INT 0 10000;
BA_DEF_ SG_  "GenSigSendType" ENUM  "Cyclic","OnWrite","OnWriteWithRepetition","OnChange","OnChangeWithRepetition","IfActive","IfActiveWithRepetition","NoSigSendType";
BA_DEF_ SG_  "GenSigILSupport" ENUM  "No","Yes";
BA_DEF_ SG_  "GenSigEVName" STRING ;
BA_DEF_ SG_  "SPN" INT 0 524287;
BA_DEF_  "SAE_J1939_DA_SpecVersion" STRING ;
BA_DEF_ BO_  "GenMsgStartDelayTime" INT 0 100000;
BA_DEF_ BO_  "GenMsgILSupport" ENUM  "No","Yes";
BA_DEF_ BO_  "GenMsgRequestable" INT 0 1;
BA_DEF_ BO_  "GenMsgSendType" ENUM  "cyclic","NotUsed","NotUsed","NotUsed","NotUsed","NotUsed","NotUsed","IfActive","noMsgSendType";
BA_DEF_ BO_  "VFrameFormat" ENUM  "StandardCAN","ExtendedCAN","reserved","J1939PG";
BA_DEF_ BO_  "GenMsgCycleTime" INT 0 3600000;
BA_DEF_ BU_  "NmStationAddress" INT 0 255;
BA_DEF_ BU_  "NmJ1939IndustryGroup" INT 0 7;
BA_DEF_ BU_  "NmJ1939System" INT 0 127;
BA_DEF_ BU_  "NmJ1939Function" INT 0 255;
BA_DEF_ BU_  "NmJ1939FunctionInstance" INT 0 7;
BA_DEF_ BU_  "NmJ1939ECUInstance" INT 0 3;
BA_DEF_  "SAE_J1939_81_SpecVersion" STRING ;
BA_DEF_  "DatabaseVersion" STRING ;
BA_DEF_  "BusType" STRING ;
BA_DEF_  "ProtocolType" STRING ;
BA_DEF_  "SAE_J1939_75_SpecVersion" STRING ;
BA_DEF_  "SAE_J1939_21_SpecVersion" STRING ;
BA_DEF_  "SAE_J1939_73_SpecVersion" STRING ;
BA_DEF_  "SAE_J1939_71_SpecVersion" STRING ;
BA_DEF_ SG_  "SystemSignalLongSymbol" STRING ;
BA_DEF_DEF_  "SigType" "Default";
BA_DEF_DEF_  "GenSigStartValue" 0;
BA_DEF_DEF_  "GenSigSendType" "NoSigSendType";
BA_DEF_DEF_  "GenSigILSupport" "Yes";
BA_DEF_DEF_  "GenSigEVName" "Env@Nodename_@Signame";
BA_DEF_DEF_  "SPN" 0;
BA_DEF_DEF_  "SAE_J1939_DA_SpecVersion" "";
BA_DEF_DEF_  "GenMsgStartDelayTime" 0;
BA_DEF_DEF_  "GenMsgILSupport" "Yes";
BA_DEF_DEF_  "GenMsgRequestable" 1;
BA_DEF_DEF_  "GenMsgSendType" "noMsgSendType";
BA_DEF_DEF_  "VFrameFormat" "J1939PG";
BA_DEF_DEF_  "GenMsgCycleTime" 0;
BA_DEF_DEF_  "NmStationAddress" 254;
BA_DEF_DEF_  "NmJ1939IndustryGroup" 0;
BA_DEF_DEF_  "NmJ1939System" 0;
BA_DEF_DEF_  "NmJ1939Function" 0;
BA_DEF_DEF_  "NmJ1939FunctionInstance" 0;
BA_DEF_DEF_  "NmJ1939ECUInstance" 0;
BA_DEF_DEF_  "SAE_J1939_81_SpecVersion" "";
BA_DEF_DEF_  "DatabaseVersion" "";
BA_DEF_DEF_  "BusType" "";
BA_DEF_DEF_  "ProtocolType" "";
BA_DEF_DEF_  "SAE_J1939_75_SpecVersion" "";
BA_DEF_DEF_  "SAE_J1939_21_SpecVersion" "";
BA_DEF_DEF_  "SAE_J1939_73_SpecVersion" "";
BA_DEF_DEF_  "SAE_J1939_71_SpecVersion" "";
BA_DEF_DEF_  "SystemSignalLongSymbol" "";
BA_ "SAE_J1939_DA_SpecVersion" "2014-03";
BA_ "SAE_J1939_81_SpecVersion" "2012-05";
BA_ "DatabaseVersion" "8.1";
BA_ "BusType" "CAN";
BA_ "ProtocolType" "J1939";
BA_ "SAE_J1939_75_SpecVersion" "2012-05";
BA_ "SAE_J1939_21_SpecVersion" "2006-10";
BA_ "SAE_J1939_73_SpecVersion" "2012-10";
BA_ "SAE_J1939_71_SpecVersion" "2012-10";
BA_ "NmStationAddress" BU_ PowertrainControlModule 90;
BA_ "NmStationAddress" BU_ AtmosphericSensor 89;
BA_ "NmJ1939Function" BU_ AtmosphericSensor 76;
BA_ "NmStationAddress" BU_ SafetyRestraintSystem2 88;
BA_ "NmJ1939Function" BU_ SafetyRestraintSystem2 132;
BA_ "NmJ1939FunctionInstance" BU_ SafetyRestraintSystem2 1;
BA_ "NmStationAddress" BU_ Aftertreatment_2_GasOutlet 87;
BA_ "NmJ1939Function" BU_ Aftertreatment_2_GasOutlet 68;
BA_ "NmJ1939FunctionInstance" BU_ Aftertreatment_2_GasOutlet 1;
BA_ "NmJ1939ECUInstance" BU_ Aftertreatment_2_GasOutlet 1;
BA_ "NmStationAddress" BU_ Aftertreatment_2_GasIntake 86;
BA_ "NmJ1939Function" BU_ Aftertreatment_2_GasIntake 68;
BA_ "NmJ1939FunctionInstance" BU_ Aftertreatment_2_GasIntake 1;
BA_ "NmStationAddress" BU_ DieselParticulateFilterControl 85;
BA_ "NmJ1939Function" BU_ DieselParticulateFilterControl 69;
BA_ "NmStationAddress" BU_ Turbocharger 2;
BA_ "NmJ1939Function" BU_ Turbocharger 133;
BA_ "NmStationAddress" BU_ SafetyRestraintSystem1 83;
BA_ "NmJ1939Function" BU_ SafetyRestraintSystem1 132;
BA_ "NmStationAddress" BU_ CabDisplay2 84;
BA_ "NmJ1939Function" BU_ CabDisplay2 60;
BA_ "NmJ1939FunctionInstance" BU_ CabDisplay2 1;
BA_ "NmStationAddress" BU_ Aftertreatment_1_GasOutlet 82;
BA_ "NmJ1939Function" BU_ Aftertreatment_1_GasOutlet 68;
BA_ "NmJ1939ECUInstance" BU_ Aftertreatment_1_GasOutlet 1;
BA_ "NmStationAddress" BU_ Aftertreatment_1_GasIntake 81;
BA_ "NmJ1939Function" BU_ Aftertreatment_1_GasIntake 68;
BA_ "NmStationAddress" BU_ OnBoardDataLogger 251;
BA_ "NmJ1939Function" BU_ OnBoardDataLogger 130;
BA_ "NmStationAddress" BU_ OffBoardDiagnosticTool2 250;
BA_ "NmJ1939Function" BU_ OffBoardDiagnosticTool2 129;
BA_ "NmJ1939FunctionInstance" BU_ OffBoardDiagnosticTool2 1;
BA_ "NmStationAddress" BU_ OffBoardDiagnosticTool1 249;
BA_ "NmJ1939Function" BU_ OffBoardDiagnosticTool1 129;
BA_ "NmStationAddress" BU_ FileServer 248;
BA_ "NmJ1939Function" BU_ FileServer 61;
BA_ "NmStationAddress" BU_ ParkingBrakeController 80;
BA_ "NmJ1939Function" BU_ ParkingBrakeController 9;
BA_ "NmJ1939FunctionInstance" BU_ ParkingBrakeController 1;
BA_ "NmStationAddress" BU_ SeatController2 79;
BA_ "NmJ1939Function" BU_ SeatController2 40;
BA_ "NmJ1939FunctionInstance" BU_ SeatController2 1;
BA_ "NmStationAddress" BU_ FanDriveController 78;
BA_ "NmJ1939Function" BU_ FanDriveController 58;
BA_ "NmStationAddress" BU_ SteeringColumnUnit 77;
BA_ "NmJ1939Function" BU_ SteeringColumnUnit 57;
BA_ "NmStationAddress" BU_ CommunicationUnitRadio 76;
BA_ "NmJ1939Function" BU_ CommunicationUnitRadio 56;
BA_ "NmStationAddress" BU_ CommunicationUnitSatellite 75;
BA_ "NmJ1939Function" BU_ CommunicationUnitSatellite 55;
BA_ "NmStationAddress" BU_ CommunicationUnitCellular 74;
BA_ "NmJ1939Function" BU_ CommunicationUnitCellular 54;
BA_ "NmStationAddress" BU_ PropulsionBatteryCharger 73;
BA_ "NmJ1939Function" BU_ PropulsionBatteryCharger 31;
BA_ "NmStationAddress" BU_ ChassisController2 72;
BA_ "NmJ1939Function" BU_ ChassisController2 52;
BA_ "NmJ1939FunctionInstance" BU_ ChassisController2 1;
BA_ "NmStationAddress" BU_ ChassisController1 71;
BA_ "NmJ1939Function" BU_ ChassisController1 52;
BA_ "NmStationAddress" BU_ EngineValveControl 70;
BA_ "NmJ1939Function" BU_ EngineValveControl 63;
BA_ "NmStationAddress" BU_ AuxiliaryHeater2 69;
BA_ "NmJ1939Function" BU_ AuxiliaryHeater2 50;
BA_ "NmJ1939FunctionInstance" BU_ AuxiliaryHeater2 1;
BA_ "NmStationAddress" BU_ AuxiliaryHeater1 68;
BA_ "NmJ1939Function" BU_ AuxiliaryHeater1 50;
BA_ "NmStationAddress" BU_ ClutchUnit 67;
BA_ "NmJ1939Function" BU_ ClutchUnit 49;
BA_ "NmStationAddress" BU_ RampControl 66;
BA_ "NmJ1939Function" BU_ RampControl 48;
BA_ "NmStationAddress" BU_ InformationSystem1 65;
BA_ "NmJ1939Function" BU_ InformationSystem1 47;
BA_ "NmStationAddress" BU_ SuspensionSystemController2 64;
BA_ "NmJ1939Function" BU_ SuspensionSystemController2 35;
BA_ "NmJ1939FunctionInstance" BU_ SuspensionSystemController2 1;
BA_ "NmStationAddress" BU_ OilSensor 63;
BA_ "NmJ1939Function" BU_ OilSensor 46;
BA_ "NmStationAddress" BU_ VehicleDynamicStability 62;
BA_ "NmJ1939Function" BU_ VehicleDynamicStability 45;
BA_ "NmStationAddress" BU_ ExhaustEmissionController 61;
BA_ "NmJ1939Function" BU_ ExhaustEmissionController 44;
BA_ "NmStationAddress" BU_ TransmissionDisplay2 60;
BA_ "NmJ1939Function" BU_ TransmissionDisplay2 43;
BA_ "NmJ1939FunctionInstance" BU_ TransmissionDisplay2 1;
BA_ "NmStationAddress" BU_ TransmissionDisplay1 59;
BA_ "NmJ1939Function" BU_ TransmissionDisplay1 43;
BA_ "NmStationAddress" BU_ ClimateControl2 58;
BA_ "NmJ1939Function" BU_ ClimateControl2 21;
BA_ "NmJ1939FunctionInstance" BU_ ClimateControl2 1;
BA_ "NmStationAddress" BU_ WaterPumpController 57;
BA_ "NmJ1939Function" BU_ WaterPumpController 42;
BA_ "NmStationAddress" BU_ RearAxleSteeringController 56;
BA_ "NmJ1939Function" BU_ RearAxleSteeringController 16;
BA_ "NmJ1939FunctionInstance" BU_ RearAxleSteeringController 1;
BA_ "NmStationAddress" BU_ LightingOperatorControl 55;
BA_ "NmJ1939Function" BU_ LightingOperatorControl 41;
BA_ "NmStationAddress" BU_ SeatController1 54;
BA_ "NmJ1939Function" BU_ SeatController1 40;
BA_ "NmStationAddress" BU_ IgnitionController2 53;
BA_ "NmJ1939Function" BU_ IgnitionController2 39;
BA_ "NmJ1939FunctionInstance" BU_ IgnitionController2 1;
BA_ "NmStationAddress" BU_ IgnitionController1 52;
BA_ "NmJ1939Function" BU_ IgnitionController1 39;
BA_ "NmStationAddress" BU_ TirePressureController 51;
BA_ "NmJ1939Function" BU_ TirePressureController 38;
BA_ "NmStationAddress" BU_ CabController2 50;
BA_ "NmJ1939Function" BU_ CabController2 37;
BA_ "NmJ1939FunctionInstance" BU_ CabController2 1;
BA_ "NmStationAddress" BU_ CabController1 49;
BA_ "NmJ1939Function" BU_ CabController1 37;
BA_ "NmStationAddress" BU_ PneumaticSystemController 48;
BA_ "NmJ1939Function" BU_ PneumaticSystemController 36;
BA_ "NmStationAddress" BU_ SuspensionSystemController1 47;
BA_ "NmJ1939Function" BU_ SuspensionSystemController1 35;
BA_ "NmStationAddress" BU_ HydraulicPumpController 46;
BA_ "NmJ1939Function" BU_ HydraulicPumpController 34;
BA_ "NmStationAddress" BU_ EnduranceBrakingSystem 45;
BA_ "NmJ1939Function" BU_ EnduranceBrakingSystem 64;
BA_ "NmStationAddress" BU_ RetarderExhaustEngine2 44;
BA_ "NmJ1939Function" BU_ RetarderExhaustEngine2 12;
BA_ "NmJ1939FunctionInstance" BU_ RetarderExhaustEngine2 1;
BA_ "NmStationAddress" BU_ OnBoardDiagnosticUnit 43;
BA_ "NmJ1939Function" BU_ OnBoardDiagnosticUnit 62;
BA_ "NmStationAddress" BU_ HeadwayController 42;
BA_ "NmJ1939Function" BU_ HeadwayController 32;
BA_ "NmStationAddress" BU_ RetarderExhaustEngine1 41;
BA_ "NmJ1939Function" BU_ RetarderExhaustEngine1 12;
BA_ "NmStationAddress" BU_ CabDisplay1 40;
BA_ "NmJ1939Function" BU_ CabDisplay1 60;
BA_ "NmStationAddress" BU_ ManagementComputer 39;
BA_ "NmJ1939Function" BU_ ManagementComputer 30;
BA_ "NmStationAddress" BU_ VirtualTerminal 38;
BA_ "NmJ1939Function" BU_ VirtualTerminal 29;
BA_ "NmStationAddress" BU_ OffVehicleGateway 37;
BA_ "NmJ1939Function" BU_ OffVehicleGateway 28;
BA_ "NmStationAddress" BU_ PowerTakeOffFront 36;
BA_ "NmJ1939Function" BU_ PowerTakeOffFront 27;
BA_ "NmStationAddress" BU_ HitchControl 35;
BA_ "NmStationAddress" BU_ AuxiliaryValveControl 34;
BA_ "NmJ1939IndustryGroup" BU_ AuxiliaryValveControl 2;
BA_ "NmJ1939System" BU_ AuxiliaryValveControl 1;
BA_ "NmJ1939Function" BU_ AuxiliaryValveControl 129;
BA_ "NmStationAddress" BU_ BodyController 33;
BA_ "NmJ1939Function" BU_ BodyController 26;
BA_ "NmStationAddress" BU_ TractorTrailerBridge1 32;
BA_ "NmJ1939Function" BU_ TractorTrailerBridge1 25;
BA_ "NmStationAddress" BU_ StarterSystem 31;
BA_ "NmJ1939Function" BU_ StarterSystem 59;
BA_ "NmStationAddress" BU_ ElectricalSystem 30;
BA_ "NmJ1939Function" BU_ ElectricalSystem 67;
BA_ "NmStationAddress" BU_ VehicleSecurity 29;
BA_ "NmJ1939Function" BU_ VehicleSecurity 24;
BA_ "NmStationAddress" BU_ VehicleNavigation 28;
BA_ "NmJ1939Function" BU_ VehicleNavigation 23;
BA_ "NmStationAddress" BU_ AerodynamicControl 27;
BA_ "NmJ1939Function" BU_ AerodynamicControl 22;
BA_ "NmStationAddress" BU_ ElectricalChargingSystem 26;
BA_ "NmJ1939Function" BU_ ElectricalChargingSystem 53;
BA_ "NmStationAddress" BU_ ClimateControl1 25;
BA_ "NmJ1939Function" BU_ ClimateControl1 21;
BA_ "NmStationAddress" BU_ TripRecorder 24;
BA_ "NmJ1939Function" BU_ TripRecorder 20;
BA_ "NmStationAddress" BU_ InstrumentCluster 23;
BA_ "NmJ1939Function" BU_ InstrumentCluster 19;
BA_ "NmStationAddress" BU_ SuspensionDriveAxle2 22;
BA_ "NmJ1939Function" BU_ SuspensionDriveAxle2 18;
BA_ "NmJ1939FunctionInstance" BU_ SuspensionDriveAxle2 1;
BA_ "NmStationAddress" BU_ SuspensionDriveAxle1 21;
BA_ "NmJ1939Function" BU_ SuspensionDriveAxle1 18;
BA_ "NmStationAddress" BU_ SuspensionSteerAxle 20;
BA_ "NmJ1939Function" BU_ SuspensionSteerAxle 17;
BA_ "NmStationAddress" BU_ SteeringController 19;
BA_ "NmJ1939Function" BU_ SteeringController 16;
BA_ "NmStationAddress" BU_ FuelSystem 18;
BA_ "NmJ1939Function" BU_ FuelSystem 15;
BA_ "NmStationAddress" BU_ CruiseControl 17;
BA_ "NmJ1939Function" BU_ CruiseControl 14;
BA_ "NmStationAddress" BU_ RetarderDriveline 16;
BA_ "NmJ1939Function" BU_ RetarderDriveline 13;
BA_ "NmStationAddress" BU_ RetarderEngine 15;
BA_ "NmJ1939Function" BU_ RetarderEngine 12;
BA_ "NmStationAddress" BU_ BrakesDriveAxle2 14;
BA_ "NmJ1939Function" BU_ BrakesDriveAxle2 11;
BA_ "NmJ1939FunctionInstance" BU_ BrakesDriveAxle2 1;
BA_ "NmStationAddress" BU_ BrakesDriveAxle1 13;
BA_ "NmJ1939Function" BU_ BrakesDriveAxle1 11;
BA_ "NmStationAddress" BU_ BrakesSystemController 11;
BA_ "NmJ1939Function" BU_ BrakesSystemController 9;
BA_ "NmStationAddress" BU_ BrakesSteerAxle 12;
BA_ "NmJ1939Function" BU_ BrakesSteerAxle 10;
BA_ "NmStationAddress" BU_ AxleDrive2 10;
BA_ "NmJ1939Function" BU_ AxleDrive2 8;
BA_ "NmJ1939FunctionInstance" BU_ AxleDrive2 1;
BA_ "NmStationAddress" BU_ AxleDrive1 9;
BA_ "NmJ1939Function" BU_ AxleDrive1 8;
BA_ "NmStationAddress" BU_ AxleSteering 8;
BA_ "NmJ1939Function" BU_ AxleSteering 7;
BA_ "NmStationAddress" BU_ PowerTakeOff 7;
BA_ "NmJ1939Function" BU_ PowerTakeOff 6;
BA_ "NmStationAddress" BU_ ShiftConsoleSecondary 6;
BA_ "NmJ1939Function" BU_ ShiftConsoleSecondary 5;
BA_ "NmJ1939FunctionInstance" BU_ ShiftConsoleSecondary 1;
BA_ "NmStationAddress" BU_ ShiftConsolePrimary 5;
BA_ "NmJ1939Function" BU_ ShiftConsolePrimary 5;
BA_ "NmStationAddress" BU_ Transmission2 4;
BA_ "NmJ1939Function" BU_ Transmission2 3;
BA_ "NmJ1939FunctionInstance" BU_ Transmission2 1;
BA_ "NmStationAddress" BU_ Transmission1 3;
BA_ "NmJ1939Function" BU_ Transmission1 3;
BA_ "NmStationAddress" BU_ Engine2 1;
BA_ "NmJ1939FunctionInstance" BU_ Engine2 1;
BA_ "NmStationAddress" BU_ Engine1 0;
BA_ "GenMsgSendType" BO_ 2566754814 0;
BA_ "GenMsgCycleTime" BO_ 2566754814 250;
BA_ "GenMsgSendType" BO_ 2566754302 0;
BA_ "GenMsgCycleTime" BO_ 2566754302 250;
BA_ "GenMsgSendType" BO_ 2566754046 0;
BA_ "GenMsgCycleTime" BO_ 2566754046 250;
BA_ "GenMsgSendType" BO_ 2566753790 0;
BA_ "GenMsgCycleTime" BO_ 2566753790 250;
BA_ "GenMsgSendType" BO_ 2566701566 0;
BA_ "GenMsgCycleTime" BO_ 2566701566 1000;
BA_ "GenMsgSendType" BO_ 2499592446 0;
BA_ "GenMsgCycleTime" BO_ 2499592446 100;
BA_ "GenMsgSendType" BO_ 2499592190 0;
BA_ "GenMsgCycleTime" BO_ 2499592190 100;
BA_ "GenMsgSendType" BO_ 2365374206 0;
BA_ "GenMsgCycleTime" BO_ 2365374206 20;
BA_ "GenMsgSendType" BO_ 2566700030 0;
BA_ "GenMsgCycleTime" BO_ 2566700030 1000;
BA_ "GenMsgSendType" BO_ 2566699774 0;
BA_ "GenMsgCycleTime" BO_ 2566699774 1000;
BA_ "GenMsgSendType" BO_ 2566698494 0;
BA_ "GenMsgCycleTime" BO_ 2566698494 1000;
BA_ "GenMsgSendType" BO_ 2566707454 0;
BA_ "GenMsgCycleTime" BO_ 2566707454 1000;
BA_ "GenMsgSendType" BO_ 2566707198 0;
BA_ "GenMsgCycleTime" BO_ 2566707198 1000;
BA_ "GenMsgSendType" BO_ 2566706942 0;
BA_ "GenMsgCycleTime" BO_ 2566706942 1000;
BA_ "GenMsgSendType" BO_ 2559770366 0;
BA_ "GenMsgCycleTime" BO_ 2559770366 100;
BA_ "GenMsgSendType" BO_ 2559639294 0;
BA_ "GenMsgCycleTime" BO_ 2559639294 1000;
BA_ "GenMsgSendType" BO_ 2559573758 0;
BA_ "GenMsgCycleTime" BO_ 2559573758 10000;
BA_ "GenMsgSendType" BO_ 2349530878 0;
BA_ "GenMsgCycleTime" BO_ 2349530878 100;
BA_ "GenMsgSendType" BO_ 2566698238 0;
BA_ "GenMsgCycleTime" BO_ 2566698238 1000;
BA_ "SigType" SG_ 2147483936 ABSOffroadRequest 4;
BA_ "SPN" SG_ 2381315838 ManufacturerSpecificInformation 3328;
BA_ "SigType" SG_ 2365475326 GroundBasedDirection 4;
BA_ "SPN" SG_ 2365475326 GroundBasedDirection 1861;
BA_ "SPN" SG_ 2365475326 GroundBasedImplementDistance 1860;
BA_ "SPN" SG_ 2365475326 GroundBasedImplementSpeed 1859;
BA_ "SigType" SG_ 2365475070 KeySwitchNOTOFF 4;
BA_ "SPN" SG_ 2365475070 KeySwitchNOTOFF 1865;
BA_ "SigType" SG_ 2365475070 WheelBasedDirection 4;
BA_ "SPN" SG_ 2365475070 WheelBasedDirection 1864;
BA_ "SPN" SG_ 2365475070 MaxTimeOfTractorPower 1866;
BA_ "SPN" SG_ 2365475070 WheelBasedDistance 1863;
BA_ "SPN" SG_ 2365475070 WheelBasedSpeed 1862;
BA_ "SigType" SG_ 2365474814 ImplementTransportState 4;
BA_ "SPN" SG_ 2365474814 ImplementTransportState 1869;
BA_ "SigType" SG_ 2365474814 ImplementParkState 4;
BA_ "SPN" SG_ 2365474814 ImplementParkState 1870;
BA_ "SigType" SG_ 2365474814 ImplementWorkState 4;
BA_ "SPN" SG_ 2365474814 ImplementWorkState 1871;
BA_ "SigType" SG_ 2365474814 MaintainECUPower 4;
BA_ "SPN" SG_ 2365474814 MaintainECUPower 1867;
BA_ "SigType" SG_ 2365474814 MaintainAcuatorPower 4;
BA_ "SPN" SG_ 2365474814 MaintainAcuatorPower 1868;
BA_ "SPN" SG_ 2365474558 FrontDraft 1878;
BA_ "SPN" SG_ 2365474558 FrontNominalLowerLinkForce 1880;
BA_ "SigType" SG_ 2365474558 FrontHitchInworkIndication 4;
BA_ "SPN" SG_ 2365474558 FrontHitchInworkIndication 1876;
BA_ "SPN" SG_ 2365474558 FrontHitchPos 1872;
BA_ "SPN" SG_ 2365474302 RearHitchExit_reasonCode 5819;
BA_ "SPN" SG_ 2365474302 RearDraft 1879;
BA_ "SPN" SG_ 2365474302 RearNominalLowerLinkForce 1881;
BA_ "SigType" SG_ 2365474302 RearHitchInworkIndication 4;
BA_ "SPN" SG_ 2365474302 RearHitchInworkIndication 1877;
BA_ "SPN" SG_ 2365474302 RearHitchPos 1873;
BA_ "SPN" SG_ 2365474046 FrontPTOExit_reasonCode 5817;
BA_ "SPN" SG_ 2365474046 FrontHitchExit_reasonCode 5816;
BA_ "SigType" SG_ 2365474046 FrontPowerTakeOffEngagement 4;
BA_ "SPN" SG_ 2365474046 FrontPowerTakeOffEngagement 1888;
BA_ "SigType" SG_ 2365474046 FrontPowerTakeOffMode 4;
BA_ "SPN" SG_ 2365474046 FrontPowerTakeOffMode 1889;
BA_ "SigType" SG_ 2365474046 FrontPowerTakeOffEconomyMode 4;
BA_ "SPN" SG_ 2365474046 FrontPowerTakeOffEconomyMode 1891;
BA_ "SPN" SG_ 2365474046 FrontPTOOutputShaftSpeedSetPoint 1884;
BA_ "SPN" SG_ 2365474046 FrontPTOOutputShaftSpeed 1882;
BA_ "SPN" SG_ 2365473790 RearPTOExit_reasonCode 5820;
BA_ "SigType" SG_ 2365473790 RearPowerTakeOffEngagement 4;
BA_ "SPN" SG_ 2365473790 RearPowerTakeOffEngagement 2408;
BA_ "SigType" SG_ 2365473790 RearPowerTakeOffMode 4;
BA_ "SPN" SG_ 2365473790 RearPowerTakeOffMode 1890;
BA_ "SigType" SG_ 2365473790 RearPowerTakeOffEconomyMode 4;
BA_ "SPN" SG_ 2365473790 RearPowerTakeOffEconomyMode 1892;
BA_ "SPN" SG_ 2365473790 RearPTOOutputShaftSpeedSetPoint 1885;
BA_ "SPN" SG_ 2365473790 RearPTOOutputShaftSpeed 1883;
BA_ "SigType" SG_ 2365473534 FrontPowerTakeOffModeCmd 4;
BA_ "SPN" SG_ 2365473534 FrontPowerTakeOffModeCmd 1895;
BA_ "SigType" SG_ 2365473534 RearPowerTakeOffModeCmd 4;
BA_ "SPN" SG_ 2365473534 RearPowerTakeOffModeCmd 1896;
BA_ "SigType" SG_ 2365473534 FrontPowerTakeOffEconomyModeCmd 4;
BA_ "SPN" SG_ 2365473534 FrontPowerTakeOffEconomyModeCmd 1897;
BA_ "SigType" SG_ 2365473534 RearPowerTakeOffEconomyModeCmd 4;
BA_ "SPN" SG_ 2365473534 RearPowerTakeOffEconomyModeCmd 1898;
BA_ "SigType" SG_ 2365473534 FrontPowerTakeOffEngagementCmd 4;
BA_ "SPN" SG_ 2365473534 FrontPowerTakeOffEngagementCmd 1893;
BA_ "SigType" SG_ 2365473534 RearPowerTakeOffEngagementCmd 4;
BA_ "SPN" SG_ 2365473534 RearPowerTakeOffEngagementCmd 1894;
BA_ "SPN" SG_ 2365473534 RrPTOOutputShaftSpeedSetPointCmd 1887;
BA_ "SPN" SG_ 2365473534 FrntPTOOtptShaftSpeedSetPointCmd 1886;
BA_ "SPN" SG_ 2365473534 RearHitchPosCmd 1875;
BA_ "SPN" SG_ 2365473534 FrontHitchPosCmd 1874;
BA_ "SigType" SG_ 2365472766 AuxValve15FailSafeModeCmd 4;
BA_ "SPN" SG_ 2365472766 AuxValve15FailSafeModeCmd 2345;
BA_ "SPN" SG_ 2365472766 AuxValve15StateCmd 2344;
BA_ "SPN" SG_ 2365472766 AuxValve15PortFlowCmd 2343;
BA_ "SigType" SG_ 2365472510 AuxValve14FailSafeModeCmd 4;
BA_ "SPN" SG_ 2365472510 AuxValve14FailSafeModeCmd 2333;
BA_ "SPN" SG_ 2365472510 AuxValve14StateCmd 2332;
BA_ "SPN" SG_ 2365472510 AuxValve14PortFlowCmd 2331;
BA_ "SigType" SG_ 2365472254 AuxValve13FailSafeModeCmd 4;
BA_ "SPN" SG_ 2365472254 AuxValve13FailSafeModeCmd 2321;
BA_ "SPN" SG_ 2365472254 AuxValve13StateCmd 2320;
BA_ "SPN" SG_ 2365472254 AuxValve13PortFlowCmd 2319;
BA_ "SigType" SG_ 2365471998 AuxValve12FailSafeModeCmd 4;
BA_ "SPN" SG_ 2365471998 AuxValve12FailSafeModeCmd 2309;
BA_ "SPN" SG_ 2365471998 AuxValve12StateCmd 2308;
BA_ "SPN" SG_ 2365471998 AuxValve12PortFlowCmd 2307;
BA_ "SigType" SG_ 2365471742 AuxValve11FailSafeModeCmd 4;
BA_ "SPN" SG_ 2365471742 AuxValve11FailSafeModeCmd 2297;
BA_ "SPN" SG_ 2365471742 AuxValve11StateCmd 2296;
BA_ "SPN" SG_ 2365471742 AuxValve11PortFlowCmd 2295;
BA_ "SigType" SG_ 2365471486 AuxValve10FailSafeModeCmd 4;
BA_ "SPN" SG_ 2365471486 AuxValve10FailSafeModeCmd 2285;
BA_ "SPN" SG_ 2365471486 AuxValve10StateCmd 2284;
BA_ "SPN" SG_ 2365471486 AuxValve10PortFlowCmd 2283;
BA_ "SigType" SG_ 2365471230 AuxValve9FailSafeModeCmd 4;
BA_ "SPN" SG_ 2365471230 AuxValve9FailSafeModeCmd 2273;
BA_ "SPN" SG_ 2365471230 AuxValve9StateCmd 2272;
BA_ "SPN" SG_ 2365471230 AuxValve9PortFlowCmd 2271;
BA_ "SigType" SG_ 2365470974 AuxValve8FailSafeModeCmd 4;
BA_ "SPN" SG_ 2365470974 AuxValve8FailSafeModeCmd 2261;
BA_ "SPN" SG_ 2365470974 AuxValve8StateCmd 2260;
BA_ "SPN" SG_ 2365470974 AuxValve8PortFlowCmd 2259;
BA_ "SigType" SG_ 2365470718 AuxValve7FailSafeModeCmd 4;
BA_ "SPN" SG_ 2365470718 AuxValve7FailSafeModeCmd 1993;
BA_ "SPN" SG_ 2365470718 AuxValve7StateCmd 1992;
BA_ "SPN" SG_ 2365470718 AuxValve7PortFlowCmd 1991;
BA_ "SigType" SG_ 2365470462 AuxValve6FailSafeModeCmd 4;
BA_ "SPN" SG_ 2365470462 AuxValve6FailSafeModeCmd 1981;
BA_ "SPN" SG_ 2365470462 AuxValve6StateCmd 1980;
BA_ "SPN" SG_ 2365470462 AuxValve6PortFlowCmd 1979;
BA_ "SigType" SG_ 2365470206 AuxValve5FailSafeModeCmd 4;
BA_ "SPN" SG_ 2365470206 AuxValve5FailSafeModeCmd 1969;
BA_ "SPN" SG_ 2365470206 AuxValve5StateCmd 1968;
BA_ "SPN" SG_ 2365470206 AuxValve5PortFlowCmd 1967;
BA_ "SigType" SG_ 2365469950 AuxValve4FailSafeModeCmd 4;
BA_ "SPN" SG_ 2365469950 AuxValve4FailSafeModeCmd 1957;
BA_ "SPN" SG_ 2365469950 AuxValve4StateCmd 1956;
BA_ "SPN" SG_ 2365469950 AuxValve4PortFlowCmd 1955;
BA_ "SigType" SG_ 2365469694 AuxValve3FailSafeModeCmd 4;
BA_ "SPN" SG_ 2365469694 AuxValve3FailSafeModeCmd 1945;
BA_ "SPN" SG_ 2365469694 AuxValve3StateCmd 1944;
BA_ "SPN" SG_ 2365469694 AuxValve3PortFlowCmd 1943;
BA_ "SigType" SG_ 2365469438 AuxValve2FailSafeModeCmd 4;
BA_ "SPN" SG_ 2365469438 AuxValve2FailSafeModeCmd 1933;
BA_ "SPN" SG_ 2365469438 AuxValve2StateCmd 1932;
BA_ "SPN" SG_ 2365469438 AuxValve2PortFlowCmd 1931;
BA_ "SigType" SG_ 2365469182 AuxValve1FailSafeModeCmd 4;
BA_ "SPN" SG_ 2365469182 AuxValve1FailSafeModeCmd 1921;
BA_ "SPN" SG_ 2365469182 AuxValve1StateCmd 1920;
BA_ "SPN" SG_ 2365469182 AuxValve1PortFlowCmd 1919;
BA_ "SigType" SG_ 2365468926 AuxValve0FailSafeModeCmd 4;
BA_ "SPN" SG_ 2365468926 AuxValve0FailSafeModeCmd 1909;
BA_ "SPN" SG_ 2365468926 AuxValve0StateCmd 1908;
BA_ "SPN" SG_ 2365468926 AuxValve0PortFlowCmd 1907;
BA_ "SPN" SG_ 2365468670 AuxValve15ReturnPortPress 2342;
BA_ "SPN" SG_ 2365468670 AuxValve15RetractPortPress 2341;
BA_ "SPN" SG_ 2365468670 AuxValve15ExtendPortPress 2340;
BA_ "SPN" SG_ 2365468670 AxValve15RetractPortMeasuredFlow 2336;
BA_ "SPN" SG_ 2365468670 AuxValve15ExtendPortMeasuredFlow 2335;
BA_ "SPN" SG_ 2365468414 AuxValve14ReturnPortPress 2330;
BA_ "SPN" SG_ 2365468414 AuxValve14RetractPortPress 2329;
BA_ "SPN" SG_ 2365468414 AuxValve14ExtendPortPress 2328;
BA_ "SPN" SG_ 2365468414 AxValve14RetractPortMeasuredFlow 2324;
BA_ "SPN" SG_ 2365468414 AuxValve14ExtendPortMeasuredFlow 2323;
BA_ "SPN" SG_ 2365468158 AuxValve13ReturnPortPress 2318;
BA_ "SPN" SG_ 2365468158 AuxValve13RetractPortPress 2317;
BA_ "SPN" SG_ 2365468158 AuxValve13ExtendPortPress 2316;
BA_ "SPN" SG_ 2365468158 AxValve13RetractPortMeasuredFlow 2312;
BA_ "SPN" SG_ 2365468158 AuxValve13ExtendPortMeasuredFlow 2311;
BA_ "SPN" SG_ 2365467902 AuxValve12ReturnPortPress 2306;
BA_ "SPN" SG_ 2365467902 AuxValve12RetractPortPress 2305;
BA_ "SPN" SG_ 2365467902 AuxValve12ExtendPortPress 2304;
BA_ "SPN" SG_ 2365467902 AxValve12RetractPortMeasuredFlow 2300;
BA_ "SPN" SG_ 2365467902 AuxValve12ExtendPortMeasuredFlow 2299;
BA_ "SPN" SG_ 2365467646 AuxValve11ReturnPortPress 2294;
BA_ "SPN" SG_ 2365467646 AuxValve11RetractPortPress 2293;
BA_ "SPN" SG_ 2365467646 AuxValve11ExtendPortPress 2292;
BA_ "SPN" SG_ 2365467646 AxValve11RetractPortMeasuredFlow 2288;
BA_ "SPN" SG_ 2365467646 AuxValve11ExtendPortMeasuredFlow 2287;
BA_ "SPN" SG_ 2365467390 AuxValve10ReturnPortPress 2282;
BA_ "SPN" SG_ 2365467390 AuxValve10RetractPortPress 2281;
BA_ "SPN" SG_ 2365467390 AuxValve10ExtendPortPress 2280;
BA_ "SPN" SG_ 2365467390 AxValve10RetractPortMeasuredFlow 2276;
BA_ "SPN" SG_ 2365467390 AuxValve10ExtendPortMeasuredFlow 2275;
BA_ "SPN" SG_ 2365467134 AuxValve9ReturnPortPress 2270;
BA_ "SPN" SG_ 2365467134 AuxValve9RetractPortPress 2269;
BA_ "SPN" SG_ 2365467134 AuxValve9ExtendPortPress 2268;
BA_ "SPN" SG_ 2365467134 AuxValve9RetractPortMeasuredFlow 2264;
BA_ "SPN" SG_ 2365467134 AuxValve9ExtendPortMeasuredFlow 2263;
BA_ "SPN" SG_ 2365466878 AuxValve8ReturnPortPress 2258;
BA_ "SPN" SG_ 2365466878 AuxValve8RetractPortPress 2257;
BA_ "SPN" SG_ 2365466878 AuxValve8ExtendPortPress 2256;
BA_ "SPN" SG_ 2365466878 AuxValve8RetractPortMeasuredFlow 1996;
BA_ "SPN" SG_ 2365466878 AuxValve8ExtendPortMeasuredFlow 1995;
BA_ "SPN" SG_ 2365466622 AuxValve7ReturnPortPress 1990;
BA_ "SPN" SG_ 2365466622 AuxValve7RetractPortPress 1989;
BA_ "SPN" SG_ 2365466622 AuxValve7ExtendPortPress 1988;
BA_ "SPN" SG_ 2365466622 AuxValve7RetractPortMeasuredFlow 1984;
BA_ "SPN" SG_ 2365466622 AuxValve7ExtendPortMeasuredFlow 1983;
BA_ "SPN" SG_ 2365466366 AuxValve6ReturnPortPress 1978;
BA_ "SPN" SG_ 2365466366 AuxValve6RetractPortPress 1977;
BA_ "SPN" SG_ 2365466366 AuxValve6ExtendPortPress 1976;
BA_ "SPN" SG_ 2365466366 AuxValve6RetractPortMeasuredFlow 1972;
BA_ "SPN" SG_ 2365466366 AuxValve6ExtendPortMeasuredFlow 1971;
BA_ "SPN" SG_ 2365466110 AuxValve5ReturnPortPress 1966;
BA_ "SPN" SG_ 2365466110 AuxValve5RetractPortPress 1965;
BA_ "SPN" SG_ 2365466110 AuxValve5ExtendPortPress 1964;
BA_ "SPN" SG_ 2365466110 AuxValve5RetractPortMeasuredFlow 1960;
BA_ "SPN" SG_ 2365466110 AuxValve5ExtendPortMeasuredFlow 1959;
BA_ "SPN" SG_ 2365465854 AuxValve4ReturnPortPress 1954;
BA_ "SPN" SG_ 2365465854 AuxValve4RetractPortPress 1953;
BA_ "SPN" SG_ 2365465854 AuxValve4ExtendPortPress 1952;
BA_ "SPN" SG_ 2365465854 AuxValve4RetractPortMeasuredFlow 1948;
BA_ "SPN" SG_ 2365465854 AuxValve4ExtendPortMeasuredFlow 1947;
BA_ "SPN" SG_ 2365465598 AuxValve3ReturnPortPress 1942;
BA_ "SPN" SG_ 2365465598 AuxValve3RetractPortPress 1941;
BA_ "SPN" SG_ 2365465598 AuxValve3ExtendPortPress 1940;
BA_ "SPN" SG_ 2365465598 AuxValve3RetractPortMeasuredFlow 1936;
BA_ "SPN" SG_ 2365465598 AuxValve3ExtendPortMeasuredFlow 1935;
BA_ "SPN" SG_ 2365465342 AuxValve2ReturnPortPress 1930;
BA_ "SPN" SG_ 2365465342 AuxValve2RetractPortPress 1929;
BA_ "SPN" SG_ 2365465342 AuxValve2ExtendPortPress 1928;
BA_ "SPN" SG_ 2365465342 AuxValve2RetractPortMeasuredFlow 1924;
BA_ "SPN" SG_ 2365465342 AuxValve2ExtendPortMeasuredFlow 1923;
BA_ "SPN" SG_ 2365465086 AuxValve1ReturnPortPress 1918;
BA_ "SPN" SG_ 2365465086 AuxValve1RetractPortPress 1917;
BA_ "SPN" SG_ 2365465086 AuxValve1ExtendPortPress 1916;
BA_ "SPN" SG_ 2365465086 AuxValve1RetractPortMeasuredFlow 1912;
BA_ "SPN" SG_ 2365465086 AuxValve1ExtendPortMeasuredFlow 1911;
BA_ "SPN" SG_ 2365464830 AuxValve0ReturnPortPress 1906;
BA_ "SPN" SG_ 2365464830 AuxValve0RetractPortPress 1905;
BA_ "SPN" SG_ 2365464830 AuxValve0ExtendPortPress 1904;
BA_ "SPN" SG_ 2365464830 AuxValve0RetractPortMeasuredFlow 1900;
BA_ "SPN" SG_ 2365464830 AuxValve0ExtendPortMeasuredFlow 1899;
BA_ "SPN" SG_ 2365464574 AuxValve15Exit_reasonCode 5815;
BA_ "SigType" SG_ 2365464574 AuxValve15FailSafeMode 4;
BA_ "SPN" SG_ 2365464574 AuxValve15FailSafeMode 2346;
BA_ "SPN" SG_ 2365464574 AuxValve15State 2339;
BA_ "SPN" SG_ 2365464574 AuxValve15RetractPortEstFlow 2338;
BA_ "SPN" SG_ 2365464574 AuxValve15ExtendPortEstFlow 2337;
BA_ "SPN" SG_ 2365464318 AuxValve14Exit_reasonCode 5814;
BA_ "SigType" SG_ 2365464318 AuxValve14FailSafeMode 4;
BA_ "SPN" SG_ 2365464318 AuxValve14FailSafeMode 2334;
BA_ "SPN" SG_ 2365464318 AuxValve14State 2327;
BA_ "SPN" SG_ 2365464318 AuxValve14RetractPortEstFlow 2326;
BA_ "SPN" SG_ 2365464318 AuxValve14ExtendPortEstFlow 2325;
BA_ "SPN" SG_ 2365464062 AuxValve13Exit_reasonCode 5813;
BA_ "SigType" SG_ 2365464062 AuxValve13FailSafeMode 4;
BA_ "SPN" SG_ 2365464062 AuxValve13FailSafeMode 2322;
BA_ "SPN" SG_ 2365464062 AuxValve13State 2315;
BA_ "SPN" SG_ 2365464062 AuxValve13RetractPortEstFlow 2314;
BA_ "SPN" SG_ 2365464062 AuxValve13ExtendPortEstFlow 2313;
BA_ "SPN" SG_ 2365463806 AuxValve12Exit_reasonCode 5812;
BA_ "SigType" SG_ 2365463806 AuxValve12FailSafeMode 4;
BA_ "SPN" SG_ 2365463806 AuxValve12FailSafeMode 2310;
BA_ "SPN" SG_ 2365463806 AuxValve12State 2303;
BA_ "SPN" SG_ 2365463806 AuxValve12RetractPortEstFlow 2302;
BA_ "SPN" SG_ 2365463806 AuxValve12ExtendPortEstFlow 2301;
BA_ "SPN" SG_ 2365463550 AuxValve11Exit_reasonCode 5811;
BA_ "SigType" SG_ 2365463550 AuxValve11FailSafeMode 4;
BA_ "SPN" SG_ 2365463550 AuxValve11FailSafeMode 2298;
BA_ "SPN" SG_ 2365463550 AuxValve11State 2291;
BA_ "SPN" SG_ 2365463550 AuxValve11RetractPortEstFlow 2290;
BA_ "SPN" SG_ 2365463550 AuxValve11ExtendPortEstFlow 2289;
BA_ "SPN" SG_ 2365463294 AuxValve10Exit_reasonCode 5810;
BA_ "SigType" SG_ 2365463294 AuxValve10FailSafeMode 4;
BA_ "SPN" SG_ 2365463294 AuxValve10FailSafeMode 2286;
BA_ "SPN" SG_ 2365463294 AuxValve10State 2279;
BA_ "SPN" SG_ 2365463294 AuxValve10RetractPortEstFlow 2278;
BA_ "SPN" SG_ 2365463294 AuxValve10ExtendPortEstFlow 2277;
BA_ "SPN" SG_ 2365463038 AuxValve9Exit_reasonCode 5809;
BA_ "SigType" SG_ 2365463038 AuxValve9FailSafeMode 4;
BA_ "SPN" SG_ 2365463038 AuxValve9FailSafeMode 2274;
BA_ "SPN" SG_ 2365463038 AuxValve9State 2267;
BA_ "SPN" SG_ 2365463038 AuxValve9RetractPortEstFlow 2266;
BA_ "SPN" SG_ 2365463038 AuxValve9ExtendPortEstFlow 2265;
BA_ "SPN" SG_ 2365462782 AuxValve8Exit_reasonCode 5808;
BA_ "SigType" SG_ 2365462782 AuxValve8FailSafeMode 4;
BA_ "SPN" SG_ 2365462782 AuxValve8FailSafeMode 2262;
BA_ "SPN" SG_ 2365462782 AuxValve8State 1999;
BA_ "SPN" SG_ 2365462782 AuxValve8RetractPortEstFlow 1998;
BA_ "SPN" SG_ 2365462782 AuxValve8ExtendPortEstFlow 1997;
BA_ "SPN" SG_ 2365462526 AuxValve7Exit_reasonCode 5807;
BA_ "SigType" SG_ 2365462526 AuxValve7FailSafeMode 4;
BA_ "SPN" SG_ 2365462526 AuxValve7FailSafeMode 1994;
BA_ "SPN" SG_ 2365462526 AuxValve7State 1987;
BA_ "SPN" SG_ 2365462526 AuxValve7RetractPortEstFlow 1986;
BA_ "SPN" SG_ 2365462526 AuxValve7ExtendPortEstFlow 1985;
BA_ "SPN" SG_ 2365462270 AuxValve6Exit_reasonCode 5806;
BA_ "SigType" SG_ 2365462270 AuxValve6FailSafeMode 4;
BA_ "SPN" SG_ 2365462270 AuxValve6FailSafeMode 1982;
BA_ "SPN" SG_ 2365462270 AuxValve6State 1975;
BA_ "SPN" SG_ 2365462270 AuxValve6RetractPortEstFlow 1974;
BA_ "SPN" SG_ 2365462270 AuxValve6ExtendPortEstFlow 1973;
BA_ "SPN" SG_ 2365462014 AuxValve5Exit_reasonCode 5805;
BA_ "SigType" SG_ 2365462014 AuxValve5FailSafeMode 4;
BA_ "SPN" SG_ 2365462014 AuxValve5FailSafeMode 1970;
BA_ "SPN" SG_ 2365462014 AuxValve5State 1963;
BA_ "SPN" SG_ 2365462014 AuxValve5RetractPortEstFlow 1962;
BA_ "SPN" SG_ 2365462014 AuxValve5ExtendPortEstFlow 1961;
BA_ "SPN" SG_ 2365461758 AuxValve4Exit_reasonCode 5804;
BA_ "SigType" SG_ 2365461758 AuxValve4FailSafeMode 4;
BA_ "SPN" SG_ 2365461758 AuxValve4FailSafeMode 1958;
BA_ "SPN" SG_ 2365461758 AuxValve4State 1951;
BA_ "SPN" SG_ 2365461758 AuxValve4RetractPortEstFlow 1950;
BA_ "SPN" SG_ 2365461758 AuxValve4ExtendPortEstFlow 1949;
BA_ "SPN" SG_ 2365461502 AuxValve3Exit_reasonCode 5803;
BA_ "SigType" SG_ 2365461502 AuxValve3FailSafeMode 4;
BA_ "SPN" SG_ 2365461502 AuxValve3FailSafeMode 1946;
BA_ "SPN" SG_ 2365461502 AuxValve3State 1939;
BA_ "SPN" SG_ 2365461502 AuxValve3RetractPortEstFlow 1938;
BA_ "SPN" SG_ 2365461502 AuxValve3ExtendPortEstFlow 1937;
BA_ "SPN" SG_ 2365461246 AuxValve2Exit_reasonCode 5802;
BA_ "SigType" SG_ 2365461246 AuxValve2FailSafeMode 4;
BA_ "SPN" SG_ 2365461246 AuxValve2FailSafeMode 1934;
BA_ "SPN" SG_ 2365461246 AuxValve2State 1927;
BA_ "SPN" SG_ 2365461246 AuxValve2RetractPortEstFlow 1926;
BA_ "SPN" SG_ 2365461246 AuxValve2ExtendPortEstFlow 1925;
BA_ "SPN" SG_ 2365460990 AuxValve1Exit_reasonCode 5801;
BA_ "SigType" SG_ 2365460990 AuxValve1FailSafeMode 4;
BA_ "SPN" SG_ 2365460990 AuxValve1FailSafeMode 1922;
BA_ "SPN" SG_ 2365460990 AuxValve1State 1915;
BA_ "SPN" SG_ 2365460990 AuxValve1RetractPortEstFlow 1914;
BA_ "SPN" SG_ 2365460990 AuxValve1ExtendPortEstFlow 1913;
BA_ "SPN" SG_ 2365460734 AuxValve0Exit_reasonCode 5800;
BA_ "SigType" SG_ 2365460734 AuxValve0FailSafeMode 4;
BA_ "SPN" SG_ 2365460734 AuxValve0FailSafeMode 1910;
BA_ "SPN" SG_ 2365460734 AuxValve0State 1903;
BA_ "SPN" SG_ 2365460734 AuxValve0RetractPortEstFlow 1902;
BA_ "SPN" SG_ 2365460734 AuxValve0ExtendPortEstFlow 1901;
BA_ "SigType" SG_ 2365460478 DistanceUnitCmd 4;
BA_ "SPN" SG_ 2365460478 DistanceUnitCmd 2414;
BA_ "SigType" SG_ 2365460478 AreaUnitCmd 4;
BA_ "SPN" SG_ 2365460478 AreaUnitCmd 2415;
BA_ "SigType" SG_ 2365460478 VolumeUnitCmd 4;
BA_ "SPN" SG_ 2365460478 VolumeUnitCmd 2416;
BA_ "SigType" SG_ 2365460478 MassUnitCmd 4;
BA_ "SPN" SG_ 2365460478 MassUnitCmd 2417;
BA_ "SPN" SG_ 2365460478 DateCmd 2412;
BA_ "SigType" SG_ 2365460478 DecimalSymbolCmd 4;
BA_ "SPN" SG_ 2365460478 DecimalSymbolCmd 2411;
BA_ "SigType" SG_ 2365460478 TimeCmd 4;
BA_ "SPN" SG_ 2365460478 TimeCmd 2413;
BA_ "SPN" SG_ 2365460478 LanguageCodeCmd 2410;
BA_ "SPN" SG_ 2365460222 DataDictionaryRow 2427;
BA_ "SPN" SG_ 2365460222 DataDictionaryColumn 2428;
BA_ "SPN" SG_ 2365460222 ImplementType 2425;
BA_ "SPN" SG_ 2365460222 ImplementPos 2426;
BA_ "SigType" SG_ 2365460222 DataFormat_ErrorCondition 4;
BA_ "SPN" SG_ 2365460222 DataFormat_ErrorCondition 2419;
BA_ "SigType" SG_ 2365460222 ProcessDataType 4;
BA_ "SPN" SG_ 2365460222 ProcessDataType 2420;
BA_ "SPN" SG_ 2365460222 ProcessDataModifier 2421;
BA_ "SPN" SG_ 2365460222 RepetitionRateParameter 2418;
BA_ "SigType" SG_ 2365444094 NumberOfMembers 3;
BA_ "SPN" SG_ 2365443838 NAMEOfWorkingSetMember 2845;
BA_ "SPN" SG_ 2365434878 PGNOfConfigurableMessageDesired 3330;
BA_ "SigType" SG_ 2365434878 MessageSelectionCtrl 1;
BA_ "SPN" SG_ 2365434878 MessageSelectionCtrl 3329;
BA_ "SPN" SG_ 2566754814 AutomaticTransferSwitchStatus 3547;
BA_ "SPN" SG_ 2566754814 UtilityCircuitBreakerStatus 3546;
BA_ "SPN" SG_ 2566754814 GeneratorCircuitBreakerStatus 3545;
BA_ "SigType" SG_ 2566754302 GeneratorTotalPercentKVAr 1;
BA_ "SPN" SG_ 2566754302 GeneratorTotalPercentKVAr 3592;
BA_ "SigType" SG_ 2566754302 GeneratorTotalPercentKVA 1;
BA_ "SPN" SG_ 2566754302 GeneratorTotalPercentKVA 3591;
BA_ "SigType" SG_ 2566754302 GeneratorTotalPercentKW 1;
BA_ "SPN" SG_ 2566754302 GeneratorTotalPercentKW 3590;
BA_ "SigType" SG_ 2566754046 GeneratorTotalKVArHoursImport 1;
BA_ "SPN" SG_ 2566754046 GeneratorTotalKVArHoursImport 3594;
BA_ "SigType" SG_ 2566754046 GeneratorTotalKVArHoursExport 1;
BA_ "SPN" SG_ 2566754046 GeneratorTotalKVArHoursExport 3593;
BA_ "SigType" SG_ 2566753790 UtilityTotalKVArHoursImport 1;
BA_ "SPN" SG_ 2566753790 UtilityTotalKVArHoursImport 3596;
BA_ "SigType" SG_ 2566753790 UtilityTotalKVArHoursExport 1;
BA_ "SPN" SG_ 2566753790 UtilityTotalKVArHoursExport 3595;
BA_ "SigType" SG_ 2365408254 MachineSelectedDirectionCmd 4;
BA_ "SPN" SG_ 2365408254 MachineSelectedDirectionCmd 4312;
BA_ "SPN" SG_ 2365408254 MchnSelectedSpeedExit_reasonCode 5818;
BA_ "SPN" SG_ 2365408254 MchineSelectedSpeedSetpointLimit 4311;
BA_ "SPN" SG_ 2365408254 MachineSelectedSpeedSetpointCmd 4310;
BA_ "SPN" SG_ 2365407998 ISOBUSCmplncCrtfctnRfrenceNumber 4330;
BA_ "SPN" SG_ 2365407998 ISOBUSCmplncCrtfctonTypeTaskCtrl 4325;
BA_ "SPN" SG_ 2365407998 ISOBUSCmplncCrtfctnTypTCWrkn4326 4326;
BA_ "SPN" SG_ 2365407998 ISOBUSCmplncCrtfctnTypTCWrkngStM 4327;
BA_ "SPN" SG_ 2365407998 ISOBUSCmplncCrtfctnTypFileServer 4328;
BA_ "SPN" SG_ 2365407998 ISOBUSCmplncCrtfctnTypGPSRceiver 4329;
BA_ "SPN" SG_ 2365407998 ISOBUSCmplncCrtfcationTypeMinECU 4317;
BA_ "SPN" SG_ 2365407998 ISOBUSCmplncCrtfctnTypTECUClass1 4318;
BA_ "SPN" SG_ 2365407998 ISOBUSCmplncCrtfctnTypTECUClass2 4319;
BA_ "SPN" SG_ 2365407998 ISOBUSCmplncCrtfctnTypTECUClass3 4320;
BA_ "SPN" SG_ 2365407998 ISOBUSCmplncCrtfctnTypeClass3ECU 4321;
BA_ "SPN" SG_ 2365407998 ISOBUSCmplncCrtfctnTypVrtlTrmnal 4322;
BA_ "SPN" SG_ 2365407998 ISOBUSCmplncCrtfctnTypVTWrkn4323 4323;
BA_ "SPN" SG_ 2365407998 ISOBUSCmplncCrtfctnTypVTWrkngStM 4324;
BA_ "SPN" SG_ 2365407998 ISOBUSCmplncCrtfctonLaboratoryID 4316;
BA_ "SPN" SG_ 2365407998 ISOBUSCmplncCrtfctLaboratoryType 4315;
BA_ "SPN" SG_ 2365407998 ISOBUSCmplnceCertificateRevision 4314;
BA_ "SPN" SG_ 2365407998 ISOBUSCmplianceCertificationYear 4313;
BA_ "SigType" SG_ 2365391870 ImplementOperatingStateCmd 4;
BA_ "SPN" SG_ 2365391870 ImplementOperatingStateCmd 5139;
BA_ "SigType" SG_ 2365391614 AllImplmntStpOprtngOprtnsSwtchSt 4;
BA_ "SPN" SG_ 2365391614 AllImplmntStpOprtngOprtnsSwtchSt 5140;
BA_ "SigType" SG_ 2566701566 TransOilTransCoolerOutletTemp 1;
BA_ "SPN" SG_ 2566701566 TransOilTransCoolerOutletTemp 5938;
BA_ "SigType" SG_ 2566701566 TransClutch2Press 1;
BA_ "SPN" SG_ 2566701566 TransClutch2Press 5937;
BA_ "SigType" SG_ 2499592446 TransShiftRail6Pos 1;
BA_ "SPN" SG_ 2499592446 TransShiftRail6Pos 5943;
BA_ "SigType" SG_ 2499592446 TransShiftRail5Pos 1;
BA_ "SPN" SG_ 2499592446 TransShiftRail5Pos 5942;
BA_ "SigType" SG_ 2499592446 TransShiftRail4Pos 1;
BA_ "SPN" SG_ 2499592446 TransShiftRail4Pos 5941;
BA_ "SigType" SG_ 2499592446 TransShiftRail3Pos 1;
BA_ "SPN" SG_ 2499592446 TransShiftRail3Pos 4220;
BA_ "SigType" SG_ 2499592446 TransShiftRail2Pos 1;
BA_ "SPN" SG_ 2499592446 TransShiftRail2Pos 4219;
BA_ "SigType" SG_ 2499592446 TransShiftRail1Pos 1;
BA_ "SPN" SG_ 2499592446 TransShiftRail1Pos 4218;
BA_ "SigType" SG_ 2499592190 TransHydPumpActuator2Percent 1;
BA_ "SPN" SG_ 2499592190 TransHydPumpActuator2Percent 6582;
BA_ "SigType" SG_ 2499592190 TransShiftRail6ActuatorStatus 5;
BA_ "SPN" SG_ 2499592190 TransShiftRail6ActuatorStatus 5956;
BA_ "SigType" SG_ 2499592190 TransShiftRail5ActuatorStatus 5;
BA_ "SPN" SG_ 2499592190 TransShiftRail5ActuatorStatus 5955;
BA_ "SigType" SG_ 2499592190 TransShiftRail4ActuatorStatus 5;
BA_ "SPN" SG_ 2499592190 TransShiftRail4ActuatorStatus 5954;
BA_ "SigType" SG_ 2499592190 TransShiftRail3ActuatorStatus 5;
BA_ "SPN" SG_ 2499592190 TransShiftRail3ActuatorStatus 5953;
BA_ "SigType" SG_ 2499592190 TransShiftRail2ActuatorStatus 5;
BA_ "SPN" SG_ 2499592190 TransShiftRail2ActuatorStatus 5952;
BA_ "SigType" SG_ 2499592190 TransShiftRail1ActuatorStatus 5;
BA_ "SPN" SG_ 2499592190 TransShiftRail1ActuatorStatus 5951;
BA_ "SigType" SG_ 2499592190 TrnsClutch2CoolingActuatorStatus 5;
BA_ "SPN" SG_ 2499592190 TrnsClutch2CoolingActuatorStatus 5950;
BA_ "SigType" SG_ 2499592190 TrnsClutch1CoolingActuatorStatus 5;
BA_ "SPN" SG_ 2499592190 TrnsClutch1CoolingActuatorStatus 5949;
BA_ "SigType" SG_ 2499592190 TransShiftActuator2Percent 1;
BA_ "SPN" SG_ 2499592190 TransShiftActuator2Percent 5948;
BA_ "SigType" SG_ 2499592190 TransShiftActuator1Percent 1;
BA_ "SPN" SG_ 2499592190 TransShiftActuator1Percent 5947;
BA_ "SigType" SG_ 2499592190 TransHydPumpActuator1Percent 1;
BA_ "SPN" SG_ 2499592190 TransHydPumpActuator1Percent 5946;
BA_ "SigType" SG_ 2499592190 TransClutch2ActuatorPercent 1;
BA_ "SPN" SG_ 2499592190 TransClutch2ActuatorPercent 5945;
BA_ "SigType" SG_ 2499592190 TransClutch1ActuatorPercent 1;
BA_ "SPN" SG_ 2499592190 TransClutch1ActuatorPercent 5944;
BA_ "SigType" SG_ 2365374206 DlCltchTrnsCrrntPreselectionGear 1;
BA_ "SPN" SG_ 2365374206 DlCltchTrnsCrrntPreselectionGear 5958;
BA_ "SigType" SG_ 2365374206 DlCltchTrnsSlctdPreselectionGear 1;
BA_ "SPN" SG_ 2365374206 DlCltchTrnsSlctdPreselectionGear 5957;
BA_ "SigType" SG_ 2365374206 DualClutchTransInputShaft2Speed 1;
BA_ "SPN" SG_ 2365374206 DualClutchTransInputShaft2Speed 5961;
BA_ "SigType" SG_ 2365374206 DualClutchTransInputShaft1Speed 1;
BA_ "SPN" SG_ 2365374206 DualClutchTransInputShaft1Speed 5960;
BA_ "SigType" SG_ 2566700542 AftrtrtmntTripDieselExhaustFluid 1;
BA_ "SPN" SG_ 2566700542 AftrtrtmntTripDieselExhaustFluid 6563;
BA_ "SigType" SG_ 2566700542 Aftrtrtmnt1TtlDslExhustFluidUsed 1;
BA_ "SPN" SG_ 2566700542 Aftrtrtmnt1TtlDslExhustFluidUsed 5963;
BA_ "SigType" SG_ 2566700286 Aftrtrtmnt2TtlDslExhustFluidUsed 1;
BA_ "SPN" SG_ 2566700286 Aftrtrtmnt2TtlDslExhustFluidUsed 5964;
BA_ "SigType" SG_ 2566700030 Aftrtrtmnt1DslExhstFldCtrlMd6309 5;
BA_ "SPN" SG_ 2566700030 Aftrtrtmnt1DslExhstFldCtrlMd6309 6309;
BA_ "SigType" SG_ 2566700030 Aftrtrtmnt1DslExhstFldCtrlMdlPwr 5;
BA_ "SPN" SG_ 2566700030 Aftrtrtmnt1DslExhstFldCtrlMdlPwr 5966;
BA_ "SigType" SG_ 2566700030 Aftrtrtmnt1DslExhstFldCtrlMdlRly 5;
BA_ "SPN" SG_ 2566700030 Aftrtrtmnt1DslExhstFldCtrlMdlRly 5965;
BA_ "SigType" SG_ 2566699774 Aftrtrtmnt2DslExhstFldCtrlMd6310 5;
BA_ "SPN" SG_ 2566699774 Aftrtrtmnt2DslExhstFldCtrlMd6310 6310;
BA_ "SigType" SG_ 2566699774 Aftrtrtmnt2DslExhstFldCtrlMdlPwr 5;
BA_ "SPN" SG_ 2566699774 Aftrtrtmnt2DslExhstFldCtrlMdlPwr 5968;
BA_ "SigType" SG_ 2566699774 Aftrtrtmnt2DslExhstFldCtrlMdlRly 5;
BA_ "SPN" SG_ 2566699774 Aftrtrtmnt2DslExhstFldCtrlMdlRly 5967;
BA_ "SigType" SG_ 2566699518 Aftrtrtmnt1DslPrtcltFltrTmTNxtAc 1;
BA_ "SPN" SG_ 2566699518 Aftrtrtmnt1DslPrtcltFltrTmTNxtAc 5978;
BA_ "SigType" SG_ 2566699262 Aftrtrtmnt2DslPrtcltFltrTmTNxtAc 1;
BA_ "SPN" SG_ 2566699262 Aftrtrtmnt2DslPrtcltFltrTmTNxtAc 5979;
BA_ "SigType" SG_ 2566698750 SLIBatteryPackHealth 1;
BA_ "SPN" SG_ 2566698750 SLIBatteryPackHealth 5983;
BA_ "SigType" SG_ 2566698750 SLIBatteryPackCapacity 1;
BA_ "SPN" SG_ 2566698750 SLIBatteryPackCapacity 5982;
BA_ "SigType" SG_ 2566698750 SLIBatteryPackStateOfCharge 1;
BA_ "SPN" SG_ 2566698750 SLIBatteryPackStateOfCharge 5981;
BA_ "SigType" SG_ 2566698494 FusedOutput29 4;
BA_ "SPN" SG_ 2566698494 FusedOutput29 6047;
BA_ "SigType" SG_ 2566698494 FusedOutput30 4;
BA_ "SPN" SG_ 2566698494 FusedOutput30 6046;
BA_ "SigType" SG_ 2566698494 FusedOutput31 4;
BA_ "SPN" SG_ 2566698494 FusedOutput31 6045;
BA_ "SigType" SG_ 2566698494 FusedOutput32 4;
BA_ "SPN" SG_ 2566698494 FusedOutput32 6044;
BA_ "SigType" SG_ 2566698494 FusedOutput25 4;
BA_ "SPN" SG_ 2566698494 FusedOutput25 6043;
BA_ "SigType" SG_ 2566698494 FusedOutput26 4;
BA_ "SPN" SG_ 2566698494 FusedOutput26 6042;
BA_ "SigType" SG_ 2566698494 FusedOutput27 4;
BA_ "SPN" SG_ 2566698494 FusedOutput27 6041;
BA_ "SigType" SG_ 2566698494 FusedOutput28 4;
BA_ "SPN" SG_ 2566698494 FusedOutput28 6040;
BA_ "SigType" SG_ 2566698494 FusedOutput21 4;
BA_ "SPN" SG_ 2566698494 FusedOutput21 6039;
BA_ "SigType" SG_ 2566698494 FusedOutput22 4;
BA_ "SPN" SG_ 2566698494 FusedOutput22 6038;
BA_ "SigType" SG_ 2566698494 FusedOutput23 4;
BA_ "SPN" SG_ 2566698494 FusedOutput23 6037;
BA_ "SigType" SG_ 2566698494 FusedOutput24 4;
BA_ "SPN" SG_ 2566698494 FusedOutput24 6036;
BA_ "SigType" SG_ 2566698494 FusedOutput17 4;
BA_ "SPN" SG_ 2566698494 FusedOutput17 6035;
BA_ "SigType" SG_ 2566698494 FusedOutput18 4;
BA_ "SPN" SG_ 2566698494 FusedOutput18 6034;
BA_ "SigType" SG_ 2566698494 FusedOutput19 4;
BA_ "SPN" SG_ 2566698494 FusedOutput19 6033;
BA_ "SigType" SG_ 2566698494 FusedOutput20 4;
BA_ "SPN" SG_ 2566698494 FusedOutput20 6032;
BA_ "SigType" SG_ 2566698494 FusedOutput13 4;
BA_ "SPN" SG_ 2566698494 FusedOutput13 6031;
BA_ "SigType" SG_ 2566698494 FusedOutput14 4;
BA_ "SPN" SG_ 2566698494 FusedOutput14 6030;
BA_ "SigType" SG_ 2566698494 FusedOutput15 4;
BA_ "SPN" SG_ 2566698494 FusedOutput15 6029;
BA_ "SigType" SG_ 2566698494 FusedOutput16 4;
BA_ "SPN" SG_ 2566698494 FusedOutput16 6028;
BA_ "SigType" SG_ 2566698494 FusedOutput9 4;
BA_ "SPN" SG_ 2566698494 FusedOutput9 6027;
BA_ "SigType" SG_ 2566698494 FusedOutput10 4;
BA_ "SPN" SG_ 2566698494 FusedOutput10 6026;
BA_ "SigType" SG_ 2566698494 FusedOutput11 4;
BA_ "SPN" SG_ 2566698494 FusedOutput11 6025;
BA_ "SigType" SG_ 2566698494 FusedOutput12 4;
BA_ "SPN" SG_ 2566698494 FusedOutput12 6024;
BA_ "SigType" SG_ 2566698494 FusedOutput5 4;
BA_ "SPN" SG_ 2566698494 FusedOutput5 6023;
BA_ "SigType" SG_ 2566698494 FusedOutput6 4;
BA_ "SPN" SG_ 2566698494 FusedOutput6 6022;
BA_ "SigType" SG_ 2566698494 FusedOutput7 4;
BA_ "SPN" SG_ 2566698494 FusedOutput7 6021;
BA_ "SigType" SG_ 2566698494 FusedOutput8 4;
BA_ "SPN" SG_ 2566698494 FusedOutput8 6020;
BA_ "SigType" SG_ 2566698494 FusedOutput1 4;
BA_ "SPN" SG_ 2566698494 FusedOutput1 6019;
BA_ "SigType" SG_ 2566698494 FusedOutput2 4;
BA_ "SPN" SG_ 2566698494 FusedOutput2 6018;
BA_ "SigType" SG_ 2566698494 FusedOutput3 4;
BA_ "SPN" SG_ 2566698494 FusedOutput3 6017;
BA_ "SigType" SG_ 2566698494 FusedOutput4 4;
BA_ "SPN" SG_ 2566698494 FusedOutput4 6016;
BA_ "SigType" SG_ 2559115006 WirelessSignalStrength2 1;
BA_ "SPN" SG_ 2559115006 WirelessSignalStrength2 5757;
BA_ "SPN" SG_ 2559115006 TransmitterID2 5756;
BA_ "SigType" SG_ 2559115006 RadioBeaconDirection 5;
BA_ "SPN" SG_ 2559115006 RadioBeaconDirection 5755;
BA_ "SigType" SG_ 2559115006 UnqBeaconMessageIdentifierNumber 1;
BA_ "SPN" SG_ 2559115006 UnqBeaconMessageIdentifierNumber 5754;
BA_ "SigType" SG_ 2566707454 Aftrtrtmnt1DslPrtcltFltr2StS5647 1;
BA_ "SPN" SG_ 2566707454 Aftrtrtmnt1DslPrtcltFltr2StS5647 5647;
BA_ "SigType" SG_ 2566707454 Aftrtrtmnt1DslPrtcltFltr2StS5646 1;
BA_ "SPN" SG_ 2566707454 Aftrtrtmnt1DslPrtcltFltr2StS5646 5646;
BA_ "SigType" SG_ 2566707454 Aftrtrtmnt1DslPrtcltFltr2StS5645 1;
BA_ "SPN" SG_ 2566707454 Aftrtrtmnt1DslPrtcltFltr2StS5645 5645;
BA_ "SigType" SG_ 2566707454 Aftrtrtmnt1DslPrtcltFltr2StSnsrA 1;
BA_ "SPN" SG_ 2566707454 Aftrtrtmnt1DslPrtcltFltr2StSnsrA 5644;
BA_ "SigType" SG_ 2566707198 Aftrtrtmnt1DslPrtcltFltr2StS5651 1;
BA_ "SPN" SG_ 2566707198 Aftrtrtmnt1DslPrtcltFltr2StS5651 5651;
BA_ "SigType" SG_ 2566707198 Aftrtrtmnt1DslPrtcltFltr2StS5650 1;
BA_ "SPN" SG_ 2566707198 Aftrtrtmnt1DslPrtcltFltr2StS5650 5650;
BA_ "SigType" SG_ 2566707198 Aftrtrtmnt1DslPrtcltFltr2StSnsrF 1;
BA_ "SPN" SG_ 2566707198 Aftrtrtmnt1DslPrtcltFltr2StSnsrF 5649;
BA_ "SigType" SG_ 2566707198 Aftrtrtmnt1DslPrtcltFltr2StSnsrA 1;
BA_ "SPN" SG_ 2566707198 Aftrtrtmnt1DslPrtcltFltr2StSnsrA 5648;
BA_ "SigType" SG_ 2566706942 Aftrtrtmnt1DslPrtcltFltr2StS5655 1;
BA_ "SPN" SG_ 2566706942 Aftrtrtmnt1DslPrtcltFltr2StS5655 5655;
BA_ "SigType" SG_ 2566706942 Aftrtrtmnt1DslPrtcltFltr2StS5654 1;
BA_ "SPN" SG_ 2566706942 Aftrtrtmnt1DslPrtcltFltr2StS5654 5654;
BA_ "SigType" SG_ 2566706942 Aftrtrtmnt1DslPrtcltFltr2StSnsrF 1;
BA_ "SPN" SG_ 2566706942 Aftrtrtmnt1DslPrtcltFltr2StSnsrF 5653;
BA_ "SigType" SG_ 2566706942 Aftrtrtmnt1DslPrtcltFltr2StSnsrA 1;
BA_ "SPN" SG_ 2566706942 Aftrtrtmnt1DslPrtcltFltr2StSnsrA 5652;
BA_ "SigType" SG_ 2559770366 HydrocarbonDoserPurgingRequired 5;
BA_ "SPN" SG_ 2559770366 HydrocarbonDoserPurgingRequired 5509;
BA_ "SPN" SG_ 2559770366 DiagnosticStatusOfHCDoser 5508;
BA_ "SigType" SG_ 2559770366 HCDoserInjectingStatus 5;
BA_ "SPN" SG_ 2559770366 HCDoserInjectingStatus 5507;
BA_ "SPN" SG_ 2559770366 HCDoserStatus 5506;
BA_ "SigType" SG_ 2559770366 RequestedFuelMassRate 1;
BA_ "SPN" SG_ 2559770366 RequestedFuelMassRate 5505;
BA_ "SigType" SG_ 2559704830 LubricationTimingCycleCmd 5;
BA_ "SPN" SG_ 2559704830 LubricationTimingCycleCmd 5514;
BA_ "SigType" SG_ 2559704830 LubricationPumpEnableCmd 5;
BA_ "SPN" SG_ 2559704830 LubricationPumpEnableCmd 5513;
BA_ "SPN" SG_ 2559704830 LubricationOperationModeSetCmd 5512;
BA_ "SPN" SG_ 2559704830 LubricationCycleSetCmd 5511;
BA_ "SigType" SG_ 2559704830 LubricationCycleModeLockCmd 5;
BA_ "SPN" SG_ 2559704830 LubricationCycleModeLockCmd 5510;
BA_ "SigType" SG_ 2559639294 SupplementalFanPowerHold 5;
BA_ "SPN" SG_ 2559639294 SupplementalFanPowerHold 5555;
BA_ "SigType" SG_ 2559639294 SupplementalFanSpeedCmd 1;
BA_ "SPN" SG_ 2559639294 SupplementalFanSpeedCmd 5554;
BA_ "SigType" SG_ 2559639294 SupplementalFanDirectionCmd 5;
BA_ "SPN" SG_ 2559639294 SupplementalFanDirectionCmd 5553;
BA_ "SigType" SG_ 2559639294 SupplementalFanEnableCmd 5;
BA_ "SPN" SG_ 2559639294 SupplementalFanEnableCmd 5552;
BA_ "SigType" SG_ 2559573758 ClntLvlEngPrtctnShtdwnOvrrideCmd 5;
BA_ "SPN" SG_ 2559573758 ClntLvlEngPrtctnShtdwnOvrrideCmd 5565;
BA_ "SigType" SG_ 2349530878 CruiseCtrlPauseCmd 5;
BA_ "SPN" SG_ 2349530878 CruiseCtrlPauseCmd 5605;
BA_ "SigType" SG_ 2349530878 CruiseCtrlResumeCmd 5;
BA_ "SPN" SG_ 2349530878 CruiseCtrlResumeCmd 5604;
BA_ "SigType" SG_ 2349530878 CruiseCtrlDisableCmd 5;
BA_ "SPN" SG_ 2349530878 CruiseCtrlDisableCmd 5603;
BA_ "SigType" SG_ 2566698238 SwitchedOutput29 5;
BA_ "SPN" SG_ 2566698238 SwitchedOutput29 6079;
BA_ "SigType" SG_ 2566698238 SwitchedOutput30 5;
BA_ "SPN" SG_ 2566698238 SwitchedOutput30 6078;
BA_ "SigType" SG_ 2566698238 SwitchedOutput31 5;
BA_ "SPN" SG_ 2566698238 SwitchedOutput31 6077;
BA_ "SigType" SG_ 2566698238 SwitchedOutput32 5;
BA_ "SPN" SG_ 2566698238 SwitchedOutput32 6076;
BA_ "SigType" SG_ 2566698238 SwitchedOutput25 5;
BA_ "SPN" SG_ 2566698238 SwitchedOutput25 6075;
BA_ "SigType" SG_ 2566698238 SwitchedOutput26 5;
BA_ "SPN" SG_ 2566698238 SwitchedOutput26 6074;
BA_ "SigType" SG_ 2566698238 SwitchedOutput27 5;
BA_ "SPN" SG_ 2566698238 SwitchedOutput27 6073;
BA_ "SigType" SG_ 2566698238 SwitchedOutput28 5;
BA_ "SPN" SG_ 2566698238 SwitchedOutput28 6072;
BA_ "SigType" SG_ 2566698238 SwitchedOutput21 5;
BA_ "SPN" SG_ 2566698238 SwitchedOutput21 6071;
BA_ "SigType" SG_ 2566698238 SwitchedOutput22 5;
BA_ "SPN" SG_ 2566698238 SwitchedOutput22 6070;
BA_ "SigType" SG_ 2566698238 SwitchedOutput23 5;
BA_ "SPN" SG_ 2566698238 SwitchedOutput23 6069;
BA_ "SigType" SG_ 2566698238 SwitchedOutput24 5;
BA_ "SPN" SG_ 2566698238 SwitchedOutput24 6068;
BA_ "SigType" SG_ 2566698238 SwitchedOutput17 5;
BA_ "SPN" SG_ 2566698238 SwitchedOutput17 6067;
BA_ "SigType" SG_ 2566698238 SwitchedOutput18 5;
BA_ "SPN" SG_ 2566698238 SwitchedOutput18 6066;
BA_ "SigType" SG_ 2566698238 SwitchedOutput19 5;
BA_ "SPN" SG_ 2566698238 SwitchedOutput19 6065;
BA_ "SigType" SG_ 2566698238 SwitchedOutput20 5;
BA_ "SPN" SG_ 2566698238 SwitchedOutput20 6064;
BA_ "SigType" SG_ 2566698238 SwitchedOutput13 5;
BA_ "SPN" SG_ 2566698238 SwitchedOutput13 6063;
BA_ "SigType" SG_ 2566698238 SwitchedOutput14 5;
BA_ "SPN" SG_ 2566698238 SwitchedOutput14 6062;
BA_ "SigType" SG_ 2566698238 SwitchedOutput15 5;
BA_ "SPN" SG_ 2566698238 SwitchedOutput15 6061;
BA_ "SigType" SG_ 2566698238 SwitchedOutput16 5;
BA_ "SPN" SG_ 2566698238 SwitchedOutput16 6060;
BA_ "SigType" SG_ 2566698238 SwitchedOutput9 5;
BA_ "SPN" SG_ 2566698238 SwitchedOutput9 6059;
BA_ "SigType" SG_ 2566698238 SwitchedOutput10 5;
BA_ "SPN" SG_ 2566698238 SwitchedOutput10 6058;
BA_ "SigType" SG_ 2566698238 SwitchedOutput11 5;
BA_ "SPN" SG_ 2566698238 SwitchedOutput11 6057;
BA_ "SigType" SG_ 2566698238 SwitchedOutput12 5;
BA_ "SPN" SG_ 2566698238 SwitchedOutput12 6056;
BA_ "SigType" SG_ 2566698238 SwitchedOutput5 5;
BA_ "SPN" SG_ 2566698238 SwitchedOutput5 6055;
BA_ "SigType" SG_ 2566698238 SwitchedOutput6 5;
BA_ "SPN" SG_ 2566698238 SwitchedOutput6 6054;
BA_ "SigType" SG_ 2566698238 SwitchedOutput7 5;
BA_ "SPN" SG_ 2566698238 SwitchedOutput7 6053;
BA_ "SigType" SG_ 2566698238 SwitchedOutput8 5;
BA_ "SPN" SG_ 2566698238 SwitchedOutput8 6052;
BA_ "SigType" SG_ 2566698238 SwitchedOutput1 5;
BA_ "SPN" SG_ 2566698238 SwitchedOutput1 6051;
BA_ "SigType" SG_ 2566698238 SwitchedOutput2 5;
BA_ "SPN" SG_ 2566698238 SwitchedOutput2 6050;
BA_ "SigType" SG_ 2566698238 SwitchedOutput3 5;
BA_ "SPN" SG_ 2566698238 SwitchedOutput3 6049;
BA_ "SigType" SG_ 2566698238 SwitchedOutput4 5;
BA_ "SPN" SG_ 2566698238 SwitchedOutput4 6048;
BA_ "SigType" SG_ 2566697982 FusedOutput32Current 1;
BA_ "SPN" SG_ 2566697982 FusedOutput32Current 6111;
BA_ "SigType" SG_ 2566697982 FusedOutput31Current 1;
BA_ "SPN" SG_ 2566697982 FusedOutput31Current 6110;
BA_ "SigType" SG_ 2566697982 FusedOutput30Current 1;
BA_ "SPN" SG_ 2566697982 FusedOutput30Current 6109;
BA_ "SigType" SG_ 2566697982 FusedOutput29Current 1;
BA_ "SPN" SG_ 2566697982 FusedOutput29Current 6108;
BA_ "SigType" SG_ 2566697982 FusedOutput28Current 1;
BA_ "SPN" SG_ 2566697982 FusedOutput28Current 6107;
BA_ "SigType" SG_ 2566697982 FusedOutput27Current 1;
BA_ "SPN" SG_ 2566697982 FusedOutput27Current 6106;
BA_ "SigType" SG_ 2566697982 FusedOutput26Current 1;
BA_ "SPN" SG_ 2566697982 FusedOutput26Current 6105;
BA_ "SigType" SG_ 2566697982 FusedOutput25Current 1;
BA_ "SPN" SG_ 2566697982 FusedOutput25Current 6104;
BA_ "SigType" SG_ 2566697982 FusedOutput24Current 1;
BA_ "SPN" SG_ 2566697982 FusedOutput24Current 6103;
BA_ "SigType" SG_ 2566697982 FusedOutput23Current 1;
BA_ "SPN" SG_ 2566697982 FusedOutput23Current 6102;
BA_ "SigType" SG_ 2566697982 FusedOutput22Current 1;
BA_ "SPN" SG_ 2566697982 FusedOutput22Current 6101;
BA_ "SigType" SG_ 2566697982 FusedOutput21Current 1;
BA_ "SPN" SG_ 2566697982 FusedOutput21Current 6100;
BA_ "SigType" SG_ 2566697982 FusedOutput20Current 1;
BA_ "SPN" SG_ 2566697982 FusedOutput20Current 6099;
BA_ "SigType" SG_ 2566697982 FusedOutput19Current 1;
BA_ "SPN" SG_ 2566697982 FusedOutput19Current 6098;
BA_ "SigType" SG_ 2566697982 FusedOutput18Current 1;
BA_ "SPN" SG_ 2566697982 FusedOutput18Current 6097;
BA_ "SigType" SG_ 2566697982 FusedOutput17Current 1;
BA_ "SPN" SG_ 2566697982 FusedOutput17Current 6096;
BA_ "SigType" SG_ 2566697982 FusedOutput16Current 1;
BA_ "SPN" SG_ 2566697982 FusedOutput16Current 6095;
BA_ "SigType" SG_ 2566697982 FusedOutput15Current 1;
BA_ "SPN" SG_ 2566697982 FusedOutput15Current 6094;
BA_ "SigType" SG_ 2566697982 FusedOutput14Current 1;
BA_ "SPN" SG_ 2566697982 FusedOutput14Current 6093;
BA_ "SigType" SG_ 2566697982 FusedOutput13Current 1;
BA_ "SPN" SG_ 2566697982 FusedOutput13Current 6092;
BA_ "SigType" SG_ 2566697982 FusedOutput12Current 1;
BA_ "SPN" SG_ 2566697982 FusedOutput12Current 6091;
BA_ "SigType" SG_ 2566697982 FusedOutput11Current 1;
BA_ "SPN" SG_ 2566697982 FusedOutput11Current 6090;
BA_ "SigType" SG_ 2566697982 FusedOutput10Current 1;
BA_ "SPN" SG_ 2566697982 FusedOutput10Current 6089;
BA_ "SigType" SG_ 2566697982 FusedOutput9Current 1;
BA_ "SPN" SG_ 2566697982 FusedOutput9Current 6088;
BA_ "SigType" SG_ 2566697982 FusedOutput8Current 1;
BA_ "SPN" SG_ 2566697982 FusedOutput8Current 6087;
BA_ "SigType" SG_ 2566697982 FusedOutput7Current 1;
BA_ "SPN" SG_ 2566697982 FusedOutput7Current 6086;
BA_ "SigType" SG_ 2566697982 FusedOutput6Current 1;
BA_ "SPN" SG_ 2566697982 FusedOutput6Current 6085;
BA_ "SigType" SG_ 2566697982 FusedOutput5Current 1;
BA_ "SPN" SG_ 2566697982 FusedOutput5Current 6084;
BA_ "SigType" SG_ 2566697982 FusedOutput4Current 1;
BA_ "SPN" SG_ 2566697982 FusedOutput4Current 6083;
BA_ "SigType" SG_ 2566697982 FusedOutput3Current 1;
BA_ "SPN" SG_ 2566697982 FusedOutput3Current 6082;
BA_ "SigType" SG_ 2566697982 FusedOutput2Current 1;
BA_ "SPN" SG_ 2566697982 FusedOutput2Current 6081;
BA_ "SigType" SG_ 2566697982 FusedOutput1Current 1;
BA_ "SPN" SG_ 2566697982 FusedOutput1Current 6080;
VAL_ 2147483936 ABSOffroadRequest 1 "ABS off-road switch on" 0 "ABS off-road switch off" ;
VAL_ 2499592190 TransShiftRail6ActuatorStatus 3 "not available" 2 "error" 1 "on" 0 "off" ;
VAL_ 2499592190 TransShiftRail5ActuatorStatus 3 "not available" 2 "error" 1 "on" 0 "off" ;
VAL_ 2499592190 TransShiftRail4ActuatorStatus 3 "not available" 2 "error" 1 "on" 0 "off" ;
VAL_ 2499592190 TransShiftRail3ActuatorStatus 3 "not available" 2 "error" 1 "on" 0 "off" ;
VAL_ 2499592190 TransShiftRail2ActuatorStatus 3 "not available" 2 "error" 1 "on" 0 "off" ;
VAL_ 2499592190 TransShiftRail1ActuatorStatus 3 "not available" 2 "error" 1 "on" 0 "off" ;
VAL_ 2499592190 TrnsClutch2CoolingActuatorStatus 3 "not available" 2 "error" 1 "on" 0 "off" ;
VAL_ 2499592190 TrnsClutch1CoolingActuatorStatus 3 "not available" 2 "error" 1 "on" 0 "off" ;
VAL_ 2566700030 Aftrtrtmnt1DslExhstFldCtrlMd6309 11 "Unavailable" 10 "Error" 1 "On: The ECU is powering the DEF dosing unit power supply" 0 "Off" ;
VAL_ 2566700030 Aftrtrtmnt1DslExhstFldCtrlMdlPwr 11 "Unavailable" 10 "Error" 1 "On: The ECU is powering the DEF dosing unit power supply" 0 "Off" ;
VAL_ 2566700030 Aftrtrtmnt1DslExhstFldCtrlMdlRly 11 "Unavailable" 10 "Error" 1 "On: The ECU is powering the DEF dosing unit relay" 0 "Off" ;
VAL_ 2566699774 Aftrtrtmnt2DslExhstFldCtrlMd6310 11 "Unavailable" 10 "Error" 1 "On: The ECU is powering the DEF dosing unit power supply" 0 "Off" ;
VAL_ 2566699774 Aftrtrtmnt2DslExhstFldCtrlMdlPwr 11 "Unavailable" 10 "Error" 1 "On: The ECU is powering the DEF dosing unit power supply" 0 "Off" ;
VAL_ 2566699774 Aftrtrtmnt2DslExhstFldCtrlMdlRly 11 "Unavailable" 10 "Error" 1 "On: The ECU is powering the DEF dosing unit relay" 0 "Off" ;
VAL_ 2566698494 FusedOutput29 3 "Take no action" 2 "Reserved" 1 "Output powered" 0 "Output not powered" ;
VAL_ 2566698494 FusedOutput30 3 "Take no action" 2 "Reserved" 1 "Output powered" 0 "Output not powered" ;
VAL_ 2566698494 FusedOutput31 3 "Take no action" 2 "Reserved" 1 "Output powered" 0 "Output not powered" ;
VAL_ 2566698494 FusedOutput32 3 "Take no action" 2 "Reserved" 1 "Output powered" 0 "Output not powered" ;
VAL_ 2566698494 FusedOutput25 3 "Take no action" 2 "Reserved" 1 "Output powered" 0 "Output not powered" ;
VAL_ 2566698494 FusedOutput26 3 "Take no action" 2 "Reserved" 1 "Output powered" 0 "Output not powered" ;
VAL_ 2566698494 FusedOutput27 3 "Take no action" 2 "Reserved" 1 "Output powered" 0 "Output not powered" ;
VAL_ 2566698494 FusedOutput28 3 "Take no action" 2 "Reserved" 1 "Output powered" 0 "Output not powered" ;
VAL_ 2566698494 FusedOutput21 3 "Take no action" 2 "Reserved" 1 "Output powered" 0 "Output not powered" ;
VAL_ 2566698494 FusedOutput22 3 "Take no action" 2 "Reserved" 1 "Output powered" 0 "Output not powered" ;
VAL_ 2566698494 FusedOutput23 3 "Take no action" 2 "Reserved" 1 "Output powered" 0 "Output not powered" ;
VAL_ 2566698494 FusedOutput24 3 "Take no action" 2 "Reserved" 1 "Output powered" 0 "Output not powered" ;
VAL_ 2566698494 FusedOutput17 3 "Take no action" 2 "Reserved" 1 "Output powered" 0 "Output not powered" ;
VAL_ 2566698494 FusedOutput18 3 "Take no action" 2 "Reserved" 1 "Output powered" 0 "Output not powered" ;
VAL_ 2566698494 FusedOutput19 3 "Take no action" 2 "Reserved" 1 "Output powered" 0 "Output not powered" ;
VAL_ 2566698494 FusedOutput20 3 "Take no action" 2 "Reserved" 1 "Output powered" 0 "Output not powered" ;
VAL_ 2566698494 FusedOutput13 3 "Take no action" 2 "Reserved" 1 "Output powered" 0 "Output not powered" ;
VAL_ 2566698494 FusedOutput14 3 "Take no action" 2 "Reserved" 1 "Output powered" 0 "Output not powered" ;
VAL_ 2566698494 FusedOutput15 3 "Take no action" 2 "Reserved" 1 "Output powered" 0 "Output not powered" ;
VAL_ 2566698494 FusedOutput16 3 "Take no action" 2 "Reserved" 1 "Output powered" 0 "Output not powered" ;
VAL_ 2566698494 FusedOutput9 3 "Take no action" 2 "Reserved" 1 "Output powered" 0 "Output not powered" ;
VAL_ 2566698494 FusedOutput10 3 "Take no action" 2 "Reserved" 1 "Output powered" 0 "Output not powered" ;
VAL_ 2566698494 FusedOutput11 3 "Take no action" 2 "Reserved" 1 "Output powered" 0 "Output not powered" ;
VAL_ 2566698494 FusedOutput12 3 "Take no action" 2 "Reserved" 1 "Output powered" 0 "Output not powered" ;
VAL_ 2566698494 FusedOutput5 3 "Take no action" 2 "Reserved" 1 "Output powered" 0 "Output not powered" ;
VAL_ 2566698494 FusedOutput6 3 "Take no action" 2 "Reserved" 1 "Output powered" 0 "Output not powered" ;
VAL_ 2566698494 FusedOutput7 3 "Take no action" 2 "Reserved" 1 "Output powered" 0 "Output not powered" ;
VAL_ 2566698494 FusedOutput8 3 "Take no action" 2 "Reserved" 1 "Output powered" 0 "Output not powered" ;
VAL_ 2566698494 FusedOutput1 3 "Take no action" 2 "Reserved" 1 "Output powered" 0 "Output not powered" ;
VAL_ 2566698494 FusedOutput2 3 "Take no action" 2 "Reserved" 1 "Output powered" 0 "Output not powered" ;
VAL_ 2566698494 FusedOutput3 3 "Take no action" 2 "Reserved" 1 "Output powered" 0 "Output not powered" ;
VAL_ 2566698494 FusedOutput4 3 "Take no action" 2 "Reserved" 1 "Output powered" 0 "Output not powered" ;
VAL_ 2559115006 RadioBeaconDirection 3 "Don't Care" 2 "Reserved" 1 "Beacon Received Acknowledgement - Acknowledgement from wireless device" 0 "Beacon Request - Beacon request coming from an ECU" ;
VAL_ 2559770366 HydrocarbonDoserPurgingRequired 3 "Not available" 2 "Purging required  urgent" 1 "Purging required  less urgent" 0 "Purging not required" ;
VAL_ 2559770366 DiagnosticStatusOfHCDoser 7 "Not available" 6 "Error    System test has failed" 1 "Internal system test is in process" 0 "System test has executed and passed or System test has not yet executed" ;
VAL_ 2559770366 HCDoserInjectingStatus 3 "Not available" 2 "Error" 1 "Injecting active" 0 "Injecting not active" ;
VAL_ 2559770366 HCDoserStatus 7 "Not available" 6 "Error" 5 "SAE reserved" 4 "SAE reserved" 3 "HC doser enabled waiting for regeneration" 2 "SAE reserved" 1 "HC doser active" 0 "HC doser disabled" ;
VAL_ 2559704830 LubricationTimingCycleCmd 3 "Take no action" 2 "Reserved" 1 "Enable" 0 "Pause" ;
VAL_ 2559704830 LubricationPumpEnableCmd 3 "Take no action" 2 "Reserved" 1 "Reset pump operation" 0 "No action Normal pump operation" ;
VAL_ 2559704830 LubricationOperationModeSetCmd 7 "Take no action" 4 "Test Mode  3" 3 "Test Mode  2" 2 "Test Mode  1" 1 "Manual Service Mode" 0 "Automatic Mode" ;
VAL_ 2559704830 LubricationCycleSetCmd 7 "No action" 2 "Cycle mode  3 Highest Lubrication Frequency" 1 "Cycle mode  2" 0 "Cycle mode  1 Lowest Lubrication Frequency" ;
VAL_ 2559704830 LubricationCycleModeLockCmd 3 "No action" 2 "Reserved" 1 "Locked" 0 "Not Locked" ;
VAL_ 2559639294 SupplementalFanPowerHold 3 "Dont Care/Take no action" 2 "Reserved" 1 "Enable" 0 "Disable" ;
VAL_ 2559639294 SupplementalFanDirectionCmd 3 "Dont care/take no action leave function as is" 2 "Reserved" 1 "Reverse" 0 "Forward" ;
VAL_ 2559639294 SupplementalFanEnableCmd 3 "Dont Care/Take no action" 2 "Reserved" 1 "Enable" 0 "Disable" ;
VAL_ 2559573758 ClntLvlEngPrtctnShtdwnOvrrideCmd 3 "Dont care/take no action" 2 "Reserved" 1 "Enable engine protection shutdown override due to low coolant level" 0 "Disable engine protection shutdown override due to low coolant level" ;
VAL_ 2349530878 CruiseCtrlPauseCmd 3 "Dont care/take no action" 2 "Reserved" 1 "Cruise Control is not allowed" 0 "Cruise Control is allowed" ;
VAL_ 2349530878 CruiseCtrlResumeCmd 3 "Dont Care/take no action" 2 "Reserved" 1 "Cruise Control Resume Requested" 0 "Cruise Control Resume not Requested" ;
VAL_ 2349530878 CruiseCtrlDisableCmd 3 "Dont care/take no action" 2 "Reserved" 1 "Cruise Control is not allowed" 0 "Cruise Control is allowed" ;
VAL_ 2566698238 SwitchedOutput29 3 "Take no action" 2 "Reserved" 1 "Output on" 0 "Output off" ;
VAL_ 2566698238 SwitchedOutput30 3 "Take no action" 2 "Reserved" 1 "Output on" 0 "Output off" ;
VAL_ 2566698238 SwitchedOutput31 3 "Take no action" 2 "Reserved" 1 "Output on" 0 "Output off" ;
VAL_ 2566698238 SwitchedOutput32 3 "Take no action" 2 "Reserved" 1 "Output on" 0 "Output off" ;
VAL_ 2566698238 SwitchedOutput25 3 "Take no action" 2 "Reserved" 1 "Output on" 0 "Output off" ;
VAL_ 2566698238 SwitchedOutput26 3 "Take no action" 2 "Reserved" 1 "Output on" 0 "Output off" ;
VAL_ 2566698238 SwitchedOutput27 3 "Take no action" 2 "Reserved" 1 "Output on" 0 "Output off" ;
VAL_ 2566698238 SwitchedOutput28 3 "Take no action" 2 "Reserved" 1 "Output on" 0 "Output off" ;
VAL_ 2566698238 SwitchedOutput21 3 "Take no action" 2 "Reserved" 1 "Output on" 0 "Output off" ;
VAL_ 2566698238 SwitchedOutput22 3 "Take no action" 2 "Reserved" 1 "Output on" 0 "Output off" ;
VAL_ 2566698238 SwitchedOutput23 3 "Take no action" 2 "Reserved" 1 "Output on" 0 "Output off" ;
VAL_ 2566698238 SwitchedOutput24 3 "Take no action" 2 "Reserved" 1 "Output on" 0 "Output off" ;
VAL_ 2566698238 SwitchedOutput17 3 "Take no action" 2 "Reserved" 1 "Output on" 0 "Output off" ;
VAL_ 2566698238 SwitchedOutput18 3 "Take no action" 2 "Reserved" 1 "Output on" 0 "Output off" ;
VAL_ 2566698238 SwitchedOutput19 3 "Take no action" 2 "Reserved" 1 "Output on" 0 "Output off" ;
VAL_ 2566698238 SwitchedOutput20 3 "Take no action" 2 "Reserved" 1 "Output on" 0 "Output off" ;
VAL_ 2566698238 SwitchedOutput13 3 "Take no action" 2 "Reserved" 1 "Output on" 0 "Output off" ;
VAL_ 2566698238 SwitchedOutput14 3 "Take no action" 2 "Reserved" 1 "Output on" 0 "Output off" ;
VAL_ 2566698238 SwitchedOutput15 3 "Take no action" 2 "Reserved" 1 "Output on" 0 "Output off" ;
VAL_ 2566698238 SwitchedOutput16 3 "Take no action" 2 "Reserved" 1 "Output on" 0 "Output off" ;
VAL_ 2566698238 SwitchedOutput9 3 "Take no action" 2 "Reserved" 1 "Output on" 0 "Output off" ;
VAL_ 2566698238 SwitchedOutput10 3 "Take no action" 2 "Reserved" 1 "Output on" 0 "Output off" ;
VAL_ 2566698238 SwitchedOutput11 3 "Take no action" 2 "Reserved" 1 "Output on" 0 "Output off" ;
VAL_ 2566698238 SwitchedOutput12 3 "Take no action" 2 "Reserved" 1 "Output on" 0 "Output off" ;
VAL_ 2566698238 SwitchedOutput5 3 "Take no action" 2 "Reserved" 1 "Output on" 0 "Output off" ;
VAL_ 2566698238 SwitchedOutput6 3 "Take no action" 2 "Reserved" 1 "Output on" 0 "Output off" ;
VAL_ 2566698238 SwitchedOutput7 3 "Take no action" 2 "Reserved" 1 "Output on" 0 "Output off" ;
VAL_ 2566698238 SwitchedOutput8 3 "Take no action" 2 "Reserved" 1 "Output on" 0 "Output off" ;
VAL_ 2566698238 SwitchedOutput1 3 "Take no action" 2 "Reserved" 1 "Output on" 0 "Output off" ;
VAL_ 2566698238 SwitchedOutput2 3 "Take no action" 2 "Reserved" 1 "Output on" 0 "Output off" ;
VAL_ 2566698238 SwitchedOutput3 3 "Take no action" 2 "Reserved" 1 "Output on" 0 "Output off" ;
VAL_ 2566698238 SwitchedOutput4 3 "Take no action" 2 "Reserved" 1 "Output on" 0 "Output off" ;
